VERSION ""

NS_ :

BS_:

BU_: ETH

BO_ 1445 DIR_alertLog: 8 Vector__XXX
 SG_ DIR_alertID M : 0|8@1+ (1,0) [0|0] "" Vector__XXX
 SG_ DIR_alertState : 15|1@1+ (1,0) [0|0] "" Vector__XXX
 SG_ DIR_a001_thermalWarning_H m1 : 16|1@1+ (1,0) [0|0] "" Vector__XXX
 SG_ DIR_a002_thermalWarning_H m2 : 16|1@1+ (1,0) [0|0] "" Vector__XXX
 SG_ DIR_a003_thermalWarning_H m3 : 16|1@1+ (1,0) [0|0] "" Vector__XXX
 SG_ DIR_a007_phaseAcurrent m7 : 16|8@1+ (8,0) [0|0] "" Vector__XXX
 SG_ DIR_a010_sccReset m10 : 16|1@1+ (1,0) [0|0] "" Vector__XXX
 SG_ DIR_a011_reason m11 : 16|3@1+ (1,0) [0|0] "" Vector__XXX
 SG_ DIR_a013_address m13 : 16|32@1+ (1,0) [0|0] "" Vector__XXX
 SG_ DIR_a014_motorSpeed m14 : 16|14@1- (2,0) [0|0] "" Vector__XXX
 SG_ DIR_a015_hwLatchTestFailed m15 : 16|1@1+ (1,0) [0|0] "" Vector__XXX
 SG_ DIR_a016_newSafeState m16 : 16|2@1+ (1,0) [0|0] "" Vector__XXX
 SG_ DIR_a024_vBat m24 : 16|8@1+ (2,0) [0|0] "" Vector__XXX
 SG_ DIR_a025_Ia m25 : 16|16@1- (0.1,0) [0|0] "" Vector__XXX
 SG_ DIR_a026_Ib m26 : 16|16@1- (0.1,0) [0|0] "" Vector__XXX
 SG_ DIR_a027_Ic m27 : 16|16@1- (0.1,0) [0|0] "" Vector__XXX
 SG_ DIR_a028_phaseAirms m28 : 16|16@1+ (1,0) [0|0] "" Vector__XXX
 SG_ DIR_a029_phaseBirms m29 : 16|16@1+ (1,0) [0|0] "" Vector__XXX
 SG_ DIR_a030_phaseCirms m30 : 16|16@1+ (1,0) [0|0] "" Vector__XXX
 SG_ DIR_a031_phaseAoffset m31 : 16|15@1- (0.002,0) [0|0] "" Vector__XXX
 SG_ DIR_a032_phaseBoffset m32 : 16|15@1- (0.002,0) [0|0] "" Vector__XXX
 SG_ DIR_a033_phaseAcurrent m33 : 16|16@1- (1,0) [0|0] "" Vector__XXX
 SG_ DIR_a034_phaseBcurrent m34 : 16|16@1- (1,0) [0|0] "" Vector__XXX
 SG_ DIR_a035_phaseAerror m35 : 16|1@1+ (1,0) [0|0] "" Vector__XXX
 SG_ DIR_a036_busVoltage m36 : 16|16@1+ (0.1,0) [0|0] "" Vector__XXX
 SG_ DIR_a037_busVoltage m37 : 16|16@1+ (0.1,0) [0|0] "" Vector__XXX
 SG_ DIR_a038_vBMS m38 : 16|13@1+ (0.2,0) [0|0] "" Vector__XXX
 SG_ DIR_a040_torque m40 : 16|1@1+ (1,0) [0|0] "" Vector__XXX
 SG_ DIR_a041_uartRxDataAvailable m41 : 16|1@1+ (1,0) [0|0] "" Vector__XXX
 SG_ DIR_a042_inletTemp m42 : 16|10@1+ (0.25,-60) [0|0] "" Vector__XXX
 SG_ DIR_a043_outletTemp m43 : 16|16@1- (0.1,0) [0|0] "" Vector__XXX
 SG_ DIR_a044_outletTemp m44 : 16|16@1- (0.1,0) [0|0] "" Vector__XXX
 SG_ DIR_a045_inletTemp m45 : 16|10@1+ (0.25,-60) [0|0] "" Vector__XXX
 SG_ DIR_a046_statorTemp1 m46 : 16|16@1- (0.1,0) [0|0] "" Vector__XXX
 SG_ DIR_a047_statorTemp1 m47 : 16|16@1- (0.1,0) [0|0] "" Vector__XXX
 SG_ DIR_a048_statorTemp2 m48 : 16|16@1- (0.1,0) [0|0] "" Vector__XXX
 SG_ DIR_a049_statorTemp1 m49 : 16|8@1- (1,80) [0|0] "" Vector__XXX
 SG_ DIR_a050_statorTemp1 m50 : 16|16@1- (0.1,0) [0|0] "" Vector__XXX
 SG_ DIR_a052_torque m52 : 16|1@1+ (1,0) [0|0] "" Vector__XXX
 SG_ DIR_a054_outletTemp m54 : 16|16@1- (0.1,0) [0|0] "" Vector__XXX
 SG_ DIR_a055_parameterDI m55 : 16|13@1- (0.25,0) [0|0] "" Vector__XXX
 SG_ DIR_a056_pcbTemp m56 : 16|16@1- (0.1,0) [0|0] "" Vector__XXX
 SG_ DIR_a057_pcbTemp m57 : 16|16@1- (0.1,0) [0|0] "" Vector__XXX
 SG_ DIR_a058_pcbTemp m58 : 16|10@1+ (0.25,-60) [0|0] "" Vector__XXX
 SG_ DIR_a059_heatsinkTemp m59 : 16|16@1- (0.1,0) [0|0] "" Vector__XXX
 SG_ DIR_a060_heatsinkTemp m60 : 16|16@1- (0.1,0) [0|0] "" Vector__XXX
 SG_ DIR_a061_sensor m61 : 16|2@1+ (1,0) [0|0] "" Vector__XXX
 SG_ DIR_a062_limpReason m62 : 16|6@1+ (1,0) [0|0] "" Vector__XXX
 SG_ DIR_a064_interventionType m64 : 16|4@1+ (1,0) [0|0] "" Vector__XXX
 SG_ DIR_a065_canID m65 : 16|16@1+ (1,0) [0|0] "" Vector__XXX
 SG_ DIR_a066_badValue1 m66 : 16|16@1+ (1,0) [0|0] "" Vector__XXX
 SG_ DIR_a067_canID m67 : 16|16@1+ (1,0) [0|0] "" Vector__XXX
 SG_ DIR_a069_motorSpeed m69 : 16|16@1- (1,0) [0|0] "" Vector__XXX
 SG_ DIR_a070_serviceDataId m70 : 16|16@1+ (1,0) [0|0] "" Vector__XXX
 SG_ DIR_a071_busVslopeLimit m71 : 16|16@1+ (0.1,0) [0|0] "" Vector__XXX
 SG_ DIR_a072_reason m72 : 16|2@1+ (1,0) [0|0] "" Vector__XXX
 SG_ DIR_a073_motorSpeedrpm m73 : 16|16@1- (1,0) [0|0] "" Vector__XXX
 SG_ DIR_a074_brazeFailCount m74 : 16|8@1+ (1,0) [0|0] "" Vector__XXX
 SG_ DIR_a075_motorSpeed m75 : 16|16@1+ (1,0) [0|0] "" Vector__XXX
 SG_ DIR_a076_lvSupplyV m76 : 16|16@1+ (0.001,0) [0|0] "" Vector__XXX
 SG_ DIR_a077_lvSupplyV m77 : 16|16@1+ (0.001,0) [0|0] "" Vector__XXX
 SG_ DIR_a078_adcRefChan m78 : 16|4@1+ (1,0) [0|0] "" Vector__XXX
 SG_ DIR_a079_adcRefChan m79 : 16|4@1+ (1,0) [0|0] "" Vector__XXX
 SG_ DIR_a084_lowDataValue m84 : 16|32@1+ (1,0) [0|0] "" Vector__XXX
 SG_ DIR_a087_gtwCarConfig m87 : 16|1@1+ (1,0) [0|0] "" Vector__XXX
 SG_ DIR_a088_uiChassisControl m88 : 16|1@1+ (1,0) [0|0] "" Vector__XXX
 SG_ DIR_a090_reason m90 : 16|1@1+ (1,0) [0|0] "" Vector__XXX
 SG_ DIR_a091_ESP_brakeTorque m91 : 16|1@1+ (1,0) [0|0] "" Vector__XXX
 SG_ DIR_a092_bmsStatus m92 : 16|1@1+ (1,0) [0|0] "" Vector__XXX
 SG_ DIR_a093_mailboxID m93 : 16|16@1+ (1,0) [0|0] "" Vector__XXX
 SG_ DIR_a094_canID m94 : 16|12@1+ (1,0) [0|0] "" Vector__XXX
 SG_ DIR_a095_mailboxID m95 : 16|16@1+ (1,0) [0|0] "" Vector__XXX
 SG_ DIR_a096_const_fast m96 : 16|1@1+ (1,0) [0|0] "" Vector__XXX
 SG_ DIR_a097_errorType m97 : 16|3@1+ (1,0) [0|0] "" Vector__XXX
 SG_ DIR_a098_pwmCount m98 : 16|16@1+ (1,0) [0|0] "" Vector__XXX
 SG_ DIR_a099_watchdogReset m99 : 16|1@1+ (1,0) [0|0] "" Vector__XXX
 SG_ DIR_a101_highDataValue m101 : 16|32@1+ (1,0) [0|0] "" Vector__XXX
 SG_ DIR_a103_fluidTorDeltaT m103 : 16|8@1- (2.0078740157480315,68.26771653543307) [0|0] "" Vector__XXX
 SG_ DIR_a107_fpgaVersion m107 : 16|16@1+ (1,0) [0|0] "" Vector__XXX
 SG_ DIR_a108_fromState m108 : 16|8@1+ (1,0) [0|0] "" Vector__XXX
 SG_ DIR_a110_EPBL_status m110 : 16|1@1+ (1,0) [0|0] "" Vector__XXX
 SG_ DIR_a111_phAcalib m111 : 16|16@1+ (1,0) [0|0] "" Vector__XXX
 SG_ DIR_a112_pwmSwitching m112 : 16|1@1+ (1,0) [0|0] "" Vector__XXX
 SG_ DIR_a113_heatsink1Temp m113 : 16|16@1- (0.1,0) [0|0] "" Vector__XXX
 SG_ DIR_a117_torque m117 : 16|1@1+ (1,0) [0|0] "" Vector__XXX
 SG_ DIR_a119_hvpFaults m119 : 16|1@1+ (1,0) [0|0] "" Vector__XXX
 SG_ DIR_a120_dcLinkInfo m120 : 16|1@1+ (1,0) [0|0] "" Vector__XXX
 SG_ DIR_a121_badRegReason m121 : 16|3@1+ (1,0) [0|0] "" Vector__XXX
 SG_ DIR_a122_taskID m122 : 16|5@1+ (1,0) [0|0] "" Vector__XXX
 SG_ DIR_a123_lossReason m123 : 16|3@1+ (1,0) [0|0] "" Vector__XXX
 SG_ DIR_a126_limpReason m126 : 16|6@1+ (1,0) [0|0] "" Vector__XXX
 SG_ DIR_a127_gpoReason m127 : 16|4@1+ (1,0) [0|0] "" Vector__XXX
 SG_ DIR_a128_expectedFPGAversion m128 : 16|16@1+ (1,0) [0|0] "" Vector__XXX
 SG_ DIR_a133_capacitorTemp m133 : 16|16@1- (0.1,0) [0|0] "" Vector__XXX
 SG_ DIR_a134_wheelSpeedDiffFrL m134 : 16|12@1- (0.0625,0) [0|0] "" Vector__XXX
 SG_ DIR_a136_spiError_BL m136 : 16|1@1+ (1,0) [0|0] "" Vector__XXX
 SG_ DIR_a142_lashAngle m142 : 16|10@1+ (0.06,0) [0|0] "" Vector__XXX
 SG_ DIR_a144_autopilot m144 : 16|1@1+ (1,0) [0|0] "" Vector__XXX
 SG_ DIR_a147_overtorque1UsedCount m147 : 16|8@1+ (1,0) [0|0] "" Vector__XXX
 SG_ DIR_a148_initialHeatsinkT m148 : 16|6@1+ (3,-40) [0|0] "" Vector__XXX
 SG_ DIR_a149_flow m149 : 16|8@1+ (0.1,0) [0|0] "" Vector__XXX
 SG_ DIR_a150_vBatRawMinusFiltered m150 : 16|10@1- (1,0) [0|0] "" Vector__XXX
 SG_ DIR_a151_torqueMotor m151 : 16|16@1- (0.25,0) [0|0] "" Vector__XXX
 SG_ DIR_a152_errorType m152 : 16|3@1+ (1,0) [0|0] "" Vector__XXX
 SG_ DIR_a153_oilFlow m153 : 16|8@1+ (0.1,0) [0|0] "" Vector__XXX
 SG_ DIR_a154_motorRPM m154 : 16|16@1- (1,0) [0|0] "" Vector__XXX
 SG_ DIR_a155_sensors m155 : 16|1@1+ (1,0) [0|0] "" Vector__XXX
 SG_ DIR_a156_initialSafeState m156 : 16|2@1+ (1,0) [0|0] "" Vector__XXX
 SG_ DIR_a157_RCM_inertial1 m157 : 16|1@1+ (1,0) [0|0] "" Vector__XXX
 SG_ DIR_a158_IBST_party1 m158 : 16|1@1+ (1,0) [0|0] "" Vector__XXX
 SG_ DIR_a160_vBatRawMinusFiltered m160 : 16|10@1- (1,0) [0|0] "" Vector__XXX
 SG_ DIR_a161_EPAS3P_sysStatus m161 : 16|1@1+ (1,0) [0|0] "" Vector__XXX
 SG_ DIR_a162_normalFetBurnIn m162 : 16|8@1+ (2,0) [0|0] "" Vector__XXX
 SG_ DIR_a172_statorTemp1 m172 : 16|16@1- (0.1,0) [0|0] "" Vector__XXX
 SG_ DIR_a173_phaseADetected m173 : 16|1@1+ (1,0) [0|0] "" Vector__XXX
 SG_ DIR_a177_storedValue m177 : 16|16@1+ (0.0001,0) [0|0] "" Vector__XXX
 SG_ DIR_a202_reason m202 : 16|4@1+ (1,0) [0|0] "" Vector__XXX
 SG_ DIR_a225_hs1Implausible m225 : 16|1@1+ (1,0) [0|0] "" Vector__XXX
 SG_ DIR_a229_vBMS m229 : 16|13@1+ (0.2,0) [0|0] "" Vector__XXX
 SG_ DIR_a233_missedMsgCount m233 : 16|16@1+ (1,0) [0|0] "" Vector__XXX
 SG_ DIR_a234_PCS_dcdcStatus m234 : 16|1@1+ (1,0) [0|0] "" Vector__XXX
 SG_ DIR_a236_states m236 : 16|1@1+ (1,0) [0|0] "" Vector__XXX
 SG_ DIR_a240_shortedSwitches m240 : 16|6@1+ (1,0) [0|0] "" Vector__XXX
 SG_ DIR_a241_statorEndWindingTemp m241 : 16|8@1- (1,88) [0|0] "" Vector__XXX
 SG_ DIR_a242_RotorOffset m242 : 16|1@1+ (1,0) [0|0] "" Vector__XXX
 SG_ DIR_a243_logId m243 : 16|4@1+ (1,0) [0|0] "" Vector__XXX
 SG_ DIR_a244_desatHighSide m244 : 16|1@1+ (1,0) [0|0] "" Vector__XXX
 SG_ DIR_a245_singleSwitchShort m245 : 16|1@1+ (1,0) [0|0] "" Vector__XXX
 SG_ DIR_a246_atSpeedDIResetCount m246 : 16|4@1+ (1,-1) [0|0] "" Vector__XXX
 SG_ DIR_a247_rotorOffsetEst m247 : 16|10@1- (0.05,0) [0|0] "" Vector__XXX
 SG_ DIR_a249_statorResistanceEst m249 : 16|11@1+ (5e-05,0) [0|0] "" Vector__XXX
 SG_ DIR_a250_voltage m250 : 16|12@1+ (0.01,0) [0|0] "" Vector__XXX
 SG_ DIR_a251_oilFlow m251 : 16|8@1+ (0.1,0) [0|0] "" Vector__XXX
 SG_ DIR_a253_voltage m253 : 16|14@1+ (0.002,0) [0|0] "" Vector__XXX
 SG_ DIR_a254_voltage m254 : 16|14@1+ (0.005,0) [0|0] "" Vector__XXX
 SG_ DIR_a001_thermalShutdown_H m1 : 17|1@1+ (1,0) [0|0] "" Vector__XXX
 SG_ DIR_a002_thermalShutdown_H m2 : 17|1@1+ (1,0) [0|0] "" Vector__XXX
 SG_ DIR_a003_thermalShutdown_H m3 : 17|1@1+ (1,0) [0|0] "" Vector__XXX
 SG_ DIR_a010_hibernate m10 : 17|1@1+ (1,0) [0|0] "" Vector__XXX
 SG_ DIR_a015_hwOpenCircuitTestFailed m15 : 17|1@1+ (1,0) [0|0] "" Vector__XXX
 SG_ DIR_a035_phaseBerror m35 : 17|1@1+ (1,0) [0|0] "" Vector__XXX
 SG_ DIR_a040_capability m40 : 17|1@1+ (1,0) [0|0] "" Vector__XXX
 SG_ DIR_a041_SDC_status_MIA m41 : 17|1@1+ (1,0) [0|0] "" Vector__XXX
 SG_ DIR_a052_capability m52 : 17|1@1+ (1,0) [0|0] "" Vector__XXX
 SG_ DIR_a087_gtwTime m87 : 17|1@1+ (1,0) [0|0] "" Vector__XXX
 SG_ DIR_a088_uiCruiseControl m88 : 17|1@1+ (1,0) [0|0] "" Vector__XXX
 SG_ DIR_a091_ESP_wheelSpeeds m91 : 17|1@1+ (1,0) [0|0] "" Vector__XXX
 SG_ DIR_a092_bmsDriveLimits m92 : 17|1@1+ (1,0) [0|0] "" Vector__XXX
 SG_ DIR_a096_text_fast m96 : 17|1@1+ (1,0) [0|0] "" Vector__XXX
 SG_ DIR_a099_thread1Hz m99 : 17|1@1+ (1,0) [0|0] "" Vector__XXX
 SG_ DIR_a110_EPBR_status m110 : 17|1@1+ (1,0) [0|0] "" Vector__XXX
 SG_ DIR_a112_gdicResetLine m112 : 17|1@1+ (1,0) [0|0] "" Vector__XXX
 SG_ DIR_a117_slaveCommand m117 : 17|1@1+ (1,0) [0|0] "" Vector__XXX
 SG_ DIR_a136_crcError_BL m136 : 17|1@1+ (1,0) [0|0] "" Vector__XXX
 SG_ DIR_a144_chassisType m144 : 17|1@1+ (1,0) [0|0] "" Vector__XXX
 SG_ DIR_a155_coolant m155 : 17|1@1+ (1,0) [0|0] "" Vector__XXX
 SG_ DIR_a157_RCM_inertial2 m157 : 17|1@1+ (1,0) [0|0] "" Vector__XXX
 SG_ DIR_a158_BUS1_IBST_status m158 : 17|1@1+ (1,0) [0|0] "" Vector__XXX
 SG_ DIR_a161_EPAS3P_angleCalib m161 : 17|1@1+ (1,0) [0|0] "" Vector__XXX
 SG_ DIR_a173_phaseBDetected m173 : 17|1@1+ (1,0) [0|0] "" Vector__XXX
 SG_ DIR_a225_hs2Implausible m225 : 17|1@1+ (1,0) [0|0] "" Vector__XXX
 SG_ DIR_a242_RotorFlux m242 : 17|1@1+ (1,0) [0|0] "" Vector__XXX
 SG_ DIR_a244_desatLowSide m244 : 17|1@1+ (1,0) [0|0] "" Vector__XXX
 SG_ DIR_a245_busShort m245 : 17|1@1+ (1,0) [0|0] "" Vector__XXX
 SG_ DIR_a001_undervoltVL_H m1 : 18|1@1+ (1,0) [0|0] "" Vector__XXX
 SG_ DIR_a002_undervoltVL_H m2 : 18|1@1+ (1,0) [0|0] "" Vector__XXX
 SG_ DIR_a003_undervoltVL_H m3 : 18|1@1+ (1,0) [0|0] "" Vector__XXX
 SG_ DIR_a010_hwBist m10 : 18|1@1+ (1,0) [0|0] "" Vector__XXX
 SG_ DIR_a015_hwIrTestFailed m15 : 18|1@1+ (1,0) [0|0] "" Vector__XXX
 SG_ DIR_a016_oldSafeState m16 : 18|2@1+ (1,0) [0|0] "" Vector__XXX
 SG_ DIR_a035_phaseCerror m35 : 18|1@1+ (1,0) [0|0] "" Vector__XXX
 SG_ DIR_a040_power m40 : 18|1@1+ (1,0) [0|0] "" Vector__XXX
 SG_ DIR_a041_diUartRxVersion m41 : 18|4@1+ (1,0) [0|0] "" Vector__XXX
 SG_ DIR_a052_power m52 : 18|1@1+ (1,0) [0|0] "" Vector__XXX
 SG_ DIR_a061_reason m61 : 18|1@1+ (1,0) [0|0] "" Vector__XXX
 SG_ DIR_a087_gtwUpdateStatus m87 : 18|1@1+ (1,0) [0|0] "" Vector__XXX
 SG_ DIR_a088_uiDriverAssistMapData m88 : 18|1@1+ (1,0) [0|0] "" Vector__XXX
 SG_ DIR_a090_state m90 : 18|1@1+ (1,0) [0|0] "" Vector__XXX
 SG_ DIR_a091_ESP_wheelRotation m91 : 18|1@1+ (1,0) [0|0] "" Vector__XXX
 SG_ DIR_a092_bmsHvBusStatus m92 : 18|1@1+ (1,0) [0|0] "" Vector__XXX
 SG_ DIR_a096_text_flash m96 : 18|1@1+ (1,0) [0|0] "" Vector__XXX
 SG_ DIR_a099_thread10Hz m99 : 18|1@1+ (1,0) [0|0] "" Vector__XXX
 SG_ DIR_a110_EPBL_autonomyHealth m110 : 18|1@1+ (1,0) [0|0] "" Vector__XXX
 SG_ DIR_a112_allOffSafeState m112 : 18|1@1+ (1,0) [0|0] "" Vector__XXX
 SG_ DIR_a117_power m117 : 18|1@1+ (1,0) [0|0] "" Vector__XXX
 SG_ DIR_a136_busyError_BL m136 : 18|1@1+ (1,0) [0|0] "" Vector__XXX
 SG_ DIR_a144_drivetrainType m144 : 18|1@1+ (1,0) [0|0] "" Vector__XXX
 SG_ DIR_a155_LVPowerState m155 : 18|1@1+ (1,0) [0|0] "" Vector__XXX
 SG_ DIR_a156_observation m156 : 18|4@1+ (1,0) [0|0] "" Vector__XXX
 SG_ DIR_a158_BUS2_IBST_status m158 : 18|1@1+ (1,0) [0|0] "" Vector__XXX
 SG_ DIR_a173_phaseCDetected m173 : 18|1@1+ (1,0) [0|0] "" Vector__XXX
 SG_ DIR_a225_fluidImplausible m225 : 18|1@1+ (1,0) [0|0] "" Vector__XXX
 SG_ DIR_a242_ResolverError m242 : 18|1@1+ (1,0) [0|0] "" Vector__XXX
 SG_ DIR_a244_singleSwitchShort m244 : 18|1@1+ (1,0) [0|0] "" Vector__XXX
 SG_ DIR_a245_unsuccessfulSafeState m245 : 18|1@1+ (1,0) [0|0] "" Vector__XXX
 SG_ DIR_a001_undervoltVH_H m1 : 19|1@1+ (1,0) [0|0] "" Vector__XXX
 SG_ DIR_a002_undervoltVH_H m2 : 19|1@1+ (1,0) [0|0] "" Vector__XXX
 SG_ DIR_a003_undervoltVH_H m3 : 19|1@1+ (1,0) [0|0] "" Vector__XXX
 SG_ DIR_a010_nmiWatchdog m10 : 19|1@1+ (1,0) [0|0] "" Vector__XXX
 SG_ DIR_a011_phaseAHigh m11 : 19|1@1+ (1,0) [0|0] "" Vector__XXX
 SG_ DIR_a015_swHighsideTestFailed m15 : 19|1@1+ (1,0) [0|0] "" Vector__XXX
 SG_ DIR_a035_standbyCurrent m35 : 19|1@1+ (1,0) [0|0] "" Vector__XXX
 SG_ DIR_a040_status m40 : 19|1@1+ (1,0) [0|0] "" Vector__XXX
 SG_ DIR_a052_status m52 : 19|1@1+ (1,0) [0|0] "" Vector__XXX
 SG_ DIR_a087_gearControl m87 : 19|1@1+ (1,0) [0|0] "" Vector__XXX
 SG_ DIR_a088_uiPowertrainControl m88 : 19|1@1+ (1,0) [0|0] "" Vector__XXX
 SG_ DIR_a090_locState m90 : 19|1@1+ (1,0) [0|0] "" Vector__XXX
 SG_ DIR_a091_ESP_motorLimits m91 : 19|1@1+ (1,0) [0|0] "" Vector__XXX
 SG_ DIR_a092_bmsPowerAvailable m92 : 19|1@1+ (1,0) [0|0] "" Vector__XXX
 SG_ DIR_a096_mem_data m96 : 19|1@1+ (1,0) [0|0] "" Vector__XXX
 SG_ DIR_a099_thread100Hz m99 : 19|1@1+ (1,0) [0|0] "" Vector__XXX
 SG_ DIR_a110_EPBR_autonomyHealth m110 : 19|1@1+ (1,0) [0|0] "" Vector__XXX
 SG_ DIR_a112_ls3psSafeState m112 : 19|1@1+ (1,0) [0|0] "" Vector__XXX
 SG_ DIR_a117_slaveCommand2 m117 : 19|1@1+ (1,0) [0|0] "" Vector__XXX
 SG_ DIR_a121_torqueDelta m121 : 19|13@1- (0.25,0) [0|0] "" Vector__XXX
 SG_ DIR_a123_busVoltage m123 : 19|6@1+ (4,250) [0|0] "" Vector__XXX
 SG_ DIR_a136_spiError_BH m136 : 19|1@1+ (1,0) [0|0] "" Vector__XXX
 SG_ DIR_a144_packEnergy m144 : 19|1@1+ (1,0) [0|0] "" Vector__XXX
 SG_ DIR_a155_vehicleStatus m155 : 19|1@1+ (1,0) [0|0] "" Vector__XXX
 SG_ DIR_a173_phaseAPeriodViolation1 m173 : 19|1@1+ (1,0) [0|0] "" Vector__XXX
 SG_ DIR_a225_hsDeltaImplausible m225 : 19|1@1+ (1,0) [0|0] "" Vector__XXX
 SG_ DIR_a244_flybackFault m244 : 19|1@1+ (1,0) [0|0] "" Vector__XXX
 SG_ DIR_a245_lowSpeedShort m245 : 19|1@1+ (1,0) [0|0] "" Vector__XXX
 SG_ DIR_a001_sense_H m1 : 20|1@1+ (1,0) [0|0] "" Vector__XXX
 SG_ DIR_a002_sense_H m2 : 20|1@1+ (1,0) [0|0] "" Vector__XXX
 SG_ DIR_a003_sense_H m3 : 20|1@1+ (1,0) [0|0] "" Vector__XXX
 SG_ DIR_a010_watchdog m10 : 20|1@1+ (1,0) [0|0] "" Vector__XXX
 SG_ DIR_a011_phaseALow m11 : 20|1@1+ (1,0) [0|0] "" Vector__XXX
 SG_ DIR_a015_swLowsideTestFailed m15 : 20|1@1+ (1,0) [0|0] "" Vector__XXX
 SG_ DIR_a016_gateDriveFaultLine m16 : 20|1@1+ (1,0) [0|0] "" Vector__XXX
 SG_ DIR_a035_unbalancedCurrent m35 : 20|1@1+ (1,0) [0|0] "" Vector__XXX
 SG_ DIR_a040_capability2 m40 : 20|1@1+ (1,0) [0|0] "" Vector__XXX
 SG_ DIR_a052_capability2 m52 : 20|1@1+ (1,0) [0|0] "" Vector__XXX
 SG_ DIR_a064_torqueCmdState m64 : 20|4@1+ (1,0) [0|0] "" Vector__XXX
 SG_ DIR_a087_carState m87 : 20|1@1+ (1,0) [0|0] "" Vector__XXX
 SG_ DIR_a088_uiVehicleModes m88 : 20|1@1+ (1,0) [0|0] "" Vector__XXX
 SG_ DIR_a090_state2 m90 : 20|1@1+ (1,0) [0|0] "" Vector__XXX
 SG_ DIR_a091_ESP_offsets m91 : 20|1@1+ (1,0) [0|0] "" Vector__XXX
 SG_ DIR_a092_bmsBmbMinMax m92 : 20|1@1+ (1,0) [0|0] "" Vector__XXX
 SG_ DIR_a096_mem_regs m96 : 20|1@1+ (1,0) [0|0] "" Vector__XXX
 SG_ DIR_a099_thread1kHz m99 : 20|1@1+ (1,0) [0|0] "" Vector__XXX
 SG_ DIR_a112_hs3psSafeState m112 : 20|1@1+ (1,0) [0|0] "" Vector__XXX
 SG_ DIR_a117_speed m117 : 20|1@1+ (1,0) [0|0] "" Vector__XXX
 SG_ DIR_a136_crcError_BH m136 : 20|1@1+ (1,0) [0|0] "" Vector__XXX
 SG_ DIR_a144_packPerformanceDeviation m144 : 20|1@1+ (1,0) [0|0] "" Vector__XXX
 SG_ DIR_a155_status m155 : 20|1@1+ (1,0) [0|0] "" Vector__XXX
 SG_ DIR_a173_phaseAPeriodViolation2 m173 : 20|1@1+ (1,0) [0|0] "" Vector__XXX
 SG_ DIR_a202_movement m202 : 20|9@1+ (0.005,0) [0|0] "" Vector__XXX
 SG_ DIR_a244_postShortTestFailed m244 : 20|1@1+ (1,0) [0|0] "" Vector__XXX
 SG_ DIR_a245_doubleSwitchShort m245 : 20|1@1+ (1,0) [0|0] "" Vector__XXX
 SG_ DIR_a246_didPMCauseASC m246 : 20|1@1+ (1,0) [0|0] "" Vector__XXX
 SG_ DIR_a001_desat_H m1 : 21|1@1+ (1,0) [0|0] "" Vector__XXX
 SG_ DIR_a002_desat_H m2 : 21|1@1+ (1,0) [0|0] "" Vector__XXX
 SG_ DIR_a003_desat_H m3 : 21|1@1+ (1,0) [0|0] "" Vector__XXX
 SG_ DIR_a010_clockFailNmi m10 : 21|1@1+ (1,0) [0|0] "" Vector__XXX
 SG_ DIR_a011_phaseBHigh m11 : 21|1@1+ (1,0) [0|0] "" Vector__XXX
 SG_ DIR_a015_armedFailed m15 : 21|1@1+ (1,0) [0|0] "" Vector__XXX
 SG_ DIR_a016_ascMonitor m16 : 21|1@1+ (1,0) [0|0] "" Vector__XXX
 SG_ DIR_a035_wontMoveCurrent m35 : 21|1@1+ (1,0) [0|0] "" Vector__XXX
 SG_ DIR_a040_hvStatus m40 : 21|1@1+ (1,0) [0|0] "" Vector__XXX
 SG_ DIR_a052_hvStatus m52 : 21|1@1+ (1,0) [0|0] "" Vector__XXX
 SG_ DIR_a088_uiTrackModeSettings m88 : 21|1@1+ (1,0) [0|0] "" Vector__XXX
 SG_ DIR_a090_state4 m90 : 21|1@1+ (1,0) [0|0] "" Vector__XXX
 SG_ DIR_a091_ESP_status m91 : 21|1@1+ (1,0) [0|0] "" Vector__XXX
 SG_ DIR_a092_bmsSocStatus m92 : 21|1@1+ (1,0) [0|0] "" Vector__XXX
 SG_ DIR_a096_boot_flash m96 : 21|1@1+ (1,0) [0|0] "" Vector__XXX
 SG_ DIR_a112_modulationIndex m112 : 21|11@1+ (0.00048828125,0) [0|0] "" Vector__XXX
 SG_ DIR_a117_chassisControl m117 : 21|1@1+ (1,0) [0|0] "" Vector__XXX
 SG_ DIR_a136_busyError_BH m136 : 21|1@1+ (1,0) [0|0] "" Vector__XXX
 SG_ DIR_a144_performancePackage m144 : 21|1@1+ (1,0) [0|0] "" Vector__XXX
 SG_ DIR_a155_leftDoorStatus m155 : 21|1@1+ (1,0) [0|0] "" Vector__XXX
 SG_ DIR_a173_phaseBPeriodViolation1 m173 : 21|1@1+ (1,0) [0|0] "" Vector__XXX
 SG_ DIR_a244_udsSelfTest m244 : 21|1@1+ (1,0) [0|0] "" Vector__XXX
 SG_ DIR_a245_gateDriveSupplyFault m245 : 21|1@1+ (1,0) [0|0] "" Vector__XXX
 SG_ DIR_a246_currentSensorRational m246 : 21|1@1+ (1,0) [0|0] "" Vector__XXX
 SG_ DIR_a001_overvoltVL_H m1 : 22|1@1+ (1,0) [0|0] "" Vector__XXX
 SG_ DIR_a002_overvoltVL_H m2 : 22|1@1+ (1,0) [0|0] "" Vector__XXX
 SG_ DIR_a003_overvoltVL_H m3 : 22|1@1+ (1,0) [0|0] "" Vector__XXX
 SG_ DIR_a010_ramUncErrorNmi m10 : 22|1@1+ (1,0) [0|0] "" Vector__XXX
 SG_ DIR_a011_phaseBLow m11 : 22|1@1+ (1,0) [0|0] "" Vector__XXX
 SG_ DIR_a015_lightSenseIrrational m15 : 22|1@1+ (1,0) [0|0] "" Vector__XXX
 SG_ DIR_a016_uncontrolledRegenZone m16 : 22|1@1+ (1,0) [0|0] "" Vector__XXX
 SG_ DIR_a035_reportingPhase m35 : 22|2@1+ (1,0) [0|0] "" Vector__XXX
 SG_ DIR_a040_temperature m40 : 22|1@1+ (1,0) [0|0] "" Vector__XXX
 SG_ DIR_a052_temperature m52 : 22|1@1+ (1,0) [0|0] "" Vector__XXX
 SG_ DIR_a088_mcuDriverLimits m88 : 22|1@1+ (1,0) [0|0] "" Vector__XXX
 SG_ DIR_a091_ESP_party3 m91 : 22|1@1+ (1,0) [0|0] "" Vector__XXX
 SG_ DIR_a092_bmsThermalStatus m92 : 22|1@1+ (1,0) [0|0] "" Vector__XXX
 SG_ DIR_a117_systemStatus m117 : 22|1@1+ (1,0) [0|0] "" Vector__XXX
 SG_ DIR_a136_spiError_CL m136 : 22|1@1+ (1,0) [0|0] "" Vector__XXX
 SG_ DIR_a144_vdcType m144 : 22|1@1+ (1,0) [0|0] "" Vector__XXX
 SG_ DIR_a148_initialJunctionT m148 : 22|6@1+ (3,-40) [0|0] "" Vector__XXX
 SG_ DIR_a155_rightDoorStatus m155 : 22|1@1+ (1,0) [0|0] "" Vector__XXX
 SG_ DIR_a156_phaseAPolarity m156 : 22|2@1+ (1,0) [0|0] "" Vector__XXX
 SG_ DIR_a173_phaseBPeriodViolation2 m173 : 22|1@1+ (1,0) [0|0] "" Vector__XXX
 SG_ DIR_a240_primaryPattern m240 : 22|6@1+ (1,0) [0|0] "" Vector__XXX
 SG_ DIR_a245_unexpectedCurrent m245 : 22|1@1+ (1,0) [0|0] "" Vector__XXX
 SG_ DIR_a246_observerDetectedLS3PS m246 : 22|1@1+ (1,0) [0|0] "" Vector__XXX
 SG_ DIR_a001_overvoltVH_H m1 : 23|1@1+ (1,0) [0|0] "" Vector__XXX
 SG_ DIR_a002_overvoltVH_H m2 : 23|1@1+ (1,0) [0|0] "" Vector__XXX
 SG_ DIR_a003_overvoltVH_H m3 : 23|1@1+ (1,0) [0|0] "" Vector__XXX
 SG_ DIR_a010_flashUncErrorNmi m10 : 23|1@1+ (1,0) [0|0] "" Vector__XXX
 SG_ DIR_a011_phaseCHigh m11 : 23|1@1+ (1,0) [0|0] "" Vector__XXX
 SG_ DIR_a016_pedalMonitorPreWatchdog m16 : 23|1@1+ (1,0) [0|0] "" Vector__XXX
 SG_ DIR_a088_vehicleControl2 m88 : 23|1@1+ (1,0) [0|0] "" Vector__XXX
 SG_ DIR_a091_ESP_redundantBrakingStatus m91 : 23|1@1+ (1,0) [0|0] "" Vector__XXX
 SG_ DIR_a092_bmsCtrStatus m92 : 23|1@1+ (1,0) [0|0] "" Vector__XXX
 SG_ DIR_a117_temperature m117 : 23|1@1+ (1,0) [0|0] "" Vector__XXX
 SG_ DIR_a136_crcError_CL m136 : 23|1@1+ (1,0) [0|0] "" Vector__XXX
 SG_ DIR_a144_brakeHWType m144 : 23|1@1+ (1,0) [0|0] "" Vector__XXX
 SG_ DIR_a155_vcleftSwitchStatus m155 : 23|1@1+ (1,0) [0|0] "" Vector__XXX
 SG_ DIR_a173_phaseCPeriodViolation1 m173 : 23|1@1+ (1,0) [0|0] "" Vector__XXX
 SG_ DIR_a246_hvIsGood m246 : 23|1@1+ (1,0) [0|0] "" Vector__XXX
 SG_ DIR_a001_undervoltVCC_H m1 : 24|1@1+ (1,0) [0|0] "" Vector__XXX
 SG_ DIR_a002_undervoltVCC_H m2 : 24|1@1+ (1,0) [0|0] "" Vector__XXX
 SG_ DIR_a003_undervoltVCC_H m3 : 24|1@1+ (1,0) [0|0] "" Vector__XXX
 SG_ DIR_a007_phaseBcurrent m7 : 24|8@1+ (8,0) [0|0] "" Vector__XXX
 SG_ DIR_a010_cpu1signMismatchNmi m10 : 24|1@1+ (1,0) [0|0] "" Vector__XXX
 SG_ DIR_a011_phaseCLow m11 : 24|1@1+ (1,0) [0|0] "" Vector__XXX
 SG_ DIR_a015_lightSenseV m15 : 24|6@1+ (0.1,0) [0|0] "" Vector__XXX
 SG_ DIR_a016_motorRPM m16 : 24|16@1- (1,0) [0|0] "" Vector__XXX
 SG_ DIR_a024_failReason m24 : 24|3@1+ (1,0) [0|0] "" Vector__XXX
 SG_ DIR_a035_noDriveCurrent m35 : 24|1@1+ (1,0) [0|0] "" Vector__XXX
 SG_ DIR_a041_sdcUartRxVersion m41 : 24|4@1+ (1,0) [0|0] "" Vector__XXX
 SG_ DIR_a049_statorTemp2 m49 : 24|8@1- (1,80) [0|0] "" Vector__XXX
 SG_ DIR_a061_phTemp m61 : 24|16@1- (0.1,0) [0|0] "" Vector__XXX
 SG_ DIR_a074_speed1Type m74 : 24|2@1+ (1,0) [0|0] "" Vector__XXX
 SG_ DIR_a078_adcRefLowAvg m78 : 24|16@1+ (1,0) [0|0] "" Vector__XXX
 SG_ DIR_a079_adcRefHighAvg m79 : 24|16@1+ (1,0) [0|0] "" Vector__XXX
 SG_ DIR_a088_semiControls m88 : 24|1@1+ (1,0) [0|0] "" Vector__XXX
 SG_ DIR_a092_bmsVoltageRegGain m92 : 24|1@1+ (1,0) [0|0] "" Vector__XXX
 SG_ DIR_a096_word1 m96 : 24|16@1+ (1,0) [0|0] "" Vector__XXX
 SG_ DIR_a097_lineNumber m97 : 24|16@1+ (1,0) [0|0] "" Vector__XXX
 SG_ DIR_a099_cpuUsage1Hz m99 : 24|8@1+ (1,0) [0|0] "" Vector__XXX
 SG_ DIR_a103_noFlowDetected m103 : 24|1@1+ (1,0) [0|0] "" Vector__XXX
 SG_ DIR_a108_toState m108 : 24|8@1+ (1,0) [0|0] "" Vector__XXX
 SG_ DIR_a117_vehicle m117 : 24|1@1+ (1,0) [0|0] "" Vector__XXX
 SG_ DIR_a122_stackUsed m122 : 24|16@1+ (1,0) [0|0] "" Vector__XXX
 SG_ DIR_a127_temp m127 : 24|16@1- (0.1,0) [0|0] "" Vector__XXX
 SG_ DIR_a136_busyError_CL m136 : 24|1@1+ (1,0) [0|0] "" Vector__XXX
 SG_ DIR_a144_inverterHardware m144 : 24|1@1+ (1,0) [0|0] "" Vector__XXX
 SG_ DIR_a147_overtorque2UsedCount m147 : 24|10@1+ (1,0) [0|0] "" Vector__XXX
 SG_ DIR_a149_voltage m149 : 24|8@1+ (0.1,0) [0|0] "" Vector__XXX
 SG_ DIR_a152_frameId m152 : 24|8@1+ (1,0) [0|0] "" Vector__XXX
 SG_ DIR_a153_oilTemperature m153 : 24|8@1+ (1,-40) [0|0] "" Vector__XXX
 SG_ DIR_a155_restraintStatus m155 : 24|1@1+ (1,0) [0|0] "" Vector__XXX
 SG_ DIR_a156_phaseBPolarity m156 : 24|2@1+ (1,0) [0|0] "" Vector__XXX
 SG_ DIR_a162_additionalFetBurnIn m162 : 24|8@1+ (2,0) [0|0] "" Vector__XXX
 SG_ DIR_a173_phaseCPeriodViolation2 m173 : 24|1@1+ (1,0) [0|0] "" Vector__XXX
 SG_ DIR_a241_rotorMaxMagnetTemp m241 : 24|8@1- (1,88) [0|0] "" Vector__XXX
 SG_ DIR_a243_triggerEvent m243 : 24|6@1+ (1,0) [0|0] "" Vector__XXX
 SG_ DIR_a244_irSensorV m244 : 24|6@1+ (0.1,0) [0|0] "" Vector__XXX
 SG_ DIR_a246_lvIsGood m246 : 24|1@1+ (1,0) [0|0] "" Vector__XXX
 SG_ DIR_a251_oilTemperature m251 : 24|8@1+ (1,-40) [0|0] "" Vector__XXX
 SG_ DIR_a001_asynchStop_H m1 : 25|1@1+ (1,0) [0|0] "" Vector__XXX
 SG_ DIR_a002_asynchStop_H m2 : 25|1@1+ (1,0) [0|0] "" Vector__XXX
 SG_ DIR_a003_asynchStop_H m3 : 25|1@1+ (1,0) [0|0] "" Vector__XXX
 SG_ DIR_a010_cpu2signMismatchNmi m10 : 25|1@1+ (1,0) [0|0] "" Vector__XXX
 SG_ DIR_a011_regAddress m11 : 25|5@1+ (1,0) [0|0] "" Vector__XXX
 SG_ DIR_a035_phaseDifference m35 : 25|7@1+ (1,0) [0|0] "" Vector__XXX
 SG_ DIR_a088_uiDriveSystemsDebug m88 : 25|1@1+ (1,0) [0|0] "" Vector__XXX
 SG_ DIR_a092_bmsPackConfig m92 : 25|1@1+ (1,0) [0|0] "" Vector__XXX
 SG_ DIR_a103_lowFlowDetected m103 : 25|1@1+ (1,0) [0|0] "" Vector__XXX
 SG_ DIR_a123_badFlux m123 : 25|7@1+ (0.0015,0) [0|0] "" Vector__XXX
 SG_ DIR_a136_spiError_CH m136 : 25|1@1+ (1,0) [0|0] "" Vector__XXX
 SG_ DIR_a144_cabinPTCHeaterType m144 : 25|1@1+ (1,0) [0|0] "" Vector__XXX
 SG_ DIR_a155_systemStatus m155 : 25|1@1+ (1,0) [0|0] "" Vector__XXX
 SG_ DIR_a246_codeBranch m246 : 25|2@1+ (1,0) [0|0] "" Vector__XXX
 SG_ DIR_a001_remoteRegError_H m1 : 26|1@1+ (1,0) [0|0] "" Vector__XXX
 SG_ DIR_a002_remoteRegError_H m2 : 26|1@1+ (1,0) [0|0] "" Vector__XXX
 SG_ DIR_a003_remoteRegError_H m3 : 26|1@1+ (1,0) [0|0] "" Vector__XXX
 SG_ DIR_a010_pieVectErrorNmi m10 : 26|1@1+ (1,0) [0|0] "" Vector__XXX
 SG_ DIR_a042_outletTemp m42 : 26|10@1+ (0.25,-60) [0|0] "" Vector__XXX
 SG_ DIR_a045_outletTemp m45 : 26|10@1+ (0.25,-60) [0|0] "" Vector__XXX
 SG_ DIR_a058_outletTemp m58 : 26|10@1+ (0.25,-60) [0|0] "" Vector__XXX
 SG_ DIR_a074_speed2Type m74 : 26|2@1+ (1,0) [0|0] "" Vector__XXX
 SG_ DIR_a092_bmsSystemStatus m92 : 26|1@1+ (1,0) [0|0] "" Vector__XXX
 SG_ DIR_a103_fluidImplausible m103 : 26|1@1+ (1,0) [0|0] "" Vector__XXX
 SG_ DIR_a136_crcError_CH m136 : 26|1@1+ (1,0) [0|0] "" Vector__XXX
 SG_ DIR_a144_frunkLatchType m144 : 26|1@1+ (1,0) [0|0] "" Vector__XXX
 SG_ DIR_a156_phaseCPolarity m156 : 26|2@1+ (1,0) [0|0] "" Vector__XXX
 SG_ DIR_a001_undervoltVDD_H m1 : 27|1@1+ (1,0) [0|0] "" Vector__XXX
 SG_ DIR_a002_undervoltVDD_H m2 : 27|1@1+ (1,0) [0|0] "" Vector__XXX
 SG_ DIR_a003_undervoltVDD_H m3 : 27|1@1+ (1,0) [0|0] "" Vector__XXX
 SG_ DIR_a010_sysDbgNmi m10 : 27|1@1+ (1,0) [0|0] "" Vector__XXX
 SG_ DIR_a024_state m24 : 27|4@1+ (1,0) [0|0] "" Vector__XXX
 SG_ DIR_a103_inverterTemp m103 : 27|8@1- (2.0078740157480315,68.26771653543307) [0|0] "" Vector__XXX
 SG_ DIR_a136_busyError_CH m136 : 27|1@1+ (1,0) [0|0] "" Vector__XXX
 SG_ DIR_a144_platformMaxBusVoltage m144 : 27|1@1+ (1,0) [0|0] "" Vector__XXX
 SG_ DIR_a155_liftgateStatus m155 : 27|1@1+ (1,0) [0|0] "" Vector__XXX
 SG_ DIR_a001_overvoltVDD_H m1 : 28|1@1+ (1,0) [0|0] "" Vector__XXX
 SG_ DIR_a002_overvoltVDD_H m2 : 28|1@1+ (1,0) [0|0] "" Vector__XXX
 SG_ DIR_a003_overvoltVDD_H m3 : 28|1@1+ (1,0) [0|0] "" Vector__XXX
 SG_ DIR_a010_rlNmi m10 : 28|1@1+ (1,0) [0|0] "" Vector__XXX
 SG_ DIR_a094_errorType m94 : 28|3@1+ (1,0) [0|0] "" Vector__XXX
 SG_ DIR_a134_wheelSpeedDiffFrR m134 : 28|12@1- (0.0625,0) [0|0] "" Vector__XXX
 SG_ DIR_a136_spiError_AL m136 : 28|1@1+ (1,0) [0|0] "" Vector__XXX
 SG_ DIR_a144_oilPump1HwType m144 : 28|1@1+ (1,0) [0|0] "" Vector__XXX
 SG_ DIR_a148_timeBelow50degC m148 : 28|9@1+ (30,0) [0|0] "" Vector__XXX
 SG_ DIR_a156_powerPolarity m156 : 28|2@1+ (1,0) [0|0] "" Vector__XXX
 SG_ DIR_a240_secondaryPattern m240 : 28|6@1+ (1,0) [0|0] "" Vector__XXX
 SG_ DIR_a250_reason m250 : 28|2@1+ (1,0) [0|0] "" Vector__XXX
 SG_ DIR_a001_localRegError_H m1 : 29|1@1+ (1,0) [0|0] "" Vector__XXX
 SG_ DIR_a002_localRegError_H m2 : 29|1@1+ (1,0) [0|0] "" Vector__XXX
 SG_ DIR_a003_localRegError_H m3 : 29|1@1+ (1,0) [0|0] "" Vector__XXX
 SG_ DIR_a010_ovfNmi m10 : 29|1@1+ (1,0) [0|0] "" Vector__XXX
 SG_ DIR_a136_crcError_AL m136 : 29|1@1+ (1,0) [0|0] "" Vector__XXX
 SG_ DIR_a144_oilPump2HwType m144 : 29|1@1+ (1,0) [0|0] "" Vector__XXX
 SG_ DIR_a229_reason m229 : 29|1@1+ (1,0) [0|0] "" Vector__XXX
 SG_ DIR_a001_spiError_H m1 : 30|1@1+ (1,0) [0|0] "" Vector__XXX
 SG_ DIR_a002_spiError_H m2 : 30|1@1+ (1,0) [0|0] "" Vector__XXX
 SG_ DIR_a003_spiError_H m3 : 30|1@1+ (1,0) [0|0] "" Vector__XXX
 SG_ DIR_a014_adState m14 : 30|2@1+ (1,0) [0|0] "" Vector__XXX
 SG_ DIR_a015_pyroSenseIrrational m15 : 30|1@1+ (1,0) [0|0] "" Vector__XXX
 SG_ DIR_a117_odometerStatus m117 : 30|1@1+ (1,0) [0|0] "" Vector__XXX
 SG_ DIR_a136_busyError_AL m136 : 30|1@1+ (1,0) [0|0] "" Vector__XXX
 SG_ DIR_a144_heatsinkType m144 : 30|1@1+ (1,0) [0|0] "" Vector__XXX
 SG_ DIR_a156_highCurrentMagnitude m156 : 30|1@1+ (1,0) [0|0] "" Vector__XXX
 SG_ DIR_a244_gateDriveICUndervoltage m244 : 30|1@1+ (1,0) [0|0] "" Vector__XXX
 SG_ DIR_a253_reason m253 : 30|2@1+ (1,0) [0|0] "" Vector__XXX
 SG_ DIR_a254_vBat m254 : 30|10@1+ (2,0) [0|0] "" Vector__XXX
 SG_ DIR_a001_deadtimeError_H m1 : 31|1@1+ (1,0) [0|0] "" Vector__XXX
 SG_ DIR_a002_deadtimeError_H m2 : 31|1@1+ (1,0) [0|0] "" Vector__XXX
 SG_ DIR_a003_deadtimeError_H m3 : 31|1@1+ (1,0) [0|0] "" Vector__XXX
 SG_ DIR_a024_Ia m24 : 31|7@1- (22.5,0) [0|0] "" Vector__XXX
 SG_ DIR_a136_spiError_AH m136 : 31|1@1+ (1,0) [0|0] "" Vector__XXX
 SG_ DIR_a144_softPerformanceLimit m144 : 31|1@1+ (1,0) [0|0] "" Vector__XXX
 SG_ DIR_a156_highMotorSpeed m156 : 31|1@1+ (1,0) [0|0] "" Vector__XXX
 SG_ DIR_a244_plausibleSingleSwitchShortOnly m244 : 31|1@1+ (1,0) [0|0] "" Vector__XXX
 SG_ DIR_a001_thermalWarning_L m1 : 32|1@1+ (1,0) [0|0] "" Vector__XXX
 SG_ DIR_a002_thermalWarning_L m2 : 32|1@1+ (1,0) [0|0] "" Vector__XXX
 SG_ DIR_a003_thermalWarning_L m3 : 32|1@1+ (1,0) [0|0] "" Vector__XXX
 SG_ DIR_a007_offsetError m7 : 32|14@1- (0.00038349519697141,0) [0|0] "" Vector__XXX
 SG_ DIR_a010_wdtFlags m10 : 32|16@1+ (1,0) [0|0] "" Vector__XXX
 SG_ DIR_a011_badGateDriveIC m11 : 32|3@1+ (1,0) [0|0] "" Vector__XXX
 SG_ DIR_a014_torqueCommandFwd m14 : 32|10@1- (2,0) [0|0] "" Vector__XXX
 SG_ DIR_a015_pyroSenseV m15 : 32|6@1+ (0.1,0) [0|0] "" Vector__XXX
 SG_ DIR_a025_torqueMotor m25 : 32|13@1- (0.25,0) [0|0] "" Vector__XXX
 SG_ DIR_a026_torqueMotor m26 : 32|13@1- (0.25,0) [0|0] "" Vector__XXX
 SG_ DIR_a027_torqueMotor m27 : 32|13@1- (0.25,0) [0|0] "" Vector__XXX
 SG_ DIR_a028_iArmsTorque m28 : 32|16@1+ (0.25,0) [0|0] "" Vector__XXX
 SG_ DIR_a029_iBrmsTorque m29 : 32|16@1+ (0.25,0) [0|0] "" Vector__XXX
 SG_ DIR_a030_iCrmsTorque m30 : 32|16@1+ (0.25,0) [0|0] "" Vector__XXX
 SG_ DIR_a033_deltaIa m33 : 32|16@1- (1,0) [0|0] "" Vector__XXX
 SG_ DIR_a034_deltaIb m34 : 32|16@1- (1,0) [0|0] "" Vector__XXX
 SG_ DIR_a035_phaseCurrent m35 : 32|16@1+ (1,0) [0|0] "" Vector__XXX
 SG_ DIR_a036_busHighLimit m36 : 32|16@1+ (0.1,0) [0|0] "" Vector__XXX
 SG_ DIR_a037_busLowLimit m37 : 32|16@1+ (0.1,0) [0|0] "" Vector__XXX
 SG_ DIR_a038_vBat m38 : 32|13@1+ (0.2,0) [0|0] "" Vector__XXX
 SG_ DIR_a046_statorTemp2 m46 : 32|16@1- (0.1,0) [0|0] "" Vector__XXX
 SG_ DIR_a047_statorTslope1 m47 : 32|16@1- (0.1,0) [0|0] "" Vector__XXX
 SG_ DIR_a048_statorTslope2 m48 : 32|16@1- (0.1,0) [0|0] "" Vector__XXX
 SG_ DIR_a049_motorRPM m49 : 32|16@1+ (1,0) [0|0] "" Vector__XXX
 SG_ DIR_a050_statorTemp2 m50 : 32|16@1- (0.1,0) [0|0] "" Vector__XXX
 SG_ DIR_a054_heatsinkTemp m54 : 32|16@1- (0.1,0) [0|0] "" Vector__XXX
 SG_ DIR_a055_parameterPM m55 : 32|13@1- (0.25,0) [0|0] "" Vector__XXX
 SG_ DIR_a065_errorType m65 : 32|1@1+ (1,0) [0|0] "" Vector__XXX
 SG_ DIR_a066_badValue2 m66 : 32|16@1+ (1,0) [0|0] "" Vector__XXX
 SG_ DIR_a067_mailboxID m67 : 32|16@1+ (1,0) [0|0] "" Vector__XXX
 SG_ DIR_a069_rotorCoolingPower m69 : 32|8@1+ (20,0) [0|0] "" Vector__XXX
 SG_ DIR_a071_busVslope m71 : 32|16@1+ (0.1,0) [0|0] "" Vector__XXX
 SG_ DIR_a074_motorSpeed1 m74 : 32|16@1- (1,0) [0|0] "" Vector__XXX
 SG_ DIR_a075_absSpeed m75 : 32|16@1+ (1,0) [0|0] "" Vector__XXX
 SG_ DIR_a093_canID m93 : 32|16@1+ (1,0) [0|0] "" Vector__XXX
 SG_ DIR_a094_badValue1 m94 : 32|16@1+ (1,0) [0|0] "" Vector__XXX
 SG_ DIR_a095_canID m95 : 32|16@1+ (1,0) [0|0] "" Vector__XXX
 SG_ DIR_a098_fluxState m98 : 32|4@1+ (1,0) [0|0] "" Vector__XXX
 SG_ DIR_a099_cpuUsage10Hz m99 : 32|8@1+ (1,0) [0|0] "" Vector__XXX
 SG_ DIR_a107_fpgaBootVersion m107 : 32|16@1+ (1,0) [0|0] "" Vector__XXX
 SG_ DIR_a108_blockingAlert m108 : 32|8@1+ (1,0) [0|0] "" Vector__XXX
 SG_ DIR_a111_phBcalib m111 : 32|16@1+ (1,0) [0|0] "" Vector__XXX
 SG_ DIR_a113_heatsink2Temp m113 : 32|16@1- (0.1,0) [0|0] "" Vector__XXX
 SG_ DIR_a121_badCurrent m121 : 32|16@1- (0.1,0) [0|0] "" Vector__XXX
 SG_ DIR_a123_lossRequest m123 : 32|7@1+ (0.1,0) [0|0] "" Vector__XXX
 SG_ DIR_a128_reportedFPGAversion m128 : 32|16@1+ (1,0) [0|0] "" Vector__XXX
 SG_ DIR_a133_badValue1 m133 : 32|16@1- (0.1,0) [0|0] "" Vector__XXX
 SG_ DIR_a136_crcError_AH m136 : 32|1@1+ (1,0) [0|0] "" Vector__XXX
 SG_ DIR_a142_lashCheckCount m142 : 32|15@1+ (1,0) [0|0] "" Vector__XXX
 SG_ DIR_a144_brakeActuationType m144 : 32|1@1+ (1,0) [0|0] "" Vector__XXX
 SG_ DIR_a149_temperature m149 : 32|8@1+ (1,-40) [0|0] "" Vector__XXX
 SG_ DIR_a150_vBatFilteredRate m150 : 32|8@1- (100,0) [0|0] "" Vector__XXX
 SG_ DIR_a151_torqueDriver m151 : 32|16@1- (0.25,0) [0|0] "" Vector__XXX
 SG_ DIR_a152_badValue m152 : 32|8@1+ (1,0) [0|0] "" Vector__XXX
 SG_ DIR_a153_phaseCurrent m153 : 32|8@1+ (0.1,0) [0|0] "" Vector__XXX
 SG_ DIR_a154_phaseError m154 : 32|8@1- (0.004,0) [0|0] "" Vector__XXX
 SG_ DIR_a156_ucrPlausible m156 : 32|1@1+ (1,0) [0|0] "" Vector__XXX
 SG_ DIR_a160_vBatFilteredRate m160 : 32|8@1- (100,0) [0|0] "" Vector__XXX
 SG_ DIR_a162_initialVehicleOdometer m162 : 32|10@1+ (400,0) [0|0] "" Vector__XXX
 SG_ DIR_a172_statorTemp2 m172 : 32|16@1- (0.1,0) [0|0] "" Vector__XXX
 SG_ DIR_a177_correctedValue m177 : 32|16@1+ (0.0001,0) [0|0] "" Vector__XXX
 SG_ DIR_a202_sysStateExitCondition m202 : 32|5@1+ (1,0) [0|0] "" Vector__XXX
 SG_ DIR_a233_serviceModeActive m233 : 32|1@1+ (1,0) [0|0] "" Vector__XXX
 SG_ DIR_a244_delay m244 : 32|16@1+ (1,0) [0|0] "" Vector__XXX
 SG_ DIR_a246_motorRPM m246 : 32|8@1- (150,0) [0|0] "" Vector__XXX
 SG_ DIR_a247_motorRPM m247 : 32|16@1- (1,0) [0|0] "" Vector__XXX
 SG_ DIR_a249_statorTempFromResist m249 : 32|8@1+ (1,-40) [0|0] "" Vector__XXX
 SG_ DIR_a251_dcVoltage m251 : 32|8@1+ (0.3,0) [0|0] "" Vector__XXX
 SG_ DIR_a001_thermalShutdown_L m1 : 33|1@1+ (1,0) [0|0] "" Vector__XXX
 SG_ DIR_a002_thermalShutdown_L m2 : 33|1@1+ (1,0) [0|0] "" Vector__XXX
 SG_ DIR_a003_thermalShutdown_L m3 : 33|1@1+ (1,0) [0|0] "" Vector__XXX
 SG_ DIR_a136_busyError_AH m136 : 33|1@1+ (1,0) [0|0] "" Vector__XXX
 SG_ DIR_a144_dasHw m144 : 33|1@1+ (1,0) [0|0] "" Vector__XXX
 SG_ DIR_a156_result m156 : 33|2@1+ (1,0) [0|0] "" Vector__XXX
 SG_ DIR_a001_undervoltVL_L m1 : 34|1@1+ (1,0) [0|0] "" Vector__XXX
 SG_ DIR_a002_undervoltVL_L m2 : 34|1@1+ (1,0) [0|0] "" Vector__XXX
 SG_ DIR_a003_undervoltVL_L m3 : 34|1@1+ (1,0) [0|0] "" Vector__XXX
 SG_ DIR_a144_powerLiftgateType m144 : 34|1@1+ (1,0) [0|0] "" Vector__XXX
 SG_ DIR_a147_accumulatedWear m147 : 34|10@1+ (0.005,0) [0|0] "" Vector__XXX
 SG_ DIR_a240_fuseA_I2t m240 : 34|6@1+ (8,0) [0|0] "" Vector__XXX
 SG_ DIR_a001_undervoltVH_L m1 : 35|1@1+ (1,0) [0|0] "" Vector__XXX
 SG_ DIR_a002_undervoltVH_L m2 : 35|1@1+ (1,0) [0|0] "" Vector__XXX
 SG_ DIR_a003_undervoltVH_L m3 : 35|1@1+ (1,0) [0|0] "" Vector__XXX
 SG_ DIR_a103_rmsCurrent m103 : 35|10@1- (12.819960861056751,0) [0|0] "" Vector__XXX
 SG_ DIR_a144_chassisSubType m144 : 35|1@1+ (1,0) [0|0] "" Vector__XXX
 SG_ DIR_a156_safeStateRecommend m156 : 35|2@1+ (1,0) [0|0] "" Vector__XXX
 SG_ DIR_a001_sense_L m1 : 36|1@1+ (1,0) [0|0] "" Vector__XXX
 SG_ DIR_a002_sense_L m2 : 36|1@1+ (1,0) [0|0] "" Vector__XXX
 SG_ DIR_a003_sense_L m3 : 36|1@1+ (1,0) [0|0] "" Vector__XXX
 SG_ DIR_a042_heatsinkTemp m42 : 36|10@1+ (0.25,-60) [0|0] "" Vector__XXX
 SG_ DIR_a045_heatsinkTemp m45 : 36|10@1+ (0.25,-60) [0|0] "" Vector__XXX
 SG_ DIR_a058_heatsinkTemp m58 : 36|10@1+ (0.25,-60) [0|0] "" Vector__XXX
 SG_ DIR_a144_autonomyFeatureType m144 : 36|1@1+ (1,0) [0|0] "" Vector__XXX
 SG_ DIR_a001_desat_L m1 : 37|1@1+ (1,0) [0|0] "" Vector__XXX
 SG_ DIR_a002_desat_L m2 : 37|1@1+ (1,0) [0|0] "" Vector__XXX
 SG_ DIR_a003_desat_L m3 : 37|1@1+ (1,0) [0|0] "" Vector__XXX
 SG_ DIR_a148_timeFrom50to90degC m148 : 37|9@1+ (30,0) [0|0] "" Vector__XXX
 SG_ DIR_a156_alertQueueOverrun m156 : 37|1@1+ (1,0) [0|0] "" Vector__XXX
 SG_ DIR_a001_overvoltVL_L m1 : 38|1@1+ (1,0) [0|0] "" Vector__XXX
 SG_ DIR_a002_overvoltVL_L m2 : 38|1@1+ (1,0) [0|0] "" Vector__XXX
 SG_ DIR_a003_overvoltVL_L m3 : 38|1@1+ (1,0) [0|0] "" Vector__XXX
 SG_ DIR_a024_Ib m24 : 38|7@1- (22.5,0) [0|0] "" Vector__XXX
 SG_ DIR_a156_motorRPM m156 : 38|16@1- (1,0) [0|0] "" Vector__XXX
 SG_ DIR_a001_overvoltVH_L m1 : 39|1@1+ (1,0) [0|0] "" Vector__XXX
 SG_ DIR_a002_overvoltVH_L m2 : 39|1@1+ (1,0) [0|0] "" Vector__XXX
 SG_ DIR_a003_overvoltVH_L m3 : 39|1@1+ (1,0) [0|0] "" Vector__XXX
 SG_ DIR_a123_badCurrent m123 : 39|9@1- (10,0) [0|0] "" Vector__XXX
 SG_ DIR_a001_undervoltVCC_L m1 : 40|1@1+ (1,0) [0|0] "" Vector__XXX
 SG_ DIR_a002_undervoltVCC_L m2 : 40|1@1+ (1,0) [0|0] "" Vector__XXX
 SG_ DIR_a003_undervoltVCC_L m3 : 40|1@1+ (1,0) [0|0] "" Vector__XXX
 SG_ DIR_a011_badDataRead m11 : 40|8@1+ (1,0) [0|0] "" Vector__XXX
 SG_ DIR_a015_pyroSenseVN m15 : 40|6@1+ (0.1,0) [0|0] "" Vector__XXX
 SG_ DIR_a016_torqueMotor m16 : 40|16@1- (1,0) [0|0] "" Vector__XXX
 SG_ DIR_a061_otherTemp m61 : 40|16@1- (0.1,0) [0|0] "" Vector__XXX
 SG_ DIR_a065_mailboxID m65 : 40|16@1+ (1,0) [0|0] "" Vector__XXX
 SG_ DIR_a069_rotorMagnetTemp m69 : 40|10@1+ (0.25,-60) [0|0] "" Vector__XXX
 SG_ DIR_a096_word2 m96 : 40|16@1+ (1,0) [0|0] "" Vector__XXX
 SG_ DIR_a097_argument m97 : 40|16@1+ (1,0) [0|0] "" Vector__XXX
 SG_ DIR_a099_cpuUsage100Hz m99 : 40|8@1+ (1,0) [0|0] "" Vector__XXX
 SG_ DIR_a122_stackSize m122 : 40|16@1+ (1,0) [0|0] "" Vector__XXX
 SG_ DIR_a134_wheelSpeedDiffReL m134 : 40|12@1- (0.0625,0) [0|0] "" Vector__XXX
 SG_ DIR_a149_state m149 : 40|3@1+ (1,0) [0|0] "" Vector__XXX
 SG_ DIR_a150_elapsedMs m150 : 40|8@1+ (1,0) [0|0] "" Vector__XXX
 SG_ DIR_a152_expectedValue m152 : 40|8@1+ (1,0) [0|0] "" Vector__XXX
 SG_ DIR_a153_dcVoltage m153 : 40|8@1+ (0.3,0) [0|0] "" Vector__XXX
 SG_ DIR_a154_commonGain m154 : 40|8@1+ (0.02,0) [0|0] "" Vector__XXX
 SG_ DIR_a160_elapsedMs m160 : 40|8@1+ (1,0) [0|0] "" Vector__XXX
 SG_ DIR_a240_fuseB_I2t m240 : 40|6@1+ (8,0) [0|0] "" Vector__XXX
 SG_ DIR_a246_eepromOffsetIa m246 : 40|6@1- (0.763,0) [0|0] "" Vector__XXX
 SG_ DIR_a249_statorT m249 : 40|8@1+ (1,-40) [0|0] "" Vector__XXX
 SG_ DIR_a251_dcCurrent m251 : 40|8@1+ (0.1,0) [0|0] "" Vector__XXX
 SG_ DIR_a254_reason m254 : 40|2@1+ (1,0) [0|0] "" Vector__XXX
 SG_ DIR_a001_asynchStop_L m1 : 41|1@1+ (1,0) [0|0] "" Vector__XXX
 SG_ DIR_a002_asynchStop_L m2 : 41|1@1+ (1,0) [0|0] "" Vector__XXX
 SG_ DIR_a003_asynchStop_L m3 : 41|1@1+ (1,0) [0|0] "" Vector__XXX
 SG_ DIR_a001_remoteRegError_L m1 : 42|1@1+ (1,0) [0|0] "" Vector__XXX
 SG_ DIR_a002_remoteRegError_L m2 : 42|1@1+ (1,0) [0|0] "" Vector__XXX
 SG_ DIR_a003_remoteRegError_L m3 : 42|1@1+ (1,0) [0|0] "" Vector__XXX
 SG_ DIR_a014_brakeMasterCylPress m14 : 42|10@1+ (0.25,-42.5) [0|0] "" Vector__XXX
 SG_ DIR_a162_currentOdometer m162 : 42|10@1+ (500,0) [0|0] "" Vector__XXX
 SG_ DIR_a001_undervoltVDD_L m1 : 43|1@1+ (1,0) [0|0] "" Vector__XXX
 SG_ DIR_a002_undervoltVDD_L m2 : 43|1@1+ (1,0) [0|0] "" Vector__XXX
 SG_ DIR_a003_undervoltVDD_L m3 : 43|1@1+ (1,0) [0|0] "" Vector__XXX
 SG_ DIR_a149_fluidTempSNA m149 : 43|1@1+ (1,0) [0|0] "" Vector__XXX
 SG_ DIR_a001_overvoltVDD_L m1 : 44|1@1+ (1,0) [0|0] "" Vector__XXX
 SG_ DIR_a002_overvoltVDD_L m2 : 44|1@1+ (1,0) [0|0] "" Vector__XXX
 SG_ DIR_a003_overvoltVDD_L m3 : 44|1@1+ (1,0) [0|0] "" Vector__XXX
 SG_ DIR_a147_wearIsValid m147 : 44|1@1+ (1,0) [0|0] "" Vector__XXX
 SG_ DIR_a149_insufficientFlow m149 : 44|1@1+ (1,0) [0|0] "" Vector__XXX
 SG_ DIR_a001_localRegError_L m1 : 45|1@1+ (1,0) [0|0] "" Vector__XXX
 SG_ DIR_a002_localRegError_L m2 : 45|1@1+ (1,0) [0|0] "" Vector__XXX
 SG_ DIR_a003_localRegError_L m3 : 45|1@1+ (1,0) [0|0] "" Vector__XXX
 SG_ DIR_a024_maxCurrMagSqrd m24 : 45|12@1+ (500,0) [0|0] "" Vector__XXX
 SG_ DIR_a055_torqueType m55 : 45|2@1+ (1,0) [0|0] "" Vector__XXX
 SG_ DIR_a103_ambientTemp m103 : 45|7@1- (1.5873015873015872,11.11111111111111) [0|0] "" Vector__XXX
 SG_ DIR_a149_motorOpenPhase m149 : 45|1@1+ (1,0) [0|0] "" Vector__XXX
 SG_ DIR_a001_spiError_L m1 : 46|1@1+ (1,0) [0|0] "" Vector__XXX
 SG_ DIR_a002_spiError_L m2 : 46|1@1+ (1,0) [0|0] "" Vector__XXX
 SG_ DIR_a003_spiError_L m3 : 46|1@1+ (1,0) [0|0] "" Vector__XXX
 SG_ DIR_a007_idFdbStdDeviation m7 : 46|8@1+ (4,0) [0|0] "" Vector__XXX
 SG_ DIR_a148_timeFrom90to104degC m148 : 46|9@1+ (30,0) [0|0] "" Vector__XXX
 SG_ DIR_a149_motorShorted m149 : 46|1@1+ (1,0) [0|0] "" Vector__XXX
 SG_ DIR_a240_primaryTimeout m240 : 46|1@1+ (1,0) [0|0] "" Vector__XXX
 SG_ DIR_a001_deadtimeError_L m1 : 47|1@1+ (1,0) [0|0] "" Vector__XXX
 SG_ DIR_a002_deadtimeError_L m2 : 47|1@1+ (1,0) [0|0] "" Vector__XXX
 SG_ DIR_a003_deadtimeError_L m3 : 47|1@1+ (1,0) [0|0] "" Vector__XXX
 SG_ DIR_a149_motorFlowSNA m149 : 47|1@1+ (1,0) [0|0] "" Vector__XXX
 SG_ DIR_a240_secondaryTimeout m240 : 47|1@1+ (1,0) [0|0] "" Vector__XXX
 SG_ DIR_a001_gateDriveErrCounter m1 : 48|4@1+ (1,0) [0|0] "" Vector__XXX
 SG_ DIR_a002_gateDriveErrCounter m2 : 48|4@1+ (1,0) [0|0] "" Vector__XXX
 SG_ DIR_a003_gateDriveErrCounter m3 : 48|4@1+ (1,0) [0|0] "" Vector__XXX
 SG_ DIR_a011_badDataExpected m11 : 48|8@1+ (1,0) [0|0] "" Vector__XXX
 SG_ DIR_a013_errorType m13 : 48|4@1+ (1,0) [0|0] "" Vector__XXX
 SG_ DIR_a015_pyroSenseVDiff m15 : 48|6@1+ (0.1,0) [0|0] "" Vector__XXX
 SG_ DIR_a025_motorSpeed m25 : 48|16@1- (1,0) [0|0] "" Vector__XXX
 SG_ DIR_a026_motorSpeed m26 : 48|16@1- (1,0) [0|0] "" Vector__XXX
 SG_ DIR_a027_motorSpeed m27 : 48|16@1- (1,0) [0|0] "" Vector__XXX
 SG_ DIR_a028_iArmsSpeed m28 : 48|16@1+ (1,0) [0|0] "" Vector__XXX
 SG_ DIR_a029_iBrmsSpeed m29 : 48|16@1+ (1,0) [0|0] "" Vector__XXX
 SG_ DIR_a030_iCrmsSpeed m30 : 48|16@1+ (1,0) [0|0] "" Vector__XXX
 SG_ DIR_a033_vRefIa m33 : 48|16@1- (0.001,0) [0|0] "" Vector__XXX
 SG_ DIR_a034_vRefIb m34 : 48|16@1- (0.001,0) [0|0] "" Vector__XXX
 SG_ DIR_a035_frequency m35 : 48|10@1+ (1,0) [0|0] "" Vector__XXX
 SG_ DIR_a038_iBat m38 : 48|13@1+ (0.5,0) [0|0] "" Vector__XXX
 SG_ DIR_a042_inletTempSlope m42 : 48|8@1- (0.5,0) [0|0] "" Vector__XXX
 SG_ DIR_a045_outletTempSlope m45 : 48|8@1- (0.5,0) [0|0] "" Vector__XXX
 SG_ DIR_a049_motorCurrent m49 : 48|11@1+ (1,0) [0|0] "" Vector__XXX
 SG_ DIR_a055_motorRPM m55 : 48|16@1- (1,0) [0|0] "" Vector__XXX
 SG_ DIR_a058_pcbTempSlope m58 : 48|8@1- (0.5,0) [0|0] "" Vector__XXX
 SG_ DIR_a066_canID m66 : 48|12@1+ (1,0) [0|0] "" Vector__XXX
 SG_ DIR_a074_motorSpeed2 m74 : 48|16@1- (1,0) [0|0] "" Vector__XXX
 SG_ DIR_a084_eccCheckFail m84 : 48|1@1+ (1,0) [0|0] "" Vector__XXX
 SG_ DIR_a093_errorType m93 : 48|1@1+ (1,0) [0|0] "" Vector__XXX
 SG_ DIR_a094_badValue2 m94 : 48|16@1+ (1,0) [0|0] "" Vector__XXX
 SG_ DIR_a099_cpuUsage1kHz m99 : 48|8@1+ (1,0) [0|0] "" Vector__XXX
 SG_ DIR_a107_fpgaMasterActive m107 : 48|1@1+ (1,0) [0|0] "" Vector__XXX
 SG_ DIR_a113_heatsink3Temp m113 : 48|16@1- (0.1,0) [0|0] "" Vector__XXX
 SG_ DIR_a121_badFlux m121 : 48|16@1+ (0.0001,0) [0|0] "" Vector__XXX
 SG_ DIR_a123_motorRPM m123 : 48|8@1- (150,0) [0|0] "" Vector__XXX
 SG_ DIR_a133_badValue2 m133 : 48|16@1- (0.1,0) [0|0] "" Vector__XXX
 SG_ DIR_a149_responseError m149 : 48|1@1+ (1,0) [0|0] "" Vector__XXX
 SG_ DIR_a150_energy m150 : 48|16@1+ (1,0) [0|0] "" Vector__XXX
 SG_ DIR_a153_lowPressPlausibility m153 : 48|5@1+ (3.3,0) [0|0] "" Vector__XXX
 SG_ DIR_a154_noCalibration m154 : 48|1@1+ (1,0) [0|0] "" Vector__XXX
 SG_ DIR_a160_energy m160 : 48|16@1+ (1,0) [0|0] "" Vector__XXX
 SG_ DIR_a240_primNoCurrentA m240 : 48|1@1+ (1,0) [0|0] "" Vector__XXX
 SG_ DIR_a246_eepromOffsetIb m246 : 48|6@1- (0.763,0) [0|0] "" Vector__XXX
 SG_ DIR_a247_torqueMotor m247 : 48|16@1- (1,0) [0|0] "" Vector__XXX
 SG_ DIR_a249_motorCurrent m249 : 48|11@1+ (1,0) [0|0] "" Vector__XXX
 SG_ DIR_a251_phaseCurrent m251 : 48|8@1+ (0.1,0) [0|0] "" Vector__XXX
 SG_ DIR_a084_preAddressTestFail m84 : 49|1@1+ (1,0) [0|0] "" Vector__XXX
 SG_ DIR_a107_fpgaFaultActive m107 : 49|1@1+ (1,0) [0|0] "" Vector__XXX
 SG_ DIR_a149_pcbaID m149 : 49|1@1+ (1,0) [0|0] "" Vector__XXX
 SG_ DIR_a154_noPhaseLock m154 : 49|1@1+ (1,0) [0|0] "" Vector__XXX
 SG_ DIR_a240_primNoCurrentB m240 : 49|1@1+ (1,0) [0|0] "" Vector__XXX
 SG_ DIR_a069_fittedTorqueLimit m69 : 50|13@1- (0.25,0) [0|0] "" Vector__XXX
 SG_ DIR_a084_postAddressTestFail m84 : 50|1@1+ (1,0) [0|0] "" Vector__XXX
 SG_ DIR_a107_fpgaWarningActive m107 : 50|1@1+ (1,0) [0|0] "" Vector__XXX
 SG_ DIR_a154_noCarrier m154 : 50|1@1+ (1,0) [0|0] "" Vector__XXX
 SG_ DIR_a240_secNoCurrentA m240 : 50|1@1+ (1,0) [0|0] "" Vector__XXX
 SG_ DIR_a084_flashEccTestFail m84 : 51|1@1+ (1,0) [0|0] "" Vector__XXX
 SG_ DIR_a154_notReady m154 : 51|1@1+ (1,0) [0|0] "" Vector__XXX
 SG_ DIR_a240_secNoCurrentB m240 : 51|1@1+ (1,0) [0|0] "" Vector__XXX
 SG_ DIR_a001_remoteCommError_H m1 : 52|1@1+ (1,0) [0|0] "" Vector__XXX
 SG_ DIR_a002_remoteCommError_H m2 : 52|1@1+ (1,0) [0|0] "" Vector__XXX
 SG_ DIR_a003_remoteCommError_H m3 : 52|1@1+ (1,0) [0|0] "" Vector__XXX
 SG_ DIR_a014_rmsTorqueError m14 : 52|10@1+ (1,0) [0|0] "" Vector__XXX
 SG_ DIR_a103_sensorTempEst m103 : 52|8@1- (1.2598425196850394,40.31496062992126) [0|0] "" Vector__XXX
 SG_ DIR_a134_wheelSpeedDiffReR m134 : 52|12@1- (0.0625,0) [0|0] "" Vector__XXX
 SG_ DIR_a154_errorTableInvalid m154 : 52|1@1+ (1,0) [0|0] "" Vector__XXX
 SG_ DIR_a240_primaryDutyCycle m240 : 52|5@1+ (1,0) [0|0] "" Vector__XXX
 SG_ DIR_a001_localCommError_H m1 : 53|1@1+ (1,0) [0|0] "" Vector__XXX
 SG_ DIR_a002_localCommError_H m2 : 53|1@1+ (1,0) [0|0] "" Vector__XXX
 SG_ DIR_a003_localCommError_H m3 : 53|1@1+ (1,0) [0|0] "" Vector__XXX
 SG_ DIR_a153_state m153 : 53|3@1+ (1,0) [0|0] "" Vector__XXX
 SG_ DIR_a154_carrierOffset m154 : 53|1@1+ (1,0) [0|0] "" Vector__XXX
 SG_ DIR_a001_remoteReset_H m1 : 54|1@1+ (1,0) [0|0] "" Vector__XXX
 SG_ DIR_a002_remoteReset_H m2 : 54|1@1+ (1,0) [0|0] "" Vector__XXX
 SG_ DIR_a003_remoteReset_H m3 : 54|1@1+ (1,0) [0|0] "" Vector__XXX
 SG_ DIR_a007_iqFdbStdDeviation m7 : 54|8@1+ (4,0) [0|0] "" Vector__XXX
 SG_ DIR_a154_trackerIrrational m154 : 54|1@1+ (1,0) [0|0] "" Vector__XXX
 SG_ DIR_a156_phaseAPolarityAlternate m156 : 54|2@1+ (1,0) [0|0] "" Vector__XXX
 SG_ DIR_a001_localReset_H m1 : 55|1@1+ (1,0) [0|0] "" Vector__XXX
 SG_ DIR_a002_localReset_H m2 : 55|1@1+ (1,0) [0|0] "" Vector__XXX
 SG_ DIR_a003_localReset_H m3 : 55|1@1+ (1,0) [0|0] "" Vector__XXX
 SG_ DIR_a148_timeAbove104degC m148 : 55|9@1+ (5,0) [0|0] "" Vector__XXX
 SG_ DIR_a154_claMIA m154 : 55|1@1+ (1,0) [0|0] "" Vector__XXX
 SG_ DIR_a001_remoteCommError_L m1 : 56|1@1+ (1,0) [0|0] "" Vector__XXX
 SG_ DIR_a002_remoteCommError_L m2 : 56|1@1+ (1,0) [0|0] "" Vector__XXX
 SG_ DIR_a003_remoteCommError_L m3 : 56|1@1+ (1,0) [0|0] "" Vector__XXX
 SG_ DIR_a011_codeBranch m11 : 56|4@1+ (1,0) [0|0] "" Vector__XXX
 SG_ DIR_a015_pyroSenseVAvg m15 : 56|6@1+ (0.1,0) [0|0] "" Vector__XXX
 SG_ DIR_a016_safetyICfaultLine m16 : 56|1@1+ (1,0) [0|0] "" Vector__XXX
 SG_ DIR_a099_cpuUsage10ms m99 : 56|8@1+ (1,0) [0|0] "" Vector__XXX
 SG_ DIR_a123_varianceD m123 : 56|4@1+ (20,0) [0|0] "" Vector__XXX
 SG_ DIR_a153_oilPumpAlert m153 : 56|5@1+ (1,0) [0|0] "" Vector__XXX
 SG_ DIR_a156_phaseBPolarityAlternate m156 : 56|2@1+ (1,0) [0|0] "" Vector__XXX
 SG_ DIR_a251_leadAngle m251 : 56|4@1+ (1.875,0) [0|0] "" Vector__XXX
 SG_ DIR_a001_localCommError_L m1 : 57|1@1+ (1,0) [0|0] "" Vector__XXX
 SG_ DIR_a002_localCommError_L m2 : 57|1@1+ (1,0) [0|0] "" Vector__XXX
 SG_ DIR_a003_localCommError_L m3 : 57|1@1+ (1,0) [0|0] "" Vector__XXX
 SG_ DIR_a016_triggerEvent m16 : 57|5@1+ (1,0) [0|0] "" Vector__XXX
 SG_ DIR_a024_rotorAngle m24 : 57|7@1- (3,0) [0|0] "" Vector__XXX
 SG_ DIR_a240_secondaryDutyCycle m240 : 57|5@1+ (1,0) [0|0] "" Vector__XXX
 SG_ DIR_a001_remoteReset_L m1 : 58|1@1+ (1,0) [0|0] "" Vector__XXX
 SG_ DIR_a002_remoteReset_L m2 : 58|1@1+ (1,0) [0|0] "" Vector__XXX
 SG_ DIR_a003_remoteReset_L m3 : 58|1@1+ (1,0) [0|0] "" Vector__XXX
 SG_ DIR_a156_phaseCPolarityAlternate m156 : 58|2@1+ (1,0) [0|0] "" Vector__XXX
 SG_ DIR_a001_localReset_L m1 : 59|1@1+ (1,0) [0|0] "" Vector__XXX
 SG_ DIR_a002_localReset_L m2 : 59|1@1+ (1,0) [0|0] "" Vector__XXX
 SG_ DIR_a003_localReset_L m3 : 59|1@1+ (1,0) [0|0] "" Vector__XXX
 SG_ DIR_a001_faultLine1Gpio_H m1 : 60|1@1+ (1,0) [0|0] "" Vector__XXX
 SG_ DIR_a002_faultLine1Gpio_H m2 : 60|1@1+ (1,0) [0|0] "" Vector__XXX
 SG_ DIR_a003_faultLine1Gpio_H m3 : 60|1@1+ (1,0) [0|0] "" Vector__XXX
 SG_ DIR_a066_errorType m66 : 60|3@1+ (1,0) [0|0] "" Vector__XXX
 SG_ DIR_a123_varianceQ m123 : 60|4@1+ (20,0) [0|0] "" Vector__XXX
 SG_ DIR_a156_powerPolarityAlternate m156 : 60|2@1+ (1,0) [0|0] "" Vector__XXX
 SG_ DIR_a251_reason m251 : 60|3@1+ (1,0) [0|0] "" Vector__XXX
 SG_ DIR_a001_faultLine1Gpio_L m1 : 61|1@1+ (1,0) [0|0] "" Vector__XXX
 SG_ DIR_a002_faultLine1Gpio_L m2 : 61|1@1+ (1,0) [0|0] "" Vector__XXX
 SG_ DIR_a003_faultLine1Gpio_L m3 : 61|1@1+ (1,0) [0|0] "" Vector__XXX
 SG_ DIR_a038_reason m38 : 61|2@1+ (1,0) [0|0] "" Vector__XXX
 SG_ DIR_a153_reason m153 : 61|3@1+ (1,0) [0|0] "" Vector__XXX
 SG_ DIR_a007_motorShift m7 : 62|1@1+ (1,0) [0|0] "" Vector__XXX
 SG_ DIR_a014_tcEnabled m14 : 62|1@1+ (1,0) [0|0] "" Vector__XXX
 SG_ DIR_a015_selfTestAborted m15 : 62|1@1+ (1,0) [0|0] "" Vector__XXX
 SG_ DIR_a156_incrementedGateDriveErrorCounter m156 : 62|1@1+ (1,0) [0|0] "" Vector__XXX
 SG_ DIR_a240_confNoCurrentDetected m240 : 62|1@1+ (1,0) [0|0] "" Vector__XXX
 SG_ DIR_a007_motorShort m7 : 63|1@1+ (1,0) [0|0] "" Vector__XXX
 SG_ DIR_a014_fbDeratedForRmsError m14 : 63|1@1+ (1,0) [0|0] "" Vector__XXX
 SG_ DIR_a240_secondaryStrategy3ps m240 : 63|1@1+ (1,0) [0|0] "" Vector__XXX

BO_ 1446 PMR_alertLog: 8 Vector__XXX
 SG_ PMR_alertID M : 0|7@1+ (1,0) [0|0] "" Vector__XXX
 SG_ PMR_alertState : 15|1@1+ (1,0) [0|0] "" Vector__XXX
 SG_ PMR_a000_alertDataW0 m0 : 16|16@1+ (1,0) [0|0] "" Vector__XXX
 SG_ PMR_a001_w0 m1 : 16|16@1+ (1,0) [0|0] "" Vector__XXX
 SG_ PMR_a002_torqueAverage m2 : 16|1@1+ (1,0) [0|0] "" Vector__XXX
 SG_ PMR_a003_reverseGear m3 : 16|1@1+ (1,0) [0|0] "" Vector__XXX
 SG_ PMR_a004_torqueAverage m4 : 16|1@1+ (1,0) [0|0] "" Vector__XXX
 SG_ PMR_a005_torqueReason m5 : 16|2@1+ (1,0) [0|0] "" Vector__XXX
 SG_ PMR_a008_memoryErrorTypeBits m8 : 16|16@1+ (1,0) [0|0] "" Vector__XXX
 SG_ PMR_a010_messageId m10 : 16|16@1+ (1,0) [0|0] "" Vector__XXX
 SG_ PMR_a011_Ia m11 : 16|9@1- (12.0192,0) [0|0] "" Vector__XXX
 SG_ PMR_a012_canID m12 : 16|12@1+ (1,0) [0|0] "" Vector__XXX
 SG_ PMR_a013_mailboxID m13 : 16|16@1+ (1,0) [0|0] "" Vector__XXX
 SG_ PMR_a017_EPBL_status m17 : 16|1@1+ (1,0) [0|0] "" Vector__XXX
 SG_ PMR_a018_w0 m18 : 16|16@1+ (1,0) [0|0] "" Vector__XXX
 SG_ PMR_a019_statorTemp1 m19 : 16|16@1- (0.1,0) [0|0] "" Vector__XXX
 SG_ PMR_a025_sccReset m25 : 16|1@1+ (1,0) [0|0] "" Vector__XXX
 SG_ PMR_a026_reason m26 : 16|1@1+ (1,0) [0|0] "" Vector__XXX
 SG_ PMR_a027_w0 m27 : 16|16@1+ (1,0) [0|0] "" Vector__XXX
 SG_ PMR_a028_torqueCommanded m28 : 16|13@1- (2,0) [0|0] "" Vector__XXX
 SG_ PMR_a031_taskID m31 : 16|4@1+ (1,0) [0|0] "" Vector__XXX
 SG_ PMR_a032_w0 m32 : 16|16@1+ (1,0) [0|0] "" Vector__XXX
 SG_ PMR_a033_state m33 : 16|4@1+ (1,0) [0|0] "" Vector__XXX
 SG_ PMR_a034_parameterDI m34 : 16|13@1- (0.25,0) [0|0] "" Vector__XXX
 SG_ PMR_a035_serviceDataId m35 : 16|16@1+ (1,0) [0|0] "" Vector__XXX
 SG_ PMR_a036_timeSinceTxHWI m36 : 16|6@1+ (64,0) [0|0] "" Vector__XXX
 SG_ PMR_a037_hvpFaults m37 : 16|1@1+ (1,0) [0|0] "" Vector__XXX
 SG_ PMR_a039_DIS_status m39 : 16|1@1+ (1,0) [0|0] "" Vector__XXX
 SG_ PMR_a040_PM_state m40 : 16|1@1+ (1,0) [0|0] "" Vector__XXX
 SG_ PMR_a042_GTW_carConfig m42 : 16|1@1+ (1,0) [0|0] "" Vector__XXX
 SG_ PMR_a053_LVPowerState m53 : 16|1@1+ (1,0) [0|0] "" Vector__XXX
 SG_ PMR_a054_uiPowertrainControl m54 : 16|1@1+ (1,0) [0|0] "" Vector__XXX
 SG_ PMR_a055_motorRPM m55 : 16|16@1- (1,0) [0|0] "" Vector__XXX
 SG_ PMR_a056_mailboxID m56 : 16|16@1+ (1,0) [0|0] "" Vector__XXX
 SG_ PMR_a057_canID m57 : 16|12@1+ (1,0) [0|0] "" Vector__XXX
 SG_ PMR_a061_diIpcVersion m61 : 16|8@1+ (1,0) [0|0] "" Vector__XXX
 SG_ PMR_a062_address m62 : 16|32@1+ (1,0) [0|0] "" Vector__XXX
 SG_ PMR_a064_interventionType m64 : 16|4@1+ (1,0) [0|0] "" Vector__XXX
 SG_ PMR_a092_pllClockSource m92 : 16|2@1+ (1,0) [0|0] "" Vector__XXX
 SG_ PMR_a094_cfgErrFlag m94 : 16|1@1+ (1,0) [0|0] "" Vector__XXX
 SG_ PMR_a095_wwdErrIntFlag m95 : 16|1@1+ (1,0) [0|0] "" Vector__XXX
 SG_ PMR_a096_wwdNumKicks m96 : 16|6@1+ (1,0) [0|0] "" Vector__XXX
 SG_ PMR_a002_torqueWindow m2 : 17|1@1+ (1,0) [0|0] "" Vector__XXX
 SG_ PMR_a004_torqueWindow m4 : 17|1@1+ (1,0) [0|0] "" Vector__XXX
 SG_ PMR_a017_EPBR_status m17 : 17|1@1+ (1,0) [0|0] "" Vector__XXX
 SG_ PMR_a025_hibernate m25 : 17|1@1+ (1,0) [0|0] "" Vector__XXX
 SG_ PMR_a026_isrCount20kHz m26 : 17|5@1+ (1,0) [0|0] "" Vector__XXX
 SG_ PMR_a039_DIS_torque m39 : 17|1@1+ (1,0) [0|0] "" Vector__XXX
 SG_ PMR_a042_GTW_time m42 : 17|1@1+ (1,0) [0|0] "" Vector__XXX
 SG_ PMR_a053_coolant m53 : 17|1@1+ (1,0) [0|0] "" Vector__XXX
 SG_ PMR_a054_uiChassisControl m54 : 17|1@1+ (1,0) [0|0] "" Vector__XXX
 SG_ PMR_a094_trFailFlag m94 : 17|1@1+ (1,0) [0|0] "" Vector__XXX
 SG_ PMR_a095_fwdErrIntFlag m95 : 17|1@1+ (1,0) [0|0] "" Vector__XXX
 SG_ PMR_a002_torqueMeasured m2 : 18|13@1- (2,0) [0|0] "" Vector__XXX
 SG_ PMR_a004_torqueMeasured m4 : 18|13@1- (2,0) [0|0] "" Vector__XXX
 SG_ PMR_a005_torqueMeasured m5 : 18|13@1- (2,0) [0|0] "" Vector__XXX
 SG_ PMR_a017_EPBL_autonomyHealth m17 : 18|1@1+ (1,0) [0|0] "" Vector__XXX
 SG_ PMR_a025_hwBist m25 : 18|1@1+ (1,0) [0|0] "" Vector__XXX
 SG_ PMR_a042_GTW_drivetrainType m42 : 18|2@1+ (1,0) [0|0] "" Vector__XXX
 SG_ PMR_a053_vcleftSwitchStatus m53 : 18|1@1+ (1,0) [0|0] "" Vector__XXX
 SG_ PMR_a054_uiCruiseControl m54 : 18|1@1+ (1,0) [0|0] "" Vector__XXX
 SG_ PMR_a094_noOpFlag m94 : 18|1@1+ (1,0) [0|0] "" Vector__XXX
 SG_ PMR_a095_errMissStsFlag m95 : 18|1@1+ (1,0) [0|0] "" Vector__XXX
 SG_ PMR_a017_EPBR_autonomyHealth m17 : 19|1@1+ (1,0) [0|0] "" Vector__XXX
 SG_ PMR_a025_nmiWatchdog m25 : 19|1@1+ (1,0) [0|0] "" Vector__XXX
 SG_ PMR_a053_restraintStatus m53 : 19|1@1+ (1,0) [0|0] "" Vector__XXX
 SG_ PMR_a054_uiTrackModeSettings m54 : 19|1@1+ (1,0) [0|0] "" Vector__XXX
 SG_ PMR_a094_parityErr m94 : 19|1@1+ (1,0) [0|0] "" Vector__XXX
 SG_ PMR_a095_preRegulatorOT m95 : 19|1@1+ (1,0) [0|0] "" Vector__XXX
 SG_ PMR_a025_watchdog m25 : 20|1@1+ (1,0) [0|0] "" Vector__XXX
 SG_ PMR_a031_stackUsed m31 : 20|14@1+ (1,0) [0|0] "" Vector__XXX
 SG_ PMR_a033_failReason m33 : 20|3@1+ (1,0) [0|0] "" Vector__XXX
 SG_ PMR_a042_expectedPerformanceCfg m42 : 20|2@1+ (1,0) [0|0] "" Vector__XXX
 SG_ PMR_a053_sensors m53 : 20|1@1+ (1,0) [0|0] "" Vector__XXX
 SG_ PMR_a054_uiTPMSRCPSetting m54 : 20|1@1+ (1,0) [0|0] "" Vector__XXX
 SG_ PMR_a064_torqueCmdState m64 : 20|4@1+ (1,0) [0|0] "" Vector__XXX
 SG_ PMR_a094_lengthErr m94 : 20|1@1+ (1,0) [0|0] "" Vector__XXX
 SG_ PMR_a095_ucLdoOT m95 : 20|1@1+ (1,0) [0|0] "" Vector__XXX
 SG_ PMR_a025_clockFailNmi m25 : 21|1@1+ (1,0) [0|0] "" Vector__XXX
 SG_ PMR_a094_addrErr m94 : 21|1@1+ (1,0) [0|0] "" Vector__XXX
 SG_ PMR_a095_monitoringOT m95 : 21|1@1+ (1,0) [0|0] "" Vector__XXX
 SG_ PMR_a025_ramUncErrorNmi m25 : 22|1@1+ (1,0) [0|0] "" Vector__XXX
 SG_ PMR_a026_isrCount1kHz m26 : 22|4@1+ (1,0) [0|0] "" Vector__XXX
 SG_ PMR_a036_timeSinceRxHWI m36 : 22|6@1+ (64,0) [0|0] "" Vector__XXX
 SG_ PMR_a042_gearControl m42 : 22|1@1+ (1,0) [0|0] "" Vector__XXX
 SG_ PMR_a094_durationErr m94 : 22|1@1+ (1,0) [0|0] "" Vector__XXX
 SG_ PMR_a095_preRegulatorVoltShort m95 : 22|1@1+ (1,0) [0|0] "" Vector__XXX
 SG_ PMR_a025_flashUncErrorNmi m25 : 23|1@1+ (1,0) [0|0] "" Vector__XXX
 SG_ PMR_a094_lockUnlockErr m94 : 23|1@1+ (1,0) [0|0] "" Vector__XXX
 SG_ PMR_a095_ucLdoShort m95 : 23|1@1+ (1,0) [0|0] "" Vector__XXX
 SG_ PMR_a003_pedalPos m3 : 24|8@1+ (0.4,0) [0|0] "" Vector__XXX
 SG_ PMR_a025_cpu1signMismatchNmi m25 : 24|1@1+ (1,0) [0|0] "" Vector__XXX
 SG_ PMR_a033_DSADC_Ia m33 : 24|16@1- (0.0939,0) [0|0] "" Vector__XXX
 SG_ PMR_a039_messageId m39 : 24|16@1+ (1,0) [0|0] "" Vector__XXX
 SG_ PMR_a040_messageId m40 : 24|16@1+ (1,0) [0|0] "" Vector__XXX
 SG_ PMR_a061_pmIpcVersion m61 : 24|8@1+ (1,0) [0|0] "" Vector__XXX
 SG_ PMR_a064_shortDetectedByDI m64 : 24|1@1+ (1,0) [0|0] "" Vector__XXX
 SG_ PMR_a094_preRegulatorOTWrn m94 : 24|1@1+ (1,0) [0|0] "" Vector__XXX
 SG_ PMR_a095_standbyLdoShort m95 : 24|1@1+ (1,0) [0|0] "" Vector__XXX
 SG_ PMR_a096_wwdErrCounterMax m96 : 24|6@1+ (1,0) [0|0] "" Vector__XXX
 SG_ PMR_a011_IaDelta m11 : 25|8@1- (24.0384,0) [0|0] "" Vector__XXX
 SG_ PMR_a025_cpu2signMismatchNmi m25 : 25|1@1+ (1,0) [0|0] "" Vector__XXX
 SG_ PMR_a064_UI_stoppingMode m64 : 25|2@1+ (1,0) [0|0] "" Vector__XXX
 SG_ PMR_a094_ucLdoOTWrn m94 : 25|1@1+ (1,0) [0|0] "" Vector__XXX
 SG_ PMR_a095_coreVoltShort m95 : 25|1@1+ (1,0) [0|0] "" Vector__XXX
 SG_ PMR_a025_pieVectErrorNmi m25 : 26|1@1+ (1,0) [0|0] "" Vector__XXX
 SG_ PMR_a026_switchingActive m26 : 26|1@1+ (1,0) [0|0] "" Vector__XXX
 SG_ PMR_a094_standbyLdoOverLoad m94 : 26|1@1+ (1,0) [0|0] "" Vector__XXX
 SG_ PMR_a095_preRegulatorOV m95 : 26|1@1+ (1,0) [0|0] "" Vector__XXX
 SG_ PMR_a025_sysDbgNmi m25 : 27|1@1+ (1,0) [0|0] "" Vector__XXX
 SG_ PMR_a026_systemStackOvf m26 : 27|1@1+ (1,0) [0|0] "" Vector__XXX
 SG_ PMR_a064_diCrsState m64 : 27|3@1+ (1,0) [0|0] "" Vector__XXX
 SG_ PMR_a094_commLdoOTWrn m94 : 27|1@1+ (1,0) [0|0] "" Vector__XXX
 SG_ PMR_a095_ucLdoOV m95 : 27|1@1+ (1,0) [0|0] "" Vector__XXX
 SG_ PMR_a012_errorType m12 : 28|3@1+ (1,0) [0|0] "" Vector__XXX
 SG_ PMR_a025_rlNmi m25 : 28|1@1+ (1,0) [0|0] "" Vector__XXX
 SG_ PMR_a026_controlStackOvf m26 : 28|1@1+ (1,0) [0|0] "" Vector__XXX
 SG_ PMR_a036_timeSince100HzTxSWI m36 : 28|6@1+ (0.32,0) [0|0] "" Vector__XXX
 SG_ PMR_a057_errorType m57 : 28|3@1+ (1,0) [0|0] "" Vector__XXX
 SG_ PMR_a094_refVoltOverLoad m94 : 28|1@1+ (1,0) [0|0] "" Vector__XXX
 SG_ PMR_a095_standbyLdoOV m95 : 28|1@1+ (1,0) [0|0] "" Vector__XXX
 SG_ PMR_a025_ovfNmi m25 : 29|1@1+ (1,0) [0|0] "" Vector__XXX
 SG_ PMR_a026_idleStackOvf m26 : 29|1@1+ (1,0) [0|0] "" Vector__XXX
 SG_ PMR_a094_commLdoShort m94 : 29|1@1+ (1,0) [0|0] "" Vector__XXX
 SG_ PMR_a095_coreOV m95 : 29|1@1+ (1,0) [0|0] "" Vector__XXX
 SG_ PMR_a025_possibleSafetyICReset m25 : 30|1@1+ (1,0) [0|0] "" Vector__XXX
 SG_ PMR_a026_eepStackOvf m26 : 30|1@1+ (1,0) [0|0] "" Vector__XXX
 SG_ PMR_a094_voltRefShort m94 : 30|1@1+ (1,0) [0|0] "" Vector__XXX
 SG_ PMR_a095_voltRefOV m95 : 30|1@1+ (1,0) [0|0] "" Vector__XXX
 SG_ PMR_a026_immStackOvf m26 : 31|1@1+ (1,0) [0|0] "" Vector__XXX
 SG_ PMR_a094_tracker1Short m94 : 31|1@1+ (1,0) [0|0] "" Vector__XXX
 SG_ PMR_a095_ucLdoUV m95 : 31|1@1+ (1,0) [0|0] "" Vector__XXX
 SG_ PMR_a000_alertDataW1 m0 : 32|16@1+ (1,0) [0|0] "" Vector__XXX
 SG_ PMR_a001_w1 m1 : 32|16@1+ (1,0) [0|0] "" Vector__XXX
 SG_ PMR_a002_torqueAccelAverage m2 : 32|13@1- (2,0) [0|0] "" Vector__XXX
 SG_ PMR_a003_zeroPointPedal m3 : 32|8@1+ (0.4,0) [0|0] "" Vector__XXX
 SG_ PMR_a004_torqueDecelAverage m4 : 32|13@1- (2,0) [0|0] "" Vector__XXX
 SG_ PMR_a005_iDQmagnitude m5 : 32|16@1- (0.0939,0) [0|0] "" Vector__XXX
 SG_ PMR_a008_crc_lsw m8 : 32|16@1+ (1,0) [0|0] "" Vector__XXX
 SG_ PMR_a010_DI_status m10 : 32|1@1+ (1,0) [0|0] "" Vector__XXX
 SG_ PMR_a012_badValue1 m12 : 32|16@1+ (1,0) [0|0] "" Vector__XXX
 SG_ PMR_a013_canID m13 : 32|16@1+ (1,0) [0|0] "" Vector__XXX
 SG_ PMR_a018_w1 m18 : 32|16@1+ (1,0) [0|0] "" Vector__XXX
 SG_ PMR_a019_statorTslope1 m19 : 32|16@1- (0.1,0) [0|0] "" Vector__XXX
 SG_ PMR_a026_xdcErrorIdMSW m26 : 32|10@1+ (1,0) [0|0] "" Vector__XXX
 SG_ PMR_a027_w1 m27 : 32|16@1+ (1,0) [0|0] "" Vector__XXX
 SG_ PMR_a028_torqueCommandFwd m28 : 32|13@1- (2,0) [0|0] "" Vector__XXX
 SG_ PMR_a032_w1 m32 : 32|16@1+ (1,0) [0|0] "" Vector__XXX
 SG_ PMR_a034_parameterPM m34 : 32|13@1- (0.25,0) [0|0] "" Vector__XXX
 SG_ PMR_a055_phaseAngle m55 : 32|8@1+ (0.00308,0) [0|0] "" Vector__XXX
 SG_ PMR_a056_canID m56 : 32|16@1+ (1,0) [0|0] "" Vector__XXX
 SG_ PMR_a057_badValue1 m57 : 32|16@1+ (1,0) [0|0] "" Vector__XXX
 SG_ PMR_a064_pmCrsState m64 : 32|3@1+ (1,0) [0|0] "" Vector__XXX
 SG_ PMR_a094_tracker2Short m94 : 32|1@1+ (1,0) [0|0] "" Vector__XXX
 SG_ PMR_a095_standbyLdoUV m95 : 32|1@1+ (1,0) [0|0] "" Vector__XXX
 SG_ PMR_a096_fwdNumKicks m96 : 32|6@1+ (1,0) [0|0] "" Vector__XXX
 SG_ PMR_a010_DI_torque m10 : 33|1@1+ (1,0) [0|0] "" Vector__XXX
 SG_ PMR_a011_Ib m11 : 33|9@1- (12.0192,0) [0|0] "" Vector__XXX
 SG_ PMR_a094_commLdoOV m94 : 33|1@1+ (1,0) [0|0] "" Vector__XXX
 SG_ PMR_a095_coreUV m95 : 33|1@1+ (1,0) [0|0] "" Vector__XXX
 SG_ PMR_a010_DI_slaveCommand m10 : 34|1@1+ (1,0) [0|0] "" Vector__XXX
 SG_ PMR_a031_stackUsedPrev m31 : 34|14@1+ (1,0) [0|0] "" Vector__XXX
 SG_ PMR_a036_timeSince1kHzCLK m36 : 34|6@1+ (32,0) [0|0] "" Vector__XXX
 SG_ PMR_a094_tracker1OV m94 : 34|1@1+ (1,0) [0|0] "" Vector__XXX
 SG_ PMR_a095_supplyVoltOV m95 : 34|1@1+ (1,0) [0|0] "" Vector__XXX
 SG_ PMR_a010_DI_locStatus m10 : 35|1@1+ (1,0) [0|0] "" Vector__XXX
 SG_ PMR_a094_tracker2OV m94 : 35|1@1+ (1,0) [0|0] "" Vector__XXX
 SG_ PMR_a095_bandgapComparatorUV m95 : 35|1@1+ (1,0) [0|0] "" Vector__XXX
 SG_ PMR_a010_DI_speed m10 : 36|1@1+ (1,0) [0|0] "" Vector__XXX
 SG_ PMR_a094_commLdoOT m94 : 36|1@1+ (1,0) [0|0] "" Vector__XXX
 SG_ PMR_a095_bandgapComparatorOV m95 : 36|1@1+ (1,0) [0|0] "" Vector__XXX
 SG_ PMR_a010_DI_systemStatus m10 : 37|1@1+ (1,0) [0|0] "" Vector__XXX
 SG_ PMR_a094_preRegulatorUV m94 : 37|1@1+ (1,0) [0|0] "" Vector__XXX
 SG_ PMR_a095_biasCurrentTooLow m95 : 37|1@1+ (1,0) [0|0] "" Vector__XXX
 SG_ PMR_a010_DI_chassisControl m10 : 38|1@1+ (1,0) [0|0] "" Vector__XXX
 SG_ PMR_a094_commLdoUV m94 : 38|1@1+ (1,0) [0|0] "" Vector__XXX
 SG_ PMR_a095_biasCurrentTooHigh m95 : 38|1@1+ (1,0) [0|0] "" Vector__XXX
 SG_ PMR_a010_DI_chassisControl2 m10 : 39|1@1+ (1,0) [0|0] "" Vector__XXX
 SG_ PMR_a094_voltRefUV m94 : 39|1@1+ (1,0) [0|0] "" Vector__XXX
 SG_ PMR_a010_vdcLeft m10 : 40|1@1+ (1,0) [0|0] "" Vector__XXX
 SG_ PMR_a033_DSADC_Ib m33 : 40|16@1- (0.0939,0) [0|0] "" Vector__XXX
 SG_ PMR_a036_timeSince1kHzSWI m36 : 40|6@1+ (32,0) [0|0] "" Vector__XXX
 SG_ PMR_a040_PM_locState m40 : 40|1@1+ (1,0) [0|0] "" Vector__XXX
 SG_ PMR_a055_commonGain m55 : 40|8@1+ (0.02,0) [0|0] "" Vector__XXX
 SG_ PMR_a094_tracker1UV m94 : 40|1@1+ (1,0) [0|0] "" Vector__XXX
 SG_ PMR_a095_safetyICstate m95 : 40|3@1+ (1,0) [0|0] "" Vector__XXX
 SG_ PMR_a096_fwdErrCounterMax m96 : 40|6@1+ (1,0) [0|0] "" Vector__XXX
 SG_ PMR_a010_vdcRight m10 : 41|1@1+ (1,0) [0|0] "" Vector__XXX
 SG_ PMR_a094_tracker2UV m94 : 41|1@1+ (1,0) [0|0] "" Vector__XXX
 SG_ PMR_a010_DI_vehicleEstimates m10 : 42|1@1+ (1,0) [0|0] "" Vector__XXX
 SG_ PMR_a011_IbDelta m11 : 42|8@1- (24.0384,0) [0|0] "" Vector__XXX
 SG_ PMR_a026_xdcErrorArg1 m26 : 42|22@1- (1,0) [0|0] "" Vector__XXX
 SG_ PMR_a094_spiOverrun m94 : 42|1@1+ (1,0) [0|0] "" Vector__XXX
 SG_ PMR_a010_DI_brakeCommand m10 : 43|1@1+ (1,0) [0|0] "" Vector__XXX
 SG_ PMR_a094_spiParityErr m94 : 43|1@1+ (1,0) [0|0] "" Vector__XXX
 SG_ PMR_a095_motorRPM m95 : 43|12@1- (10,0) [0|0] "" Vector__XXX
 SG_ PMR_a010_DI_autonomyHealth m10 : 44|1@1+ (1,0) [0|0] "" Vector__XXX
 SG_ PMR_a094_wwdErrCounter m94 : 44|4@1+ (1,0) [0|0] "" Vector__XXX
 SG_ PMR_a034_torqueType m34 : 45|2@1+ (1,0) [0|0] "" Vector__XXX
 SG_ PMR_a036_timeSinceIdle m36 : 46|6@1+ (0.16,0) [0|0] "" Vector__XXX
 SG_ PMR_a096_armingConditionsMet m96 : 46|1@1+ (1,0) [0|0] "" Vector__XXX
 SG_ PMR_a000_alertDataW2 m0 : 48|16@1+ (1,0) [0|0] "" Vector__XXX
 SG_ PMR_a001_w2 m1 : 48|16@1+ (1,0) [0|0] "" Vector__XXX
 SG_ PMR_a002_torqueAccelWindow m2 : 48|13@1- (2,0) [0|0] "" Vector__XXX
 SG_ PMR_a004_torqueDecelWindow m4 : 48|13@1- (2,0) [0|0] "" Vector__XXX
 SG_ PMR_a008_crc_msw m8 : 48|16@1+ (1,0) [0|0] "" Vector__XXX
 SG_ PMR_a012_badValue2 m12 : 48|16@1+ (1,0) [0|0] "" Vector__XXX
 SG_ PMR_a013_errorType m13 : 48|3@1+ (1,0) [0|0] "" Vector__XXX
 SG_ PMR_a018_w2 m18 : 48|16@1+ (1,0) [0|0] "" Vector__XXX
 SG_ PMR_a027_w2 m27 : 48|16@1+ (1,0) [0|0] "" Vector__XXX
 SG_ PMR_a028_pedalPos m28 : 48|8@1+ (0.4,0) [0|0] "" Vector__XXX
 SG_ PMR_a031_stackSize m31 : 48|14@1+ (1,0) [0|0] "" Vector__XXX
 SG_ PMR_a032_w2 m32 : 48|16@1+ (1,0) [0|0] "" Vector__XXX
 SG_ PMR_a034_motorRPM m34 : 48|16@1- (1,0) [0|0] "" Vector__XXX
 SG_ PMR_a055_notReady m55 : 48|1@1+ (1,0) [0|0] "" Vector__XXX
 SG_ PMR_a056_errorType m56 : 48|3@1+ (1,0) [0|0] "" Vector__XXX
 SG_ PMR_a057_badValue2 m57 : 48|16@1+ (1,0) [0|0] "" Vector__XXX
 SG_ PMR_a062_errorType m62 : 48|4@1+ (1,0) [0|0] "" Vector__XXX
 SG_ PMR_a094_fwdErrCounter m94 : 48|4@1+ (1,0) [0|0] "" Vector__XXX
 SG_ PMR_a096_safetyICstate m96 : 48|3@1+ (1,0) [0|0] "" Vector__XXX
 SG_ PMR_a055_noCarrier m55 : 49|1@1+ (1,0) [0|0] "" Vector__XXX
 SG_ PMR_a011_currentVref m11 : 50|8@1+ (0.04,0) [0|0] "" Vector__XXX
 SG_ PMR_a055_phaseOutOfSpec m55 : 50|1@1+ (1,0) [0|0] "" Vector__XXX
 SG_ PMR_a055_diElecAngleMismatch m55 : 51|1@1+ (1,0) [0|0] "" Vector__XXX
 SG_ PMR_a036_ovfStackId m36 : 52|4@1+ (1,0) [0|0] "" Vector__XXX
 SG_ PMR_a055_diSpeedMismatch m55 : 52|1@1+ (1,0) [0|0] "" Vector__XXX
 SG_ PMR_a094_safetyICstate m94 : 52|3@1+ (1,0) [0|0] "" Vector__XXX
 SG_ PMR_a055_claMIA m55 : 53|1@1+ (1,0) [0|0] "" Vector__XXX
 SG_ PMR_a055_diMIA m55 : 54|1@1+ (1,0) [0|0] "" Vector__XXX
 SG_ PMR_a055_diElecAngleMismatchWarn m55 : 55|1@1+ (1,0) [0|0] "" Vector__XXX
 SG_ PMR_a036_inTxISR m36 : 56|1@1+ (1,0) [0|0] "" Vector__XXX
 SG_ PMR_a095_wwdErrCounter m95 : 56|4@1+ (1,0) [0|0] "" Vector__XXX
 SG_ PMR_a036_inTxHWI m36 : 57|1@1+ (1,0) [0|0] "" Vector__XXX
 SG_ PMR_a011_badPhaseAsample m11 : 58|1@1+ (1,0) [0|0] "" Vector__XXX
 SG_ PMR_a036_inRxHWI m36 : 58|1@1+ (1,0) [0|0] "" Vector__XXX
 SG_ PMR_a011_badPhaseBsample m11 : 59|1@1+ (1,0) [0|0] "" Vector__XXX
 SG_ PMR_a036_in1kHzSWI m36 : 59|1@1+ (1,0) [0|0] "" Vector__XXX
 SG_ PMR_a011_sampleFreeze m11 : 60|1@1+ (1,0) [0|0] "" Vector__XXX
 SG_ PMR_a036_in1kHzCLK m36 : 60|1@1+ (1,0) [0|0] "" Vector__XXX
 SG_ PMR_a095_fwdErrCounter m95 : 60|4@1+ (1,0) [0|0] "" Vector__XXX
 SG_ PMR_a011_rateOfChangeIrrational m11 : 61|1@1+ (1,0) [0|0] "" Vector__XXX
 SG_ PMR_a036_in100HzCLK m36 : 61|1@1+ (1,0) [0|0] "" Vector__XXX
 SG_ PMR_a011_currentReadingIrrational m11 : 62|1@1+ (1,0) [0|0] "" Vector__XXX
 SG_ PMR_a036_in10HzCLK m36 : 62|1@1+ (1,0) [0|0] "" Vector__XXX
 SG_ PMR_a011_vrefIrrational m11 : 63|1@1+ (1,0) [0|0] "" Vector__XXX
 SG_ PMR_a036_in1HzCLK m36 : 63|1@1+ (1,0) [0|0] "" Vector__XXX

BO_ 1448 EPBR_alertLog: 8 Vector__XXX
 SG_ EPBR_alertID M : 0|9@1+ (1,0) [0|0] "" Vector__XXX
 SG_ EPBR_alertState : 15|1@1+ (1,0) [0|0] "" Vector__XXX
 SG_ EPBR_a000_alertDataW0 m0 : 16|16@1+ (1,0) [0|0] "" Vector__XXX
 SG_ EPBR_a001_InternalWatchdog m1 : 16|1@1+ (1,0) [0|0] "" Vector__XXX
 SG_ EPBR_a002_CPUUndervoltage m2 : 16|1@1+ (1,0) [0|0] "" Vector__XXX
 SG_ EPBR_a003_AssertID m3 : 16|16@1+ (1,0) [0|0] "" Vector__XXX
 SG_ EPBR_a005_busID0 m5 : 16|4@1+ (1,0) [0|0] "" Vector__XXX
 SG_ EPBR_a006_busID m6 : 16|4@1+ (1,0) [0|0] "" Vector__XXX
 SG_ EPBR_a012_ClockError m12 : 16|1@1+ (1,0) [0|0] "" Vector__XXX
 SG_ EPBR_a013_LogQueueFull m13 : 16|1@1+ (1,0) [0|0] "" Vector__XXX
 SG_ EPBR_a015_NVMMMemOverflow m15 : 16|1@1+ (1,0) [0|0] "" Vector__XXX
 SG_ EPBR_a016_NVMMRecordID m16 : 16|16@1+ (1,0) [0|0] "" Vector__XXX
 SG_ EPBR_a021_Task1msLate m21 : 16|1@1+ (1,0) [0|0] "" Vector__XXX
 SG_ EPBR_a022_TaskInitErrorCount m22 : 16|8@1+ (1,0) [0|0] "" Vector__XXX
 SG_ EPBR_a030_logId m30 : 16|4@1+ (1,0) [0|0] "" Vector__XXX
 SG_ EPBR_a031_uds_bytes_0 m31 : 16|8@1+ (1,0) [0|0] "" Vector__XXX
 SG_ EPBR_a041_CPULoadTotal m41 : 16|8@1+ (1,0) [0|0] "" Vector__XXX
 SG_ EPBR_a042_Usage1msTask m42 : 16|8@1+ (1,0) [0|0] "" Vector__XXX
 SG_ EPBR_a043_CallTrace0 m43 : 16|24@1+ (1,0) [0|0] "" Vector__XXX
 SG_ EPBR_a044_CallTrace0 m44 : 16|24@1+ (1,0) [0|0] "" Vector__XXX
 SG_ EPBR_a045_CallTrace0 m45 : 16|24@1+ (1,0) [0|0] "" Vector__XXX
 SG_ EPBR_a046_CallTrace0 m46 : 16|24@1+ (1,0) [0|0] "" Vector__XXX
 SG_ EPBR_a057_VEH_cpControl m57 : 16|1@1+ (1,0) [0|0] "" Vector__XXX
 SG_ EPBR_a058_voltageDrop m58 : 16|12@1+ (0.005443676098,0) [0|0] "" Vector__XXX
 SG_ EPBR_a059_voltageDrop m59 : 16|12@1+ (0.005443676098,0) [0|0] "" Vector__XXX
 SG_ EPBR_a060_lockoutDisabled m60 : 16|1@1+ (1,0) [0|0] "" Vector__XXX
 SG_ EPBR_a063_switchChannel m63 : 16|8@1+ (1,0) [0|0] "" Vector__XXX
 SG_ EPBR_a064_busBitField m64 : 16|8@1+ (1,0) [0|0] "" Vector__XXX
 SG_ EPBR_a081_VEH_defogInfoMessage m81 : 16|1@1+ (1,0) [0|0] "" Vector__XXX
 SG_ EPBR_a082_RIPC_epbPrivateState m82 : 16|1@1+ (1,0) [0|0] "" Vector__XXX
 SG_ EPBR_a083_LIPC_epbPrivateState m83 : 16|1@1+ (1,0) [0|0] "" Vector__XXX
 SG_ EPBR_a084_CH_StatusC m84 : 16|1@1+ (1,0) [0|0] "" Vector__XXX
 SG_ EPBR_a085_PARTY_buttonStatus m85 : 16|1@1+ (1,0) [0|0] "" Vector__XXX
 SG_ EPBR_a086_VEH_LVBMS_statusHigh m86 : 16|1@1+ (1,0) [0|0] "" Vector__XXX
 SG_ EPBR_a087_VEH_temperature m87 : 16|1@1+ (1,0) [0|0] "" Vector__XXX
 SG_ EPBR_a088_VEH_temperature m88 : 16|1@1+ (1,0) [0|0] "" Vector__XXX
 SG_ EPBR_a089_PARTY_party1 m89 : 16|1@1+ (1,0) [0|0] "" Vector__XXX
 SG_ EPBR_a090_VEH_chNm m90 : 16|1@1+ (1,0) [0|0] "" Vector__XXX
 SG_ EPBR_a091_VEH_faultsAndExtras m91 : 16|1@1+ (1,0) [0|0] "" Vector__XXX
 SG_ EPBR_a092_VEH_restraintStatus m92 : 16|1@1+ (1,0) [0|0] "" Vector__XXX
 SG_ EPBR_a093_VEH_restraintStatus m93 : 16|1@1+ (1,0) [0|0] "" Vector__XXX
 SG_ EPBR_a094_VEH_sysStatus m94 : 16|1@1+ (1,0) [0|0] "" Vector__XXX
 SG_ EPBR_a095_PT_ptNm m95 : 16|1@1+ (1,0) [0|0] "" Vector__XXX
 SG_ EPBR_a096_VEH_status m96 : 16|1@1+ (1,0) [0|0] "" Vector__XXX
 SG_ EPBR_a097_VEH_HVStatus m97 : 16|1@1+ (1,0) [0|0] "" Vector__XXX
 SG_ EPBR_a098_CH_torque m98 : 16|1@1+ (1,0) [0|0] "" Vector__XXX
 SG_ EPBR_a099_VEH_oocStatus m99 : 16|1@1+ (1,0) [0|0] "" Vector__XXX
 SG_ EPBR_a100_VEH m100 : 16|1@1+ (1,0) [0|0] "" Vector__XXX
 SG_ EPBR_a101_VEH_state m101 : 16|1@1+ (1,0) [0|0] "" Vector__XXX
 SG_ EPBR_a102_VEH_faultsAndExtras m102 : 16|1@1+ (1,0) [0|0] "" Vector__XXX
 SG_ EPBR_a103_VEH_hvsNm m103 : 16|1@1+ (1,0) [0|0] "" Vector__XXX
 SG_ EPBR_a104_PARTY_redundantBrakingControl m104 : 16|1@1+ (1,0) [0|0] "" Vector__XXX
 SG_ EPBR_a105_VEH_states m105 : 16|1@1+ (1,0) [0|0] "" Vector__XXX
 SG_ EPBR_a106_VEH_dcdcStatus m106 : 16|1@1+ (1,0) [0|0] "" Vector__XXX
 SG_ EPBR_a107_VEH_hvsNm m107 : 16|1@1+ (1,0) [0|0] "" Vector__XXX
 SG_ EPBR_a108_VEH_hvStatus m108 : 16|1@1+ (1,0) [0|0] "" Vector__XXX
 SG_ EPBR_a109_PARTY_status m109 : 16|1@1+ (1,0) [0|0] "" Vector__XXX
 SG_ EPBR_a110_VEH_powerRequests m110 : 16|1@1+ (1,0) [0|0] "" Vector__XXX
 SG_ EPBR_a111_VEH_internalStatus m111 : 16|1@1+ (1,0) [0|0] "" Vector__XXX
 SG_ EPBR_a112_VEH_internalStatus m112 : 16|1@1+ (1,0) [0|0] "" Vector__XXX
 SG_ EPBR_a113_VEH_ethNm m113 : 16|1@1+ (1,0) [0|0] "" Vector__XXX
 SG_ EPBR_a114_PARTY_status m114 : 16|1@1+ (1,0) [0|0] "" Vector__XXX
 SG_ EPBR_a115_VEH_vehNm m115 : 16|1@1+ (1,0) [0|0] "" Vector__XXX
 SG_ EPBR_a116_LIPC_doorStatus m116 : 16|1@1+ (1,0) [0|0] "" Vector__XXX
 SG_ EPBR_a117_LIPC_doorStatus m117 : 16|1@1+ (1,0) [0|0] "" Vector__XXX
 SG_ EPBR_a118_VEH_vehNm m118 : 16|1@1+ (1,0) [0|0] "" Vector__XXX
 SG_ EPBR_a119_VEH_steerAngle m119 : 16|1@1+ (1,0) [0|0] "" Vector__XXX
 SG_ EPBR_a120_PARTY_chassisCntl m120 : 16|1@1+ (1,0) [0|0] "" Vector__XXX
 SG_ EPBR_a121_caliperState m121 : 16|4@1+ (1,0) [0|0] "" Vector__XXX
 SG_ EPBR_a122_filteredCurrentCal m122 : 16|12@1+ (0.01,0) [0|0] "" Vector__XXX
 SG_ EPBR_a123_filteredCurrentCal m123 : 16|12@1+ (0.01,0) [0|0] "" Vector__XXX
 SG_ EPBR_a124_calOutOfBoundsData m124 : 16|1@1+ (1,0) [0|0] "" Vector__XXX
 SG_ EPBR_a125_pvFilt m125 : 16|12@1+ (0.005443676098,0) [0|0] "" Vector__XXX
 SG_ EPBR_a126_pvFilt m126 : 16|12@1+ (0.005443676098,0) [0|0] "" Vector__XXX
 SG_ EPBR_a127_pvFilt m127 : 16|12@1+ (0.005443676098,0) [0|0] "" Vector__XXX
 SG_ EPBR_a128_pvFilt m128 : 16|12@1+ (0.005443676098,0) [0|0] "" Vector__XXX
 SG_ EPBR_a129_VEH_occupancy m129 : 16|1@1+ (1,0) [0|0] "" Vector__XXX
 SG_ EPBR_a134_pvFilt m134 : 16|12@1+ (0.005443676098,0) [0|0] "" Vector__XXX
 SG_ EPBR_a135_pvFilt m135 : 16|12@1+ (0.005443676098,0) [0|0] "" Vector__XXX
 SG_ EPBR_a136_pvFilt m136 : 16|12@1+ (0.005443676098,0) [0|0] "" Vector__XXX
 SG_ EPBR_a137_pvFilt m137 : 16|12@1+ (0.005443676098,0) [0|0] "" Vector__XXX
 SG_ EPBR_a138_localState m138 : 16|3@1+ (1,0) [0|0] "" Vector__XXX
 SG_ EPBR_a139_localState m139 : 16|3@1+ (1,0) [0|0] "" Vector__XXX
 SG_ EPBR_a140_stateTime m140 : 16|32@1+ (1,0) [0|0] "" Vector__XXX
 SG_ EPBR_a141_fromState m141 : 16|5@1+ (1,0) [0|0] "" Vector__XXX
 SG_ EPBR_a170_pvFilt m170 : 16|12@1+ (0.005443676098,0) [0|0] "" Vector__XXX
 SG_ EPBR_a171_pvFilt m171 : 16|12@1+ (0.005443676098,0) [0|0] "" Vector__XXX
 SG_ EPBR_a173_esmState m173 : 16|5@1+ (1,0) [0|0] "" Vector__XXX
 SG_ EPBR_a174_esmState m174 : 16|5@1+ (1,0) [0|0] "" Vector__XXX
 SG_ EPBR_a175_esmState m175 : 16|5@1+ (1,0) [0|0] "" Vector__XXX
 SG_ EPBR_a176_esmState m176 : 16|5@1+ (1,0) [0|0] "" Vector__XXX
 SG_ EPBR_a177_esmState m177 : 16|5@1+ (1,0) [0|0] "" Vector__XXX
 SG_ EPBR_a178_localCaliperState m178 : 16|3@1+ (1,0) [0|0] "" Vector__XXX
 SG_ EPBR_a179_esmState m179 : 16|5@1+ (1,0) [0|0] "" Vector__XXX
 SG_ EPBR_a180_esmOpTrigger m180 : 16|6@1+ (1,0) [0|0] "" Vector__XXX
 SG_ EPBR_a181_grade m181 : 16|7@1- (1,0) [0|0] "" Vector__XXX
 SG_ EPBR_a182_epbSystemStatus m182 : 16|4@1+ (1,0) [0|0] "" Vector__XXX
 SG_ EPBR_a183_isRetransmit m183 : 16|1@1+ (1,0) [0|0] "" Vector__XXX
 SG_ EPBR_a184_esmOpTrigger m184 : 16|6@1+ (1,0) [0|0] "" Vector__XXX
 SG_ EPBR_a185_summonFaultReason m185 : 16|5@1+ (1,0) [0|0] "" Vector__XXX
 SG_ EPBR_a186_esmOpTrigger m186 : 16|6@1+ (1,0) [0|0] "" Vector__XXX
 SG_ EPBR_a187_esmOpTrigger m187 : 16|6@1+ (1,0) [0|0] "" Vector__XXX
 SG_ EPBR_a188_esmOpTrigger m188 : 16|6@1+ (1,0) [0|0] "" Vector__XXX
 SG_ EPBR_a189_esmOpTrigger m189 : 16|6@1+ (1,0) [0|0] "" Vector__XXX
 SG_ EPBR_a190_esmState m190 : 16|5@1+ (1,0) [0|0] "" Vector__XXX
 SG_ EPBR_a191_esmState m191 : 16|5@1+ (1,0) [0|0] "" Vector__XXX
 SG_ EPBR_a198_voltageAvgDelta m198 : 16|9@1+ (0.043549408784,0) [0|0] "" Vector__XXX
 SG_ EPBR_a202_localEpbConfig m202 : 16|4@1+ (1,0) [0|0] "" Vector__XXX
 SG_ EPBR_a203_gtwConfig m203 : 16|4@1+ (1,0) [0|0] "" Vector__XXX
 SG_ EPBR_a210_driverLeftForScore m210 : 16|1@1+ (1,0) [0|0] "" Vector__XXX
 SG_ EPBR_a216_noData m216 : 16|1@1+ (1,0) [0|0] "" Vector__XXX
 SG_ EPBR_a217_byte4 m217 : 16|8@1+ (1,0) [0|0] "" Vector__XXX
 SG_ EPBR_a225_esmOpTrigger m225 : 16|6@1+ (1,0) [0|0] "" Vector__XXX
 SG_ EPBR_a241_desiredState m241 : 16|1@1+ (1,0) [0|0] "" Vector__XXX
 SG_ EPBR_a242_hvcDesiredState m242 : 16|1@1+ (1,0) [0|0] "" Vector__XXX
 SG_ EPBR_a243_brakeMasterCylPress m243 : 16|1@1+ (1,0) [0|0] "" Vector__XXX
 SG_ EPBR_a244_permissiveMode m244 : 16|1@1+ (1,0) [0|0] "" Vector__XXX
 SG_ EPBR_a246_previousState m246 : 16|5@1+ (1,0) [0|0] "" Vector__XXX
 SG_ EPBR_a247_esmState m247 : 16|5@1+ (1,0) [0|0] "" Vector__XXX
 SG_ EPBR_a248_esmState m248 : 16|5@1+ (1,0) [0|0] "" Vector__XXX
 SG_ EPBR_a249_previousState m249 : 16|5@1+ (1,0) [0|0] "" Vector__XXX
 SG_ EPBR_a250_esmSpeedClass m250 : 16|3@1+ (1,0) [0|0] "" Vector__XXX
 SG_ EPBR_a251_currentVariance m251 : 16|12@1+ (0.01,0) [0|0] "" Vector__XXX
 SG_ EPBR_a253_esmState m253 : 16|5@1+ (1,0) [0|0] "" Vector__XXX
 SG_ EPBR_a256_esmState m256 : 16|5@1+ (1,0) [0|0] "" Vector__XXX
 SG_ EPBR_a262_inputVoltageTooLow m262 : 16|1@1+ (1,0) [0|0] "" Vector__XXX
 SG_ EPBR_a263_esmState m263 : 16|5@1+ (1,0) [0|0] "" Vector__XXX
 SG_ EPBR_a264_uiWinchModeRequestExit m264 : 16|1@1+ (1,0) [0|0] "" Vector__XXX
 SG_ EPBR_a272_expectedState m272 : 16|2@1+ (1,0) [0|0] "" Vector__XXX
 SG_ EPBR_a300_harnessId m300 : 16|8@1+ (1,0) [0|0] "" Vector__XXX
 SG_ EPBR_a301_setSpeed m301 : 16|16@1+ (0.05,0) [0|0] "" Vector__XXX
 SG_ EPBR_a302_pistonPosition m302 : 16|13@1- (9.768009768009769,0) [0|0] "" Vector__XXX
 SG_ EPBR_a303_currentVariance m303 : 16|12@1+ (0.01,0) [0|0] "" Vector__XXX
 SG_ EPBR_a350_ensPeriod m350 : 16|16@1+ (0.0001,0) [0|0] "" Vector__XXX
 SG_ EPBR_a352_pointsAboveThreshold m352 : 16|10@1+ (1,0) [0|0] "" Vector__XXX
 SG_ EPBR_a353_alertPath m353 : 16|2@1+ (1,0) [0|0] "" Vector__XXX
 SG_ EPBR_a355_brakeHwConfig m355 : 16|4@1+ (1,0) [0|0] "" Vector__XXX
 SG_ EPBR_a357_epbSystemStatus m357 : 16|4@1+ (1,0) [0|0] "" Vector__XXX
 SG_ EPBR_a358_epbSystemStatus m358 : 16|4@1+ (1,0) [0|0] "" Vector__XXX
 SG_ EPBR_a362_brakeMasterCylPress m362 : 16|12@1- (0.1,130) [0|0] "" Vector__XXX
 SG_ EPBR_a363_brakeMasterCylPress m363 : 16|12@1- (0.1,130) [0|0] "" Vector__XXX
 SG_ EPBR_a364_masterCylOffsetComp m364 : 16|12@1- (0.05,0) [0|0] "" Vector__XXX
 SG_ EPBR_a365_epbSystemStatus m365 : 16|4@1+ (1,0) [0|0] "" Vector__XXX
 SG_ EPBR_a366_epbSystemStatus m366 : 16|4@1+ (1,0) [0|0] "" Vector__XXX
 SG_ EPBR_a370_messageID m370 : 16|11@1+ (1,0) [0|0] "" Vector__XXX
 SG_ EPBR_a002_PowerOnReset m2 : 17|1@1+ (1,0) [0|0] "" Vector__XXX
 SG_ EPBR_a012_FlashError m12 : 17|1@1+ (1,0) [0|0] "" Vector__XXX
 SG_ EPBR_a013_ClearQueueFull m13 : 17|1@1+ (1,0) [0|0] "" Vector__XXX
 SG_ EPBR_a015_NVMMFilesystemError m15 : 17|1@1+ (1,0) [0|0] "" Vector__XXX
 SG_ EPBR_a021_Task1msStarved m21 : 17|1@1+ (1,0) [0|0] "" Vector__XXX
 SG_ EPBR_a060_resetUnlocked m60 : 17|1@1+ (1,0) [0|0] "" Vector__XXX
 SG_ EPBR_a082_RIPC_remoteHSD m82 : 17|1@1+ (1,0) [0|0] "" Vector__XXX
 SG_ EPBR_a083_LIPC_remoteHSD m83 : 17|1@1+ (1,0) [0|0] "" Vector__XXX
 SG_ EPBR_a086_VEH_LVBMS_statusLow m86 : 17|1@1+ (1,0) [0|0] "" Vector__XXX
 SG_ EPBR_a087_VEH_thermalControl m87 : 17|1@1+ (1,0) [0|0] "" Vector__XXX
 SG_ EPBR_a088_VEH_thermalControl m88 : 17|1@1+ (1,0) [0|0] "" Vector__XXX
 SG_ EPBR_a089_PARTY_status m89 : 17|1@1+ (1,0) [0|0] "" Vector__XXX
 SG_ EPBR_a090_VEH_state m90 : 17|1@1+ (1,0) [0|0] "" Vector__XXX
 SG_ EPBR_a091_VEH_info m91 : 17|1@1+ (1,0) [0|0] "" Vector__XXX
 SG_ EPBR_a092_VEH_switchStatus m92 : 17|1@1+ (1,0) [0|0] "" Vector__XXX
 SG_ EPBR_a093_VEH_switchStatus m93 : 17|1@1+ (1,0) [0|0] "" Vector__XXX
 SG_ EPBR_a094_PARTY_sysStatus m94 : 17|1@1+ (1,0) [0|0] "" Vector__XXX
 SG_ EPBR_a095_PT_status m95 : 17|1@1+ (1,0) [0|0] "" Vector__XXX
 SG_ EPBR_a096_CH_status m96 : 17|1@1+ (1,0) [0|0] "" Vector__XXX
 SG_ EPBR_a097_VEH_state m97 : 17|1@1+ (1,0) [0|0] "" Vector__XXX
 SG_ EPBR_a098_VEH_hvStatus m98 : 17|1@1+ (1,0) [0|0] "" Vector__XXX
 SG_ EPBR_a100_PARTY m100 : 17|1@1+ (1,0) [0|0] "" Vector__XXX
 SG_ EPBR_a101_PARTY_locState m101 : 17|1@1+ (1,0) [0|0] "" Vector__XXX
 SG_ EPBR_a102_VEH_feedbackStatus m102 : 17|1@1+ (1,0) [0|0] "" Vector__XXX
 SG_ EPBR_a103_VEH_vehNm m103 : 17|1@1+ (1,0) [0|0] "" Vector__XXX
 SG_ EPBR_a104_CH_redundantBrakingControl m104 : 17|1@1+ (1,0) [0|0] "" Vector__XXX
 SG_ EPBR_a105_VEH_chNm m105 : 17|1@1+ (1,0) [0|0] "" Vector__XXX
 SG_ EPBR_a106_VEH_thermalControl m106 : 17|1@1+ (1,0) [0|0] "" Vector__XXX
 SG_ EPBR_a107_VEH_vehNm m107 : 17|1@1+ (1,0) [0|0] "" Vector__XXX
 SG_ EPBR_a108_VEH_temperature m108 : 17|1@1+ (1,0) [0|0] "" Vector__XXX
 SG_ EPBR_a109_PARTY_inertial2 m109 : 17|1@1+ (1,0) [0|0] "" Vector__XXX
 SG_ EPBR_a110_VEH_carState m110 : 17|1@1+ (1,0) [0|0] "" Vector__XXX
 SG_ EPBR_a111_VEH_status m111 : 17|1@1+ (1,0) [0|0] "" Vector__XXX
 SG_ EPBR_a112_VEH_status m112 : 17|1@1+ (1,0) [0|0] "" Vector__XXX
 SG_ EPBR_a113_VEH_hvacRequest m113 : 17|1@1+ (1,0) [0|0] "" Vector__XXX
 SG_ EPBR_a114_PARTY_wheelSpeeds m114 : 17|1@1+ (1,0) [0|0] "" Vector__XXX
 SG_ EPBR_a115_VEH_authentication m115 : 17|1@1+ (1,0) [0|0] "" Vector__XXX
 SG_ EPBR_a116_RIPC_doorStatus m116 : 17|1@1+ (1,0) [0|0] "" Vector__XXX
 SG_ EPBR_a117_RIPC_doorStatus m117 : 17|1@1+ (1,0) [0|0] "" Vector__XXX
 SG_ EPBR_a118_VEH_lighting m118 : 17|1@1+ (1,0) [0|0] "" Vector__XXX
 SG_ EPBR_a119_VEH_leftStalk m119 : 17|1@1+ (1,0) [0|0] "" Vector__XXX
 SG_ EPBR_a120_VEH_systemStatus m120 : 17|1@1+ (1,0) [0|0] "" Vector__XXX
 SG_ EPBR_a183_localCdpState m183 : 17|2@1+ (1,0) [0|0] "" Vector__XXX
 SG_ EPBR_a210_driverLeftForAllSensors m210 : 17|1@1+ (1,0) [0|0] "" Vector__XXX
 SG_ EPBR_a216_spiFault m216 : 17|1@1+ (1,0) [0|0] "" Vector__XXX
 SG_ EPBR_a241_currentState m241 : 17|1@1+ (1,0) [0|0] "" Vector__XXX
 SG_ EPBR_a242_hvcCurrentState m242 : 17|1@1+ (1,0) [0|0] "" Vector__XXX
 SG_ EPBR_a243_brakeMasterCylPressQF m243 : 17|1@1+ (1,0) [0|0] "" Vector__XXX
 SG_ EPBR_a262_notStopped m262 : 17|1@1+ (1,0) [0|0] "" Vector__XXX
 SG_ EPBR_a264_uiGearStripParkPressed m264 : 17|1@1+ (1,0) [0|0] "" Vector__XXX
 SG_ EPBR_a012_SoftwareReset m12 : 18|1@1+ (1,0) [0|0] "" Vector__XXX
 SG_ EPBR_a015_NVMMRecordIDError m15 : 18|1@1+ (1,0) [0|0] "" Vector__XXX
 SG_ EPBR_a021_Task1msMissed m21 : 18|1@1+ (1,0) [0|0] "" Vector__XXX
 SG_ EPBR_a082_RIPC_railStatus m82 : 18|1@1+ (1,0) [0|0] "" Vector__XXX
 SG_ EPBR_a083_LIPC_railStatus m83 : 18|1@1+ (1,0) [0|0] "" Vector__XXX
 SG_ EPBR_a086_VEH_status m86 : 18|1@1+ (1,0) [0|0] "" Vector__XXX
 SG_ EPBR_a087_VEH_torque m87 : 18|1@1+ (1,0) [0|0] "" Vector__XXX
 SG_ EPBR_a088_VEH_torque m88 : 18|1@1+ (1,0) [0|0] "" Vector__XXX
 SG_ EPBR_a089_VEH_status m89 : 18|1@1+ (1,0) [0|0] "" Vector__XXX
 SG_ EPBR_a090_PARTY_eacMonitor m90 : 18|1@1+ (1,0) [0|0] "" Vector__XXX
 SG_ EPBR_a091_VEH_state m91 : 18|1@1+ (1,0) [0|0] "" Vector__XXX
 SG_ EPBR_a092_VEH_seatStatus2 m92 : 18|1@1+ (1,0) [0|0] "" Vector__XXX
 SG_ EPBR_a093_VEH_seatStatus2 m93 : 18|1@1+ (1,0) [0|0] "" Vector__XXX
 SG_ EPBR_a098_VEH_status m98 : 18|1@1+ (1,0) [0|0] "" Vector__XXX
 SG_ EPBR_a100_PT m100 : 18|1@1+ (1,0) [0|0] "" Vector__XXX
 SG_ EPBR_a101_LIPC_externalWatchdogHeartBeat m101 : 18|1@1+ (1,0) [0|0] "" Vector__XXX
 SG_ EPBR_a102_VEH_sensorStatus m102 : 18|1@1+ (1,0) [0|0] "" Vector__XXX
 SG_ EPBR_a103_VEH_status m103 : 18|1@1+ (1,0) [0|0] "" Vector__XXX
 SG_ EPBR_a104_LIPC_status m104 : 18|1@1+ (1,0) [0|0] "" Vector__XXX
 SG_ EPBR_a105_VEH_dampingStates m105 : 18|1@1+ (1,0) [0|0] "" Vector__XXX
 SG_ EPBR_a106_VEH_dcdcRailStatus m106 : 18|1@1+ (1,0) [0|0] "" Vector__XXX
 SG_ EPBR_a107_VEH_status m107 : 18|1@1+ (1,0) [0|0] "" Vector__XXX
 SG_ EPBR_a108_VEH_thermalControl m108 : 18|1@1+ (1,0) [0|0] "" Vector__XXX
 SG_ EPBR_a109_PARTY_nearDeploy m109 : 18|1@1+ (1,0) [0|0] "" Vector__XXX
 SG_ EPBR_a110_VEH_carConfig m110 : 18|1@1+ (1,0) [0|0] "" Vector__XXX
 SG_ EPBR_a111_VEH_vehNm m111 : 18|1@1+ (1,0) [0|0] "" Vector__XXX
 SG_ EPBR_a112_VEH_vehNm m112 : 18|1@1+ (1,0) [0|0] "" Vector__XXX
 SG_ EPBR_a113_VEH_chargeRequest m113 : 18|1@1+ (1,0) [0|0] "" Vector__XXX
 SG_ EPBR_a114_VEH_wheelSpeeds m114 : 18|1@1+ (1,0) [0|0] "" Vector__XXX
 SG_ EPBR_a115_VEH_BLEResetRequest m115 : 18|1@1+ (1,0) [0|0] "" Vector__XXX
 SG_ EPBR_a116_RIPC_epbManagement m116 : 18|1@1+ (1,0) [0|0] "" Vector__XXX
 SG_ EPBR_a117_BDY_epbmStatus m117 : 18|1@1+ (1,0) [0|0] "" Vector__XXX
 SG_ EPBR_a118_VEH_sensors m118 : 18|1@1+ (1,0) [0|0] "" Vector__XXX
 SG_ EPBR_a119_VEH_rightStalk m119 : 18|1@1+ (1,0) [0|0] "" Vector__XXX
 SG_ EPBR_a120_CH_chassisCntl m120 : 18|1@1+ (1,0) [0|0] "" Vector__XXX
 SG_ EPBR_a210_driverLeftForDoorOpen m210 : 18|1@1+ (1,0) [0|0] "" Vector__XXX
 SG_ EPBR_a216_CRC_error m216 : 18|1@1+ (1,0) [0|0] "" Vector__XXX
 SG_ EPBR_a241_diKeepAlive m241 : 18|1@1+ (1,0) [0|0] "" Vector__XXX
 SG_ EPBR_a242_contDesiredState m242 : 18|1@1+ (1,0) [0|0] "" Vector__XXX
 SG_ EPBR_a243_drivetrainType m243 : 18|1@1+ (1,0) [0|0] "" Vector__XXX
 SG_ EPBR_a262_notSecure m262 : 18|1@1+ (1,0) [0|0] "" Vector__XXX
 SG_ EPBR_a264_uiControlsParkingBrakeRequest m264 : 18|1@1+ (1,0) [0|0] "" Vector__XXX
 SG_ EPBR_a272_actualState m272 : 18|2@1+ (1,0) [0|0] "" Vector__XXX
 SG_ EPBR_a353_gtwMia m353 : 18|1@1+ (1,0) [0|0] "" Vector__XXX
 SG_ EPBR_a012_CheckstopReset m12 : 19|1@1+ (1,0) [0|0] "" Vector__XXX
 SG_ EPBR_a021_Task10msLate m21 : 19|1@1+ (1,0) [0|0] "" Vector__XXX
 SG_ EPBR_a082_RIPC_remoteMux m82 : 19|1@1+ (1,0) [0|0] "" Vector__XXX
 SG_ EPBR_a083_LIPC_HSDFaults m83 : 19|1@1+ (1,0) [0|0] "" Vector__XXX
 SG_ EPBR_a086_VEH_12VBatteryStatus m86 : 19|1@1+ (1,0) [0|0] "" Vector__XXX
 SG_ EPBR_a087_VEH_status m87 : 19|1@1+ (1,0) [0|0] "" Vector__XXX
 SG_ EPBR_a088_VEH_status m88 : 19|1@1+ (1,0) [0|0] "" Vector__XXX
 SG_ EPBR_a089_BDY_party1 m89 : 19|1@1+ (1,0) [0|0] "" Vector__XXX
 SG_ EPBR_a090_CH_eacMonitor m90 : 19|1@1+ (1,0) [0|0] "" Vector__XXX
 SG_ EPBR_a092_VEH_vehNm m92 : 19|1@1+ (1,0) [0|0] "" Vector__XXX
 SG_ EPBR_a093_VEH_vehNm m93 : 19|1@1+ (1,0) [0|0] "" Vector__XXX
 SG_ EPBR_a098_VEH_thermalControl m98 : 19|1@1+ (1,0) [0|0] "" Vector__XXX
 SG_ EPBR_a100_CH m100 : 19|1@1+ (1,0) [0|0] "" Vector__XXX
 SG_ EPBR_a101_VEH_locState m101 : 19|1@1+ (1,0) [0|0] "" Vector__XXX
 SG_ EPBR_a102_VEH_rods m102 : 19|1@1+ (1,0) [0|0] "" Vector__XXX
 SG_ EPBR_a103_PT_ptNm m103 : 19|1@1+ (1,0) [0|0] "" Vector__XXX
 SG_ EPBR_a104_VEH_chNm m104 : 19|1@1+ (1,0) [0|0] "" Vector__XXX
 SG_ EPBR_a106_CH_dcdcRailStatus m106 : 19|1@1+ (1,0) [0|0] "" Vector__XXX
 SG_ EPBR_a107_VEH_thermalStatus m107 : 19|1@1+ (1,0) [0|0] "" Vector__XXX
 SG_ EPBR_a108_VEH_torque m108 : 19|1@1+ (1,0) [0|0] "" Vector__XXX
 SG_ EPBR_a109_PARTY_collision m109 : 19|1@1+ (1,0) [0|0] "" Vector__XXX
 SG_ EPBR_a110_VEH_time m110 : 19|1@1+ (1,0) [0|0] "" Vector__XXX
 SG_ EPBR_a111_RIPC_LVPowerState m111 : 19|1@1+ (1,0) [0|0] "" Vector__XXX
 SG_ EPBR_a112_LIPC_LVPowerState m112 : 19|1@1+ (1,0) [0|0] "" Vector__XXX
 SG_ EPBR_a113_VEH_vehicleControl m113 : 19|1@1+ (1,0) [0|0] "" Vector__XXX
 SG_ EPBR_a114_CH_wheelSpeeds m114 : 19|1@1+ (1,0) [0|0] "" Vector__XXX
 SG_ EPBR_a115_VEH_requests m115 : 19|1@1+ (1,0) [0|0] "" Vector__XXX
 SG_ EPBR_a116_PARTY_epbmStatus m116 : 19|1@1+ (1,0) [0|0] "" Vector__XXX
 SG_ EPBR_a117_BDY_restraintStatus m117 : 19|1@1+ (1,0) [0|0] "" Vector__XXX
 SG_ EPBR_a118_VEH_status m118 : 19|1@1+ (1,0) [0|0] "" Vector__XXX
 SG_ EPBR_a119_PARTY_rightStalk m119 : 19|1@1+ (1,0) [0|0] "" Vector__XXX
 SG_ EPBR_a120_PARTY_systemStatus m120 : 19|1@1+ (1,0) [0|0] "" Vector__XXX
 SG_ EPBR_a138_monitorState m138 : 19|3@1+ (1,0) [0|0] "" Vector__XXX
 SG_ EPBR_a139_monitorState m139 : 19|3@1+ (1,0) [0|0] "" Vector__XXX
 SG_ EPBR_a178_monitorCaliperState m178 : 19|3@1+ (1,0) [0|0] "" Vector__XXX
 SG_ EPBR_a183_remoteCdpState m183 : 19|2@1+ (1,0) [0|0] "" Vector__XXX
 SG_ EPBR_a210_driverLeftForUnbuckled m210 : 19|1@1+ (1,0) [0|0] "" Vector__XXX
 SG_ EPBR_a216_monitor_MIA m216 : 19|1@1+ (1,0) [0|0] "" Vector__XXX
 SG_ EPBR_a241_epbSysStatus m241 : 19|4@1+ (1,0) [0|0] "" Vector__XXX
 SG_ EPBR_a242_contCurrentState m242 : 19|1@1+ (1,0) [0|0] "" Vector__XXX
 SG_ EPBR_a243_DIR1torqueActual m243 : 19|1@1+ (1,0) [0|0] "" Vector__XXX
 SG_ EPBR_a262_chargeCableDefinitelyAttached m262 : 19|1@1+ (1,0) [0|0] "" Vector__XXX
 SG_ EPBR_a264_stalkParkPressed m264 : 19|1@1+ (1,0) [0|0] "" Vector__XXX
 SG_ EPBR_a353_uiMia m353 : 19|1@1+ (1,0) [0|0] "" Vector__XXX
 SG_ EPBR_a005_faults0 m5 : 20|12@1+ (1,0) [0|0] "" Vector__XXX
 SG_ EPBR_a006_fault m6 : 20|4@1+ (1,0) [0|0] "" Vector__XXX
 SG_ EPBR_a012_DebugReset m12 : 20|1@1+ (1,0) [0|0] "" Vector__XXX
 SG_ EPBR_a021_Task10msStarved m21 : 20|1@1+ (1,0) [0|0] "" Vector__XXX
 SG_ EPBR_a086_VEH_LVPowerState m86 : 20|1@1+ (1,0) [0|0] "" Vector__XXX
 SG_ EPBR_a087_PARTY_torque m87 : 20|1@1+ (1,0) [0|0] "" Vector__XXX
 SG_ EPBR_a088_PARTY_torque m88 : 20|1@1+ (1,0) [0|0] "" Vector__XXX
 SG_ EPBR_a089_BDY_status m89 : 20|1@1+ (1,0) [0|0] "" Vector__XXX
 SG_ EPBR_a098_VEH_temperature m98 : 20|1@1+ (1,0) [0|0] "" Vector__XXX
 SG_ EPBR_a100_OBD m100 : 20|1@1+ (1,0) [0|0] "" Vector__XXX
 SG_ EPBR_a101_BDY_locState m101 : 20|1@1+ (1,0) [0|0] "" Vector__XXX
 SG_ EPBR_a103_PT_status m103 : 20|1@1+ (1,0) [0|0] "" Vector__XXX
 SG_ EPBR_a104_VEH_bodyControls m104 : 20|1@1+ (1,0) [0|0] "" Vector__XXX
 SG_ EPBR_a106_CH_alertMatrix m106 : 20|1@1+ (1,0) [0|0] "" Vector__XXX
 SG_ EPBR_a107_VEH_bmbMinMax m107 : 20|1@1+ (1,0) [0|0] "" Vector__XXX
 SG_ EPBR_a108_VEH_status m108 : 20|1@1+ (1,0) [0|0] "" Vector__XXX
 SG_ EPBR_a109_VEH_status m109 : 20|1@1+ (1,0) [0|0] "" Vector__XXX
 SG_ EPBR_a110_VEH_updateStatus m110 : 20|1@1+ (1,0) [0|0] "" Vector__XXX
 SG_ EPBR_a111_RIPC_epbPrivateState m111 : 20|1@1+ (1,0) [0|0] "" Vector__XXX
 SG_ EPBR_a112_LIPC_epbPrivateState m112 : 20|1@1+ (1,0) [0|0] "" Vector__XXX
 SG_ EPBR_a113_VEH_vehicleControl2 m113 : 20|1@1+ (1,0) [0|0] "" Vector__XXX
 SG_ EPBR_a114_PARTY_party3 m114 : 20|1@1+ (1,0) [0|0] "" Vector__XXX
 SG_ EPBR_a115_VEH_requests2 m115 : 20|1@1+ (1,0) [0|0] "" Vector__XXX
 SG_ EPBR_a116_VEH_vehNm m116 : 20|1@1+ (1,0) [0|0] "" Vector__XXX
 SG_ EPBR_a117_VEH_prndStatus m117 : 20|1@1+ (1,0) [0|0] "" Vector__XXX
 SG_ EPBR_a118_VEH_okToUseHighPwr m118 : 20|1@1+ (1,0) [0|0] "" Vector__XXX
 SG_ EPBR_a119_CH_steerAngle m119 : 20|1@1+ (1,0) [0|0] "" Vector__XXX
 SG_ EPBR_a120_PARTY_torque m120 : 20|1@1+ (1,0) [0|0] "" Vector__XXX
 SG_ EPBR_a202_remoteEpbConfig m202 : 20|4@1+ (1,0) [0|0] "" Vector__XXX
 SG_ EPBR_a203_epbConfig m203 : 20|4@1+ (1,0) [0|0] "" Vector__XXX
 SG_ EPBR_a210_driverLeftForInactivity m210 : 20|1@1+ (1,0) [0|0] "" Vector__XXX
 SG_ EPBR_a242_hvState m242 : 20|3@1+ (1,0) [0|0] "" Vector__XXX
 SG_ EPBR_a243_DIR2torqueActual m243 : 20|1@1+ (1,0) [0|0] "" Vector__XXX
 SG_ EPBR_a262_chargeCablePotentiallyAttached m262 : 20|1@1+ (1,0) [0|0] "" Vector__XXX
 SG_ EPBR_a264_backupPrndParkPressed m264 : 20|1@1+ (1,0) [0|0] "" Vector__XXX
 SG_ EPBR_a355_epbHwConfig m355 : 20|4@1+ (1,0) [0|0] "" Vector__XXX
 SG_ EPBR_a012_ExternalReset m12 : 21|1@1+ (1,0) [0|0] "" Vector__XXX
 SG_ EPBR_a021_Task10msMissed m21 : 21|1@1+ (1,0) [0|0] "" Vector__XXX
 SG_ EPBR_a086_VEH_lightStatus m86 : 21|1@1+ (1,0) [0|0] "" Vector__XXX
 SG_ EPBR_a087_PARTY_status m87 : 21|1@1+ (1,0) [0|0] "" Vector__XXX
 SG_ EPBR_a088_PARTY_status m88 : 21|1@1+ (1,0) [0|0] "" Vector__XXX
 SG_ EPBR_a089_CH_status m89 : 21|1@1+ (1,0) [0|0] "" Vector__XXX
 SG_ EPBR_a098_VEH_torque m98 : 21|1@1+ (1,0) [0|0] "" Vector__XXX
 SG_ EPBR_a103_VEH_evseStatus m103 : 21|1@1+ (1,0) [0|0] "" Vector__XXX
 SG_ EPBR_a104_VEH_bodyControls3 m104 : 21|1@1+ (1,0) [0|0] "" Vector__XXX
 SG_ EPBR_a107_VEH_powerAvailable m107 : 21|1@1+ (1,0) [0|0] "" Vector__XXX
 SG_ EPBR_a108_PARTY_torque m108 : 21|1@1+ (1,0) [0|0] "" Vector__XXX
 SG_ EPBR_a109_VEH_imuOffsets m109 : 21|1@1+ (1,0) [0|0] "" Vector__XXX
 SG_ EPBR_a110_VEH_vehNm m110 : 21|1@1+ (1,0) [0|0] "" Vector__XXX
 SG_ EPBR_a111_RIPC_railStatus m111 : 21|1@1+ (1,0) [0|0] "" Vector__XXX
 SG_ EPBR_a112_LIPC_railStatus m112 : 21|1@1+ (1,0) [0|0] "" Vector__XXX
 SG_ EPBR_a113_VEH_peripheralPowerRequests m113 : 21|1@1+ (1,0) [0|0] "" Vector__XXX
 SG_ EPBR_a114_VEH_party3 m114 : 21|1@1+ (1,0) [0|0] "" Vector__XXX
 SG_ EPBR_a115_REM_authentication m115 : 21|1@1+ (1,0) [0|0] "" Vector__XXX
 SG_ EPBR_a116_VEH_hvacRequest m116 : 21|1@1+ (1,0) [0|0] "" Vector__XXX
 SG_ EPBR_a117_PARTY_epbmStatus m117 : 21|1@1+ (1,0) [0|0] "" Vector__XXX
 SG_ EPBR_a118_VEH_LVPowerState m118 : 21|1@1+ (1,0) [0|0] "" Vector__XXX
 SG_ EPBR_a119_PARTY_steerAngle m119 : 21|1@1+ (1,0) [0|0] "" Vector__XXX
 SG_ EPBR_a120_VEH_torque m120 : 21|1@1+ (1,0) [0|0] "" Vector__XXX
 SG_ EPBR_a183_espCdpStatus m183 : 21|2@1+ (1,0) [0|0] "" Vector__XXX
 SG_ EPBR_a210_driverIsLeavingSpeedClass m210 : 21|3@1+ (1,0) [0|0] "" Vector__XXX
 SG_ EPBR_a243_DIFtorqueActual m243 : 21|1@1+ (1,0) [0|0] "" Vector__XXX
 SG_ EPBR_a262_userConfirmedChargeCableNotAttached m262 : 21|1@1+ (1,0) [0|0] "" Vector__XXX
 SG_ EPBR_a264_inputVoltageTooLow m264 : 21|1@1+ (1,0) [0|0] "" Vector__XXX
 SG_ EPBR_a021_Task100msLate m21 : 22|1@1+ (1,0) [0|0] "" Vector__XXX
 SG_ EPBR_a086_VEH_systemStatus m86 : 22|1@1+ (1,0) [0|0] "" Vector__XXX
 SG_ EPBR_a087_PARTY_temperature m87 : 22|1@1+ (1,0) [0|0] "" Vector__XXX
 SG_ EPBR_a088_PARTY_temperature m88 : 22|1@1+ (1,0) [0|0] "" Vector__XXX
 SG_ EPBR_a089_CH_party1 m89 : 22|1@1+ (1,0) [0|0] "" Vector__XXX
 SG_ EPBR_a098_PARTY_status m98 : 22|1@1+ (1,0) [0|0] "" Vector__XXX
 SG_ EPBR_a104_BDY_bodyControls3 m104 : 22|1@1+ (1,0) [0|0] "" Vector__XXX
 SG_ EPBR_a107_PT_ptNm m107 : 22|1@1+ (1,0) [0|0] "" Vector__XXX
 SG_ EPBR_a108_PARTY_status m108 : 22|1@1+ (1,0) [0|0] "" Vector__XXX
 SG_ EPBR_a109_PARTY_inertial1 m109 : 22|1@1+ (1,0) [0|0] "" Vector__XXX
 SG_ EPBR_a110_VEH_mismatchFault m110 : 22|1@1+ (1,0) [0|0] "" Vector__XXX
 SG_ EPBR_a111_RIPC_remoteADC m111 : 22|1@1+ (1,0) [0|0] "" Vector__XXX
 SG_ EPBR_a112_LIPC_remoteADC m112 : 22|1@1+ (1,0) [0|0] "" Vector__XXX
 SG_ EPBR_a113_VEH_corianderVehicleControl m113 : 22|1@1+ (1,0) [0|0] "" Vector__XXX
 SG_ EPBR_a114_VEH_status m114 : 22|1@1+ (1,0) [0|0] "" Vector__XXX
 SG_ EPBR_a115_UI_corianderVehicleControl m115 : 22|1@1+ (1,0) [0|0] "" Vector__XXX
 SG_ EPBR_a116_VEH_hvacStatus m116 : 22|1@1+ (1,0) [0|0] "" Vector__XXX
 SG_ EPBR_a117_VEH_vehNm m117 : 22|1@1+ (1,0) [0|0] "" Vector__XXX
 SG_ EPBR_a118_VEH_coolant m118 : 22|1@1+ (1,0) [0|0] "" Vector__XXX
 SG_ EPBR_a120_PARTY_locStatus m120 : 22|1@1+ (1,0) [0|0] "" Vector__XXX
 SG_ EPBR_a243_vehicleSpeed m243 : 22|1@1+ (1,0) [0|0] "" Vector__XXX
 SG_ EPBR_a262_brakeNotConfirmedPressed m262 : 22|1@1+ (1,0) [0|0] "" Vector__XXX
 SG_ EPBR_a264_chargeCablePotentiallyAttached m264 : 22|1@1+ (1,0) [0|0] "" Vector__XXX
 SG_ EPBR_a021_Task100msStarved m21 : 23|1@1+ (1,0) [0|0] "" Vector__XXX
 SG_ EPBR_a086_VEH_thermalStatus m86 : 23|1@1+ (1,0) [0|0] "" Vector__XXX
 SG_ EPBR_a087_PARTY_thermalControl m87 : 23|1@1+ (1,0) [0|0] "" Vector__XXX
 SG_ EPBR_a088_PARTY_thermalControl m88 : 23|1@1+ (1,0) [0|0] "" Vector__XXX
 SG_ EPBR_a089_CH_party3 m89 : 23|1@1+ (1,0) [0|0] "" Vector__XXX
 SG_ EPBR_a098_PARTY_temperature m98 : 23|1@1+ (1,0) [0|0] "" Vector__XXX
 SG_ EPBR_a104_VEH_thermalStatus m104 : 23|1@1+ (1,0) [0|0] "" Vector__XXX
 SG_ EPBR_a107_PT_status m107 : 23|1@1+ (1,0) [0|0] "" Vector__XXX
 SG_ EPBR_a108_PARTY_temperature m108 : 23|1@1+ (1,0) [0|0] "" Vector__XXX
 SG_ EPBR_a109_BDY_imuOffsets m109 : 23|1@1+ (1,0) [0|0] "" Vector__XXX
 SG_ EPBR_a110_VEH_vin m110 : 23|1@1+ (1,0) [0|0] "" Vector__XXX
 SG_ EPBR_a111_RIPC_switchStatus m111 : 23|1@1+ (1,0) [0|0] "" Vector__XXX
 SG_ EPBR_a112_LIPC_switchStatus m112 : 23|1@1+ (1,0) [0|0] "" Vector__XXX
 SG_ EPBR_a113_VEH_solarData m113 : 23|1@1+ (1,0) [0|0] "" Vector__XXX
 SG_ EPBR_a114_PARTY_wheelRotation m114 : 23|1@1+ (1,0) [0|0] "" Vector__XXX
 SG_ EPBR_a115_CH_TPMSDisplay m115 : 23|1@1+ (1,0) [0|0] "" Vector__XXX
 SG_ EPBR_a116_VEH_LVPowerState m116 : 23|1@1+ (1,0) [0|0] "" Vector__XXX
 SG_ EPBR_a117_VEH_hvacBlowerFdb m117 : 23|1@1+ (1,0) [0|0] "" Vector__XXX
 SG_ EPBR_a118_VEH_vehicleStatus m118 : 23|1@1+ (1,0) [0|0] "" Vector__XXX
 SG_ EPBR_a120_PARTY_speed m120 : 23|1@1+ (1,0) [0|0] "" Vector__XXX
 SG_ EPBR_a181_vcTrailerDetected m181 : 23|1@1+ (1,0) [0|0] "" Vector__XXX
 SG_ EPBR_a243_tempAmbient m243 : 23|1@1+ (1,0) [0|0] "" Vector__XXX
 SG_ EPBR_a262_vcfrontMIA m262 : 23|1@1+ (1,0) [0|0] "" Vector__XXX
 SG_ EPBR_a264_userConfirmedChargeCableNotAttached m264 : 23|1@1+ (1,0) [0|0] "" Vector__XXX
 SG_ EPBR_a006_mailboxID m6 : 24|8@1+ (1,0) [0|0] "" Vector__XXX
 SG_ EPBR_a021_Task100msMissed m21 : 24|1@1+ (1,0) [0|0] "" Vector__XXX
 SG_ EPBR_a022_TaskInitError0 m22 : 24|8@1+ (1,0) [0|0] "" Vector__XXX
 SG_ EPBR_a031_uds_bytes_1 m31 : 24|8@1+ (1,0) [0|0] "" Vector__XXX
 SG_ EPBR_a041_CPULoad1msTask m41 : 24|8@1+ (1,0) [0|0] "" Vector__XXX
 SG_ EPBR_a042_Usage10msTask m42 : 24|8@1+ (1,0) [0|0] "" Vector__XXX
 SG_ EPBR_a063_switchType m63 : 24|8@1+ (1,0) [0|0] "" Vector__XXX
 SG_ EPBR_a086_VEH_vehNm m86 : 24|1@1+ (1,0) [0|0] "" Vector__XXX
 SG_ EPBR_a087_VEH_motorStatus m87 : 24|1@1+ (1,0) [0|0] "" Vector__XXX
 SG_ EPBR_a088_VEH_motorStatus m88 : 24|1@1+ (1,0) [0|0] "" Vector__XXX
 SG_ EPBR_a089_VEH_party1 m89 : 24|1@1+ (1,0) [0|0] "" Vector__XXX
 SG_ EPBR_a098_PARTY_thermalControl m98 : 24|1@1+ (1,0) [0|0] "" Vector__XXX
 SG_ EPBR_a104_CH_control m104 : 24|1@1+ (1,0) [0|0] "" Vector__XXX
 SG_ EPBR_a107_PT_thermalStatus m107 : 24|1@1+ (1,0) [0|0] "" Vector__XXX
 SG_ EPBR_a108_PARTY_thermalControl m108 : 24|1@1+ (1,0) [0|0] "" Vector__XXX
 SG_ EPBR_a109_BDY_inertial1 m109 : 24|1@1+ (1,0) [0|0] "" Vector__XXX
 SG_ EPBR_a110_VEH_bmpDebug m110 : 24|1@1+ (1,0) [0|0] "" Vector__XXX
 SG_ EPBR_a111_VEH_LVPowerState m111 : 24|1@1+ (1,0) [0|0] "" Vector__XXX
 SG_ EPBR_a112_VEH_LVPowerState m112 : 24|1@1+ (1,0) [0|0] "" Vector__XXX
 SG_ EPBR_a113_VEH_ventCntlReq m113 : 24|1@1+ (1,0) [0|0] "" Vector__XXX
 SG_ EPBR_a114_CH_wheelRotation m114 : 24|1@1+ (1,0) [0|0] "" Vector__XXX
 SG_ EPBR_a116_VEH_lightStatus m116 : 24|1@1+ (1,0) [0|0] "" Vector__XXX
 SG_ EPBR_a117_VEH_LVPowerState m117 : 24|1@1+ (1,0) [0|0] "" Vector__XXX
 SG_ EPBR_a118_VEH_12VBatteryStatus m118 : 24|1@1+ (1,0) [0|0] "" Vector__XXX
 SG_ EPBR_a120_VEH_speed m120 : 24|1@1+ (1,0) [0|0] "" Vector__XXX
 SG_ EPBR_a141_toState m141 : 24|5@1+ (1,0) [0|0] "" Vector__XXX
 SG_ EPBR_a173_esmStateRequest m173 : 24|5@1+ (1,0) [0|0] "" Vector__XXX
 SG_ EPBR_a174_esmStateRequest m174 : 24|5@1+ (1,0) [0|0] "" Vector__XXX
 SG_ EPBR_a175_esmStateRequest m175 : 24|5@1+ (1,0) [0|0] "" Vector__XXX
 SG_ EPBR_a176_esmStateRequest m176 : 24|5@1+ (1,0) [0|0] "" Vector__XXX
 SG_ EPBR_a177_esmStateRequest m177 : 24|5@1+ (1,0) [0|0] "" Vector__XXX
 SG_ EPBR_a179_esmStateRequest m179 : 24|5@1+ (1,0) [0|0] "" Vector__XXX
 SG_ EPBR_a180_previousState m180 : 24|5@1+ (1,0) [0|0] "" Vector__XXX
 SG_ EPBR_a181_uiTrailerDetected m181 : 24|1@1+ (1,0) [0|0] "" Vector__XXX
 SG_ EPBR_a182_grade m182 : 24|7@1- (1,0) [0|0] "" Vector__XXX
 SG_ EPBR_a183_esmState m183 : 24|5@1+ (1,0) [0|0] "" Vector__XXX
 SG_ EPBR_a184_previousState m184 : 24|5@1+ (1,0) [0|0] "" Vector__XXX
 SG_ EPBR_a186_previousState m186 : 24|5@1+ (1,0) [0|0] "" Vector__XXX
 SG_ EPBR_a187_previousState m187 : 24|5@1+ (1,0) [0|0] "" Vector__XXX
 SG_ EPBR_a188_previousState m188 : 24|5@1+ (1,0) [0|0] "" Vector__XXX
 SG_ EPBR_a189_previousState m189 : 24|5@1+ (1,0) [0|0] "" Vector__XXX
 SG_ EPBR_a190_esmStateRequest m190 : 24|5@1+ (1,0) [0|0] "" Vector__XXX
 SG_ EPBR_a191_esmStateRequest m191 : 24|5@1+ (1,0) [0|0] "" Vector__XXX
 SG_ EPBR_a210_localDriverIsLeaving m210 : 24|1@1+ (1,0) [0|0] "" Vector__XXX
 SG_ EPBR_a216_byte0 m216 : 24|8@1+ (1,0) [0|0] "" Vector__XXX
 SG_ EPBR_a217_byte5 m217 : 24|8@1+ (1,0) [0|0] "" Vector__XXX
 SG_ EPBR_a225_previousState m225 : 24|5@1+ (1,0) [0|0] "" Vector__XXX
 SG_ EPBR_a241_vehiclePowerState m241 : 24|2@1+ (1,0) [0|0] "" Vector__XXX
 SG_ EPBR_a242_vehiclePowerState m242 : 24|2@1+ (1,0) [0|0] "" Vector__XXX
 SG_ EPBR_a243_thermistorTMin m243 : 24|1@1+ (1,0) [0|0] "" Vector__XXX
 SG_ EPBR_a246_nextState m246 : 24|5@1+ (1,0) [0|0] "" Vector__XXX
 SG_ EPBR_a247_esmStateRequest m247 : 24|5@1+ (1,0) [0|0] "" Vector__XXX
 SG_ EPBR_a248_esmStateRequest m248 : 24|5@1+ (1,0) [0|0] "" Vector__XXX
 SG_ EPBR_a249_nextState m249 : 24|5@1+ (1,0) [0|0] "" Vector__XXX
 SG_ EPBR_a250_esmOperationTrigger m250 : 24|6@1+ (1,0) [0|0] "" Vector__XXX
 SG_ EPBR_a253_esmStateRequest m253 : 24|5@1+ (1,0) [0|0] "" Vector__XXX
 SG_ EPBR_a256_esmStateRequest m256 : 24|5@1+ (1,0) [0|0] "" Vector__XXX
 SG_ EPBR_a262_showroomModeActive m262 : 24|1@1+ (1,0) [0|0] "" Vector__XXX
 SG_ EPBR_a263_esmStateRequest m263 : 24|5@1+ (1,0) [0|0] "" Vector__XXX
 SG_ EPBR_a264_chargeCableDefinitelyAttached m264 : 24|1@1+ (1,0) [0|0] "" Vector__XXX
 SG_ EPBR_a300_subUsageId m300 : 24|8@1+ (1,0) [0|0] "" Vector__XXX
 SG_ EPBR_a357_grade m357 : 24|7@1- (1,0) [0|0] "" Vector__XXX
 SG_ EPBR_a358_grade m358 : 24|7@1- (1,0) [0|0] "" Vector__XXX
 SG_ EPBR_a365_grade m365 : 24|7@1- (1,0) [0|0] "" Vector__XXX
 SG_ EPBR_a366_grade m366 : 24|7@1- (1,0) [0|0] "" Vector__XXX
 SG_ EPBR_a021_Task1000msLate m21 : 25|1@1+ (1,0) [0|0] "" Vector__XXX
 SG_ EPBR_a089_VEH_party3 m89 : 25|1@1+ (1,0) [0|0] "" Vector__XXX
 SG_ EPBR_a098_PARTY_torque m98 : 25|1@1+ (1,0) [0|0] "" Vector__XXX
 SG_ EPBR_a104_PARTY_control m104 : 25|1@1+ (1,0) [0|0] "" Vector__XXX
 SG_ EPBR_a107_PT_socStatus m107 : 25|1@1+ (1,0) [0|0] "" Vector__XXX
 SG_ EPBR_a108_PT_temperature m108 : 25|1@1+ (1,0) [0|0] "" Vector__XXX
 SG_ EPBR_a109_BDY_inertial2 m109 : 25|1@1+ (1,0) [0|0] "" Vector__XXX
 SG_ EPBR_a110_VEH_gearControl m110 : 25|1@1+ (1,0) [0|0] "" Vector__XXX
 SG_ EPBR_a111_VEH_seatStatus m111 : 25|1@1+ (1,0) [0|0] "" Vector__XXX
 SG_ EPBR_a112_PARTY_status m112 : 25|1@1+ (1,0) [0|0] "" Vector__XXX
 SG_ EPBR_a113_VEH_chassisControl m113 : 25|1@1+ (1,0) [0|0] "" Vector__XXX
 SG_ EPBR_a114_VEH_wheelRotation m114 : 25|1@1+ (1,0) [0|0] "" Vector__XXX
 SG_ EPBR_a116_VEH_seatStatus m116 : 25|1@1+ (1,0) [0|0] "" Vector__XXX
 SG_ EPBR_a117_VEH_restraintStatus m117 : 25|1@1+ (1,0) [0|0] "" Vector__XXX
 SG_ EPBR_a118_VEH_systemStatus m118 : 25|1@1+ (1,0) [0|0] "" Vector__XXX
 SG_ EPBR_a120_PARTY_status m120 : 25|1@1+ (1,0) [0|0] "" Vector__XXX
 SG_ EPBR_a181_trailerDetected m181 : 25|1@1+ (1,0) [0|0] "" Vector__XXX
 SG_ EPBR_a198_currentAvg m198 : 25|12@1+ (0.01,0) [0|0] "" Vector__XXX
 SG_ EPBR_a210_localDriverIsLeavingAnySpeed m210 : 25|1@1+ (1,0) [0|0] "" Vector__XXX
 SG_ EPBR_a243_wiperSpeed m243 : 25|1@1+ (1,0) [0|0] "" Vector__XXX
 SG_ EPBR_a262_lvBatteryBlocking m262 : 25|1@1+ (1,0) [0|0] "" Vector__XXX
 SG_ EPBR_a264_lvBatteryBlocking m264 : 25|1@1+ (1,0) [0|0] "" Vector__XXX
 SG_ EPBR_a021_Task1000msStarved m21 : 26|1@1+ (1,0) [0|0] "" Vector__XXX
 SG_ EPBR_a098_PT_thermalControl m98 : 26|1@1+ (1,0) [0|0] "" Vector__XXX
 SG_ EPBR_a104_PARTY_bodyControls m104 : 26|1@1+ (1,0) [0|0] "" Vector__XXX
 SG_ EPBR_a107_VEH_socStatus m107 : 26|1@1+ (1,0) [0|0] "" Vector__XXX
 SG_ EPBR_a108_PT_thermalControl m108 : 26|1@1+ (1,0) [0|0] "" Vector__XXX
 SG_ EPBR_a109_BDY_status m109 : 26|1@1+ (1,0) [0|0] "" Vector__XXX
 SG_ EPBR_a110_VEH_canLogAvailability m110 : 26|1@1+ (1,0) [0|0] "" Vector__XXX
 SG_ EPBR_a111_PARTY_status m111 : 26|1@1+ (1,0) [0|0] "" Vector__XXX
 SG_ EPBR_a112_CH_status m112 : 26|1@1+ (1,0) [0|0] "" Vector__XXX
 SG_ EPBR_a113_VEH_trackModeSettings m113 : 26|1@1+ (1,0) [0|0] "" Vector__XXX
 SG_ EPBR_a114_PARTY_brakeTorque m114 : 26|1@1+ (1,0) [0|0] "" Vector__XXX
 SG_ EPBR_a116_VEH_thsStatus m116 : 26|1@1+ (1,0) [0|0] "" Vector__XXX
 SG_ EPBR_a117_VEH_lightStatus m117 : 26|1@1+ (1,0) [0|0] "" Vector__XXX
 SG_ EPBR_a118_PARTY_LVPowerState m118 : 26|1@1+ (1,0) [0|0] "" Vector__XXX
 SG_ EPBR_a120_PT_speed m120 : 26|1@1+ (1,0) [0|0] "" Vector__XXX
 SG_ EPBR_a210_remoteDriverIsLeaving m210 : 26|1@1+ (1,0) [0|0] "" Vector__XXX
 SG_ EPBR_a241_highCurrent m241 : 26|1@1+ (1,0) [0|0] "" Vector__XXX
 SG_ EPBR_a242_highCurrent m242 : 26|1@1+ (1,0) [0|0] "" Vector__XXX
 SG_ EPBR_a243_vehiclePowerState m243 : 26|1@1+ (1,0) [0|0] "" Vector__XXX
 SG_ EPBR_a262_chargeCableStateUnknown m262 : 26|1@1+ (1,0) [0|0] "" Vector__XXX
 SG_ EPBR_a264_vehicleSpeedTooFast m264 : 26|1@1+ (1,0) [0|0] "" Vector__XXX
 SG_ EPBR_a352_maxCurrent m352 : 26|8@1+ (0.1,0) [0|0] "" Vector__XXX
 SG_ EPBR_a021_Task1000msMissed m21 : 27|1@1+ (1,0) [0|0] "" Vector__XXX
 SG_ EPBR_a098_PT_temperature m98 : 27|1@1+ (1,0) [0|0] "" Vector__XXX
 SG_ EPBR_a104_PARTY_gpsAccuracies m104 : 27|1@1+ (1,0) [0|0] "" Vector__XXX
 SG_ EPBR_a107_VEH_packConfig m107 : 27|1@1+ (1,0) [0|0] "" Vector__XXX
 SG_ EPBR_a108_PARTY_motorStatus m108 : 27|1@1+ (1,0) [0|0] "" Vector__XXX
 SG_ EPBR_a109_VEH_inertial1 m109 : 27|1@1+ (1,0) [0|0] "" Vector__XXX
 SG_ EPBR_a110_CH_airbagCutoffStatus m110 : 27|1@1+ (1,0) [0|0] "" Vector__XXX
 SG_ EPBR_a111_CH_status m111 : 27|1@1+ (1,0) [0|0] "" Vector__XXX
 SG_ EPBR_a113_VEH_powertrainControl m113 : 27|1@1+ (1,0) [0|0] "" Vector__XXX
 SG_ EPBR_a114_PARTY_offsets m114 : 27|1@1+ (1,0) [0|0] "" Vector__XXX
 SG_ EPBR_a116_VEH_doorStatus m116 : 27|1@1+ (1,0) [0|0] "" Vector__XXX
 SG_ EPBR_a117_VEH_seatStatus m117 : 27|1@1+ (1,0) [0|0] "" Vector__XXX
 SG_ EPBR_a118_PARTY_outputPowerStatus m118 : 27|1@1+ (1,0) [0|0] "" Vector__XXX
 SG_ EPBR_a120_PT_systemStatus m120 : 27|1@1+ (1,0) [0|0] "" Vector__XXX
 SG_ EPBR_a210_remoteDriverIsLeavingAnySpeed m210 : 27|1@1+ (1,0) [0|0] "" Vector__XXX
 SG_ EPBR_a241_monitorDataGood m241 : 27|1@1+ (1,0) [0|0] "" Vector__XXX
 SG_ EPBR_a242_monitorDataGood m242 : 27|1@1+ (1,0) [0|0] "" Vector__XXX
 SG_ EPBR_a243_brakeDiscWipingActive m243 : 27|1@1+ (1,0) [0|0] "" Vector__XXX
 SG_ EPBR_a262_lvBatteryCanSupportVehicle m262 : 27|1@1+ (1,0) [0|0] "" Vector__XXX
 SG_ EPBR_a264_vehicleSpeedUnknown m264 : 27|1@1+ (1,0) [0|0] "" Vector__XXX
 SG_ EPBR_a058_current m58 : 28|11@1+ (0.1,0) [0|0] "" Vector__XXX
 SG_ EPBR_a059_resistanceEstimate m59 : 28|12@1+ (0.00244,0) [0|0] "" Vector__XXX
 SG_ EPBR_a098_PARTY_motorStatus m98 : 28|1@1+ (1,0) [0|0] "" Vector__XXX
 SG_ EPBR_a104_CH_status m104 : 28|1@1+ (1,0) [0|0] "" Vector__XXX
 SG_ EPBR_a107_VEH_energyStatus m107 : 28|1@1+ (1,0) [0|0] "" Vector__XXX
 SG_ EPBR_a108_VEH_motorStatus m108 : 28|1@1+ (1,0) [0|0] "" Vector__XXX
 SG_ EPBR_a109_VEH_inertial2 m109 : 28|1@1+ (1,0) [0|0] "" Vector__XXX
 SG_ EPBR_a110_CH_carConfig m110 : 28|1@1+ (1,0) [0|0] "" Vector__XXX
 SG_ EPBR_a113_VEH_vehicleModes m113 : 28|1@1+ (1,0) [0|0] "" Vector__XXX
 SG_ EPBR_a114_BDY_offsets m114 : 28|1@1+ (1,0) [0|0] "" Vector__XXX
 SG_ EPBR_a116_VEH_seatHeatStatus m116 : 28|1@1+ (1,0) [0|0] "" Vector__XXX
 SG_ EPBR_a117_BDY_falconSwitchStatus m117 : 28|1@1+ (1,0) [0|0] "" Vector__XXX
 SG_ EPBR_a118_PARTY_vehicleTime m118 : 28|1@1+ (1,0) [0|0] "" Vector__XXX
 SG_ EPBR_a120_PARTY_vehicleEstimates m120 : 28|1@1+ (1,0) [0|0] "" Vector__XXX
 SG_ EPBR_a125_nvFilt m125 : 28|12@1+ (0.005443676098,0) [0|0] "" Vector__XXX
 SG_ EPBR_a126_nvFilt m126 : 28|12@1+ (0.005443676098,0) [0|0] "" Vector__XXX
 SG_ EPBR_a127_nvFilt m127 : 28|12@1+ (0.005443676098,0) [0|0] "" Vector__XXX
 SG_ EPBR_a128_nvFilt m128 : 28|12@1+ (0.005443676098,0) [0|0] "" Vector__XXX
 SG_ EPBR_a134_nvFilt m134 : 28|12@1+ (0.005443676098,0) [0|0] "" Vector__XXX
 SG_ EPBR_a135_nvFilt m135 : 28|12@1+ (0.005443676098,0) [0|0] "" Vector__XXX
 SG_ EPBR_a136_nvFilt m136 : 28|12@1+ (0.005443676098,0) [0|0] "" Vector__XXX
 SG_ EPBR_a137_nvFilt m137 : 28|12@1+ (0.005443676098,0) [0|0] "" Vector__XXX
 SG_ EPBR_a170_nvFilt m170 : 28|12@1+ (0.005443676098,0) [0|0] "" Vector__XXX
 SG_ EPBR_a171_nvFilt m171 : 28|12@1+ (0.005443676098,0) [0|0] "" Vector__XXX
 SG_ EPBR_a210_primaryDriverDoorClosed m210 : 28|2@1+ (1,0) [0|0] "" Vector__XXX
 SG_ EPBR_a241_hasLockoutRequest m241 : 28|1@1+ (1,0) [0|0] "" Vector__XXX
 SG_ EPBR_a242_hasLockoutRequest m242 : 28|1@1+ (1,0) [0|0] "" Vector__XXX
 SG_ EPBR_a262_ignoreLvBatteryCanSupportVehicle m262 : 28|1@1+ (1,0) [0|0] "" Vector__XXX
 SG_ EPBR_a264_jumpPostConfirmedTripped m264 : 28|1@1+ (1,0) [0|0] "" Vector__XXX
 SG_ EPBR_a362_outputRodDriver m362 : 28|10@1+ (0.1,-10) [0|0] "" Vector__XXX
 SG_ EPBR_a363_outputRodDriver m363 : 28|10@1+ (0.1,-10) [0|0] "" Vector__XXX
 SG_ EPBR_a098_VEH_motorStatus m98 : 29|1@1+ (1,0) [0|0] "" Vector__XXX
 SG_ EPBR_a104_PARTY_status m104 : 29|1@1+ (1,0) [0|0] "" Vector__XXX
 SG_ EPBR_a107_VEH_chargeInfo m107 : 29|1@1+ (1,0) [0|0] "" Vector__XXX
 SG_ EPBR_a108_CH_torque m108 : 29|1@1+ (1,0) [0|0] "" Vector__XXX
 SG_ EPBR_a109_CH_inertial1 m109 : 29|1@1+ (1,0) [0|0] "" Vector__XXX
 SG_ EPBR_a110_CH_carState m110 : 29|1@1+ (1,0) [0|0] "" Vector__XXX
 SG_ EPBR_a113_VEH_driverProfileRecall m113 : 29|1@1+ (1,0) [0|0] "" Vector__XXX
 SG_ EPBR_a114_BDY_party3 m114 : 29|1@1+ (1,0) [0|0] "" Vector__XXX
 SG_ EPBR_a116_VEH_restraintStatus m116 : 29|1@1+ (1,0) [0|0] "" Vector__XXX
 SG_ EPBR_a117_VEH_doorStatus m117 : 29|1@1+ (1,0) [0|0] "" Vector__XXX
 SG_ EPBR_a118_VEH_thermalCommand m118 : 29|1@1+ (1,0) [0|0] "" Vector__XXX
 SG_ EPBR_a120_VEH_aggregatedAxleSpeed m120 : 29|1@1+ (1,0) [0|0] "" Vector__XXX
 SG_ EPBR_a174_faultStatus m174 : 29|2@1+ (1,0) [0|0] "" Vector__XXX
 SG_ EPBR_a175_faultStatus m175 : 29|2@1+ (1,0) [0|0] "" Vector__XXX
 SG_ EPBR_a176_faultStatus m176 : 29|2@1+ (1,0) [0|0] "" Vector__XXX
 SG_ EPBR_a177_faultStatus m177 : 29|2@1+ (1,0) [0|0] "" Vector__XXX
 SG_ EPBR_a179_faultStatus m179 : 29|2@1+ (1,0) [0|0] "" Vector__XXX
 SG_ EPBR_a190_faultStatus m190 : 29|2@1+ (1,0) [0|0] "" Vector__XXX
 SG_ EPBR_a191_faultStatus m191 : 29|2@1+ (1,0) [0|0] "" Vector__XXX
 SG_ EPBR_a247_faultStatus m247 : 29|2@1+ (1,0) [0|0] "" Vector__XXX
 SG_ EPBR_a248_faultStatus m248 : 29|2@1+ (1,0) [0|0] "" Vector__XXX
 SG_ EPBR_a253_lvStatusReadyforDrive m253 : 29|2@1+ (1,0) [0|0] "" Vector__XXX
 SG_ EPBR_a256_lvStatusReadyforDrive m256 : 29|2@1+ (1,0) [0|0] "" Vector__XXX
 SG_ EPBR_a262_uiServiceMode m262 : 29|1@1+ (1,0) [0|0] "" Vector__XXX
 SG_ EPBR_a263_esmSpeedClass m263 : 29|3@1+ (1,0) [0|0] "" Vector__XXX
 SG_ EPBR_a264_vehiclePowerStateDrive m264 : 29|1@1+ (1,0) [0|0] "" Vector__XXX
 SG_ EPBR_a104_PARTY_steeringControl m104 : 30|1@1+ (1,0) [0|0] "" Vector__XXX
 SG_ EPBR_a109_CH_inertial2 m109 : 30|1@1+ (1,0) [0|0] "" Vector__XXX
 SG_ EPBR_a110_CH_vin m110 : 30|1@1+ (1,0) [0|0] "" Vector__XXX
 SG_ EPBR_a113_VEH_driverProfileRecall2 m113 : 30|1@1+ (1,0) [0|0] "" Vector__XXX
 SG_ EPBR_a114_BDY_status m114 : 30|1@1+ (1,0) [0|0] "" Vector__XXX
 SG_ EPBR_a116_VEH_switchStatus m116 : 30|1@1+ (1,0) [0|0] "" Vector__XXX
 SG_ EPBR_a117_VEH_doorStatus2 m117 : 30|1@1+ (1,0) [0|0] "" Vector__XXX
 SG_ EPBR_a118_CH_LVPowerState m118 : 30|1@1+ (1,0) [0|0] "" Vector__XXX
 SG_ EPBR_a120_PARTY_aggregatedAxleSpeed m120 : 30|1@1+ (1,0) [0|0] "" Vector__XXX
 SG_ EPBR_a210_secondaryDriverDoorClosed m210 : 30|2@1+ (1,0) [0|0] "" Vector__XXX
 SG_ EPBR_a250_isJumpPostTripped m250 : 30|1@1+ (1,0) [0|0] "" Vector__XXX
 SG_ EPBR_a262_uiServiceModePlus m262 : 30|1@1+ (1,0) [0|0] "" Vector__XXX
 SG_ EPBR_a264_diDriveMode m264 : 30|1@1+ (1,0) [0|0] "" Vector__XXX
 SG_ EPBR_a104_CH_steeringControl m104 : 31|1@1+ (1,0) [0|0] "" Vector__XXX
 SG_ EPBR_a109_CH_status m109 : 31|1@1+ (1,0) [0|0] "" Vector__XXX
 SG_ EPBR_a110_CH_chNm m110 : 31|1@1+ (1,0) [0|0] "" Vector__XXX
 SG_ EPBR_a113_VEH_ventCntlReg m113 : 31|1@1+ (1,0) [0|0] "" Vector__XXX
 SG_ EPBR_a114_BDY_wheelRotation m114 : 31|1@1+ (1,0) [0|0] "" Vector__XXX
 SG_ EPBR_a116_VEH_logging1Hz m116 : 31|1@1+ (1,0) [0|0] "" Vector__XXX
 SG_ EPBR_a117_VEH_windowStatus m117 : 31|1@1+ (1,0) [0|0] "" Vector__XXX
 SG_ EPBR_a118_PARTY_sensors m118 : 31|1@1+ (1,0) [0|0] "" Vector__XXX
 SG_ EPBR_a120_VEH_systemPower m120 : 31|1@1+ (1,0) [0|0] "" Vector__XXX
 SG_ EPBR_a253_passiveApplyRequested m253 : 31|1@1+ (1,0) [0|0] "" Vector__XXX
 SG_ EPBR_a256_vehiclePowerState m256 : 31|1@1+ (1,0) [0|0] "" Vector__XXX
 SG_ EPBR_a262_hvUp m262 : 31|1@1+ (1,0) [0|0] "" Vector__XXX
 SG_ EPBR_a264_chargeCableStateUnknown m264 : 31|1@1+ (1,0) [0|0] "" Vector__XXX
 SG_ EPBR_a000_alertDataW1 m0 : 32|16@1+ (1,0) [0|0] "" Vector__XXX
 SG_ EPBR_a003_LineNumber m3 : 32|16@1+ (1,0) [0|0] "" Vector__XXX
 SG_ EPBR_a005_busID1 m5 : 32|4@1+ (1,0) [0|0] "" Vector__XXX
 SG_ EPBR_a006_messageID m6 : 32|29@1+ (1,0) [0|0] "" Vector__XXX
 SG_ EPBR_a016_NVMMRecordNotFound m16 : 32|1@1+ (1,0) [0|0] "" Vector__XXX
 SG_ EPBR_a022_TaskInitError1 m22 : 32|8@1+ (1,0) [0|0] "" Vector__XXX
 SG_ EPBR_a031_uds_bytes_2 m31 : 32|8@1+ (1,0) [0|0] "" Vector__XXX
 SG_ EPBR_a041_CPULoad10msTask m41 : 32|8@1+ (1,0) [0|0] "" Vector__XXX
 SG_ EPBR_a042_Usage100msTask m42 : 32|8@1+ (1,0) [0|0] "" Vector__XXX
 SG_ EPBR_a063_ADCVoltage m63 : 32|8@1+ (0.025,0) [0|0] "" Vector__XXX
 SG_ EPBR_a104_VEH_steeringControl m104 : 32|1@1+ (1,0) [0|0] "" Vector__XXX
 SG_ EPBR_a110_CH_epochTimeGtw m110 : 32|1@1+ (1,0) [0|0] "" Vector__XXX
 SG_ EPBR_a113_VEH_debugECU m113 : 32|1@1+ (1,0) [0|0] "" Vector__XXX
 SG_ EPBR_a114_BDY_wheelSpeeds m114 : 32|1@1+ (1,0) [0|0] "" Vector__XXX
 SG_ EPBR_a116_VEH_seatStatus2 m116 : 32|1@1+ (1,0) [0|0] "" Vector__XXX
 SG_ EPBR_a117_VEH_switchStatus m117 : 32|1@1+ (1,0) [0|0] "" Vector__XXX
 SG_ EPBR_a118_CH_sensors m118 : 32|1@1+ (1,0) [0|0] "" Vector__XXX
 SG_ EPBR_a120_PARTY_autonomyHealth m120 : 32|1@1+ (1,0) [0|0] "" Vector__XXX
 SG_ EPBR_a173_csmState m173 : 32|4@1+ (1,0) [0|0] "" Vector__XXX
 SG_ EPBR_a174_monitorUnitStatus m174 : 32|5@1+ (1,0) [0|0] "" Vector__XXX
 SG_ EPBR_a175_monitorUnitStatus m175 : 32|5@1+ (1,0) [0|0] "" Vector__XXX
 SG_ EPBR_a176_monitorUnitStatus m176 : 32|5@1+ (1,0) [0|0] "" Vector__XXX
 SG_ EPBR_a177_monitorUnitStatus m177 : 32|5@1+ (1,0) [0|0] "" Vector__XXX
 SG_ EPBR_a179_monitorUnitStatus m179 : 32|5@1+ (1,0) [0|0] "" Vector__XXX
 SG_ EPBR_a180_nextState m180 : 32|5@1+ (1,0) [0|0] "" Vector__XXX
 SG_ EPBR_a182_temperature m182 : 32|8@1+ (0.5,-40) [0|0] "" Vector__XXX
 SG_ EPBR_a183_esmStateRequest m183 : 32|5@1+ (1,0) [0|0] "" Vector__XXX
 SG_ EPBR_a184_nextState m184 : 32|5@1+ (1,0) [0|0] "" Vector__XXX
 SG_ EPBR_a186_nextState m186 : 32|5@1+ (1,0) [0|0] "" Vector__XXX
 SG_ EPBR_a187_nextState m187 : 32|5@1+ (1,0) [0|0] "" Vector__XXX
 SG_ EPBR_a188_nextState m188 : 32|5@1+ (1,0) [0|0] "" Vector__XXX
 SG_ EPBR_a189_nextState m189 : 32|5@1+ (1,0) [0|0] "" Vector__XXX
 SG_ EPBR_a190_monitorUnitStatus m190 : 32|5@1+ (1,0) [0|0] "" Vector__XXX
 SG_ EPBR_a191_monitorUnitStatus m191 : 32|5@1+ (1,0) [0|0] "" Vector__XXX
 SG_ EPBR_a210_driverBuckled m210 : 32|2@1+ (1,0) [0|0] "" Vector__XXX
 SG_ EPBR_a216_byte1 m216 : 32|8@1+ (1,0) [0|0] "" Vector__XXX
 SG_ EPBR_a217_byte6 m217 : 32|8@1+ (1,0) [0|0] "" Vector__XXX
 SG_ EPBR_a225_nextState m225 : 32|5@1+ (1,0) [0|0] "" Vector__XXX
 SG_ EPBR_a246_esmStateRequest m246 : 32|5@1+ (1,0) [0|0] "" Vector__XXX
 SG_ EPBR_a247_monitorUnitStatus m247 : 32|5@1+ (1,0) [0|0] "" Vector__XXX
 SG_ EPBR_a248_monitorUnitStatus m248 : 32|5@1+ (1,0) [0|0] "" Vector__XXX
 SG_ EPBR_a249_esmStateRequest m249 : 32|5@1+ (1,0) [0|0] "" Vector__XXX
 SG_ EPBR_a251_pistonPosition m251 : 32|13@1- (9.768009768009769,0) [0|0] "" Vector__XXX
 SG_ EPBR_a253_diStandStillApply m253 : 32|1@1+ (1,0) [0|0] "" Vector__XXX
 SG_ EPBR_a256_passiveApplyRequested m256 : 32|1@1+ (1,0) [0|0] "" Vector__XXX
 SG_ EPBR_a262_wasHVUpSinceLastWake m262 : 32|1@1+ (1,0) [0|0] "" Vector__XXX
 SG_ EPBR_a263_isPowerStateParkRequested m263 : 32|1@1+ (1,0) [0|0] "" Vector__XXX
 SG_ EPBR_a264_lvBatteryCanSupportVehicle m264 : 32|1@1+ (1,0) [0|0] "" Vector__XXX
 SG_ EPBR_a301_oocConfidence m301 : 32|12@1+ (1,0) [0|0] "" Vector__XXX
 SG_ EPBR_a302_deltaCurrent m302 : 32|15@1+ (0.01,0) [0|0] "" Vector__XXX
 SG_ EPBR_a303_pistonPosition m303 : 32|13@1- (9.768009768009769,0) [0|0] "" Vector__XXX
 SG_ EPBR_a350_ensDuty m350 : 32|10@1+ (0.00098,0) [0|0] "" Vector__XXX
 SG_ EPBR_a357_ambientTemp m357 : 32|8@1+ (0.5,-40) [0|0] "" Vector__XXX
 SG_ EPBR_a358_ambientTemp m358 : 32|8@1+ (0.5,-40) [0|0] "" Vector__XXX
 SG_ EPBR_a365_ambientTemp m365 : 32|8@1+ (0.5,-40) [0|0] "" Vector__XXX
 SG_ EPBR_a366_ambientTemp m366 : 32|8@1+ (0.5,-40) [0|0] "" Vector__XXX
 SG_ EPBR_a370_count m370 : 32|16@1+ (1,0) [0|0] "" Vector__XXX
 SG_ EPBR_a016_NVMMCRCMismatch m16 : 33|1@1+ (1,0) [0|0] "" Vector__XXX
 SG_ EPBR_a104_PARTY_integratedSafetyFront m104 : 33|1@1+ (1,0) [0|0] "" Vector__XXX
 SG_ EPBR_a110_PARTY_carConfig m110 : 33|1@1+ (1,0) [0|0] "" Vector__XXX
 SG_ EPBR_a113_VEH_status m113 : 33|1@1+ (1,0) [0|0] "" Vector__XXX
 SG_ EPBR_a114_CH_party1 m114 : 33|1@1+ (1,0) [0|0] "" Vector__XXX
 SG_ EPBR_a116_VEH_status m116 : 33|1@1+ (1,0) [0|0] "" Vector__XXX
 SG_ EPBR_a117_VEH_intrusionSensorStatus m117 : 33|1@1+ (1,0) [0|0] "" Vector__XXX
 SG_ EPBR_a118_VEH_interNodeResistance m118 : 33|1@1+ (1,0) [0|0] "" Vector__XXX
 SG_ EPBR_a120_VEH_autonomyHealth m120 : 33|1@1+ (1,0) [0|0] "" Vector__XXX
 SG_ EPBR_a253_isDriverLeaving m253 : 33|1@1+ (1,0) [0|0] "" Vector__XXX
 SG_ EPBR_a256_diStandStillApply m256 : 33|1@1+ (1,0) [0|0] "" Vector__XXX
 SG_ EPBR_a262_hvDownForMoreThanTwoMinutes m262 : 33|1@1+ (1,0) [0|0] "" Vector__XXX
 SG_ EPBR_a263_isJumpPostTripped m263 : 33|1@1+ (1,0) [0|0] "" Vector__XXX
 SG_ EPBR_a264_ignoreLvBatteryCanSupportVehicle m264 : 33|1@1+ (1,0) [0|0] "" Vector__XXX
 SG_ EPBR_a016_NVMMVersionMismatch m16 : 34|1@1+ (1,0) [0|0] "" Vector__XXX
 SG_ EPBR_a104_PARTY_matrixBendAngleRequest m104 : 34|1@1+ (1,0) [0|0] "" Vector__XXX
 SG_ EPBR_a113_VEH_elevationStatus m113 : 34|1@1+ (1,0) [0|0] "" Vector__XXX
 SG_ EPBR_a114_CH_party3 m114 : 34|1@1+ (1,0) [0|0] "" Vector__XXX
 SG_ EPBR_a116_VEH_thermalCommand m116 : 34|1@1+ (1,0) [0|0] "" Vector__XXX
 SG_ EPBR_a117_VEH_liftgateStatus m117 : 34|1@1+ (1,0) [0|0] "" Vector__XXX
 SG_ EPBR_a118_CH_lighting m118 : 34|1@1+ (1,0) [0|0] "" Vector__XXX
 SG_ EPBR_a120_PT_systemPower m120 : 34|1@1+ (1,0) [0|0] "" Vector__XXX
 SG_ EPBR_a210_driverSeated m210 : 34|2@1+ (1,0) [0|0] "" Vector__XXX
 SG_ EPBR_a253_driverParkRequest m253 : 34|1@1+ (1,0) [0|0] "" Vector__XXX
 SG_ EPBR_a256_activeDecelRequest m256 : 34|1@1+ (1,0) [0|0] "" Vector__XXX
 SG_ EPBR_a262_dirLVOn m262 : 34|1@1+ (1,0) [0|0] "" Vector__XXX
 SG_ EPBR_a264_hvDownForMoreThanTwoMinutes m264 : 34|1@1+ (1,0) [0|0] "" Vector__XXX
 SG_ EPBR_a352_prevFilteredCurrent m352 : 34|8@1+ (0.1,0) [0|0] "" Vector__XXX
 SG_ EPBR_a016_NVMMRecordUpgraded m16 : 35|1@1+ (1,0) [0|0] "" Vector__XXX
 SG_ EPBR_a104_VEH_matrixHighBeamRequest m104 : 35|1@1+ (1,0) [0|0] "" Vector__XXX
 SG_ EPBR_a113_VEH_LVControl m113 : 35|1@1+ (1,0) [0|0] "" Vector__XXX
 SG_ EPBR_a114_CH_status m114 : 35|1@1+ (1,0) [0|0] "" Vector__XXX
 SG_ EPBR_a116_VEH_windowStatus m116 : 35|1@1+ (1,0) [0|0] "" Vector__XXX
 SG_ EPBR_a117_VEH_seatStatus2 m117 : 35|1@1+ (1,0) [0|0] "" Vector__XXX
 SG_ EPBR_a118_VEH_lightStatus m118 : 35|1@1+ (1,0) [0|0] "" Vector__XXX
 SG_ EPBR_a120_PARTY_stalklessInterfaces m120 : 35|1@1+ (1,0) [0|0] "" Vector__XXX
 SG_ EPBR_a253_driverDynamicRequest m253 : 35|1@1+ (1,0) [0|0] "" Vector__XXX
 SG_ EPBR_a256_lvDriveStatusBlock m256 : 35|1@1+ (1,0) [0|0] "" Vector__XXX
 SG_ EPBR_a264_uiServiceMode m264 : 35|1@1+ (1,0) [0|0] "" Vector__XXX
 SG_ EPBR_a005_faults1 m5 : 36|12@1+ (1,0) [0|0] "" Vector__XXX
 SG_ EPBR_a016_NVMMMemOverflow m16 : 36|1@1+ (1,0) [0|0] "" Vector__XXX
 SG_ EPBR_a104_VEH_summonCommand m104 : 36|1@1+ (1,0) [0|0] "" Vector__XXX
 SG_ EPBR_a113_CH_chassisControl m113 : 36|1@1+ (1,0) [0|0] "" Vector__XXX
 SG_ EPBR_a116_PARTY_restraintStatus m116 : 36|1@1+ (1,0) [0|0] "" Vector__XXX
 SG_ EPBR_a117_PARTY_restraintStatus m117 : 36|1@1+ (1,0) [0|0] "" Vector__XXX
 SG_ EPBR_a118_PARTY_vehNm m118 : 36|1@1+ (1,0) [0|0] "" Vector__XXX
 SG_ EPBR_a120_CH_speed m120 : 36|1@1+ (1,0) [0|0] "" Vector__XXX
 SG_ EPBR_a253_summonState m253 : 36|3@1+ (1,0) [0|0] "" Vector__XXX
 SG_ EPBR_a256_steeringDriveStatusBlock m256 : 36|1@1+ (1,0) [0|0] "" Vector__XXX
 SG_ EPBR_a264_uiServiceModePlus m264 : 36|1@1+ (1,0) [0|0] "" Vector__XXX
 SG_ EPBR_a016_NVMMWriteFailed m16 : 37|1@1+ (1,0) [0|0] "" Vector__XXX
 SG_ EPBR_a104_VEH_status m104 : 37|1@1+ (1,0) [0|0] "" Vector__XXX
 SG_ EPBR_a113_CH_powertrainControl m113 : 37|1@1+ (1,0) [0|0] "" Vector__XXX
 SG_ EPBR_a116_PARTY_doorStatus m116 : 37|1@1+ (1,0) [0|0] "" Vector__XXX
 SG_ EPBR_a117_VEH_thermalStatus m117 : 37|1@1+ (1,0) [0|0] "" Vector__XXX
 SG_ EPBR_a118_CH_12VBatteryStatus m118 : 37|1@1+ (1,0) [0|0] "" Vector__XXX
 SG_ EPBR_a120_VEH_estimatedBrakeTemp m120 : 37|1@1+ (1,0) [0|0] "" Vector__XXX
 SG_ EPBR_a174_monitorFaultStatus m174 : 37|2@1+ (1,0) [0|0] "" Vector__XXX
 SG_ EPBR_a175_monitorFaultStatus m175 : 37|2@1+ (1,0) [0|0] "" Vector__XXX
 SG_ EPBR_a176_monitorFaultStatus m176 : 37|2@1+ (1,0) [0|0] "" Vector__XXX
 SG_ EPBR_a177_monitorFaultStatus m177 : 37|2@1+ (1,0) [0|0] "" Vector__XXX
 SG_ EPBR_a179_monitorFaultStatus m179 : 37|2@1+ (1,0) [0|0] "" Vector__XXX
 SG_ EPBR_a180_panicModeLatched m180 : 37|1@1+ (1,0) [0|0] "" Vector__XXX
 SG_ EPBR_a184_panicModeLatched m184 : 37|1@1+ (1,0) [0|0] "" Vector__XXX
 SG_ EPBR_a186_panicModeLatched m186 : 37|1@1+ (1,0) [0|0] "" Vector__XXX
 SG_ EPBR_a187_panicModeLatched m187 : 37|1@1+ (1,0) [0|0] "" Vector__XXX
 SG_ EPBR_a188_panicModeLatched m188 : 37|1@1+ (1,0) [0|0] "" Vector__XXX
 SG_ EPBR_a189_panicModeLatched m189 : 37|1@1+ (1,0) [0|0] "" Vector__XXX
 SG_ EPBR_a190_monitorFaultStatus m190 : 37|2@1+ (1,0) [0|0] "" Vector__XXX
 SG_ EPBR_a191_monitorFaultStatus m191 : 37|2@1+ (1,0) [0|0] "" Vector__XXX
 SG_ EPBR_a198_resistanceCalc m198 : 37|12@1+ (0.005,0) [0|0] "" Vector__XXX
 SG_ EPBR_a225_panicModeLatched m225 : 37|1@1+ (1,0) [0|0] "" Vector__XXX
 SG_ EPBR_a246_faultStatus m246 : 37|2@1+ (1,0) [0|0] "" Vector__XXX
 SG_ EPBR_a247_monitorFaultStatus m247 : 37|2@1+ (1,0) [0|0] "" Vector__XXX
 SG_ EPBR_a248_monitorFaultStatus m248 : 37|2@1+ (1,0) [0|0] "" Vector__XXX
 SG_ EPBR_a249_faultStatus m249 : 37|2@1+ (1,0) [0|0] "" Vector__XXX
 SG_ EPBR_a264_frunkOpen m264 : 37|1@1+ (1,0) [0|0] "" Vector__XXX
 SG_ EPBR_a104_CH_pscControl m104 : 38|1@1+ (1,0) [0|0] "" Vector__XXX
 SG_ EPBR_a113_VEH_tripPlanning m113 : 38|1@1+ (1,0) [0|0] "" Vector__XXX
 SG_ EPBR_a116_BDY_epbmStatus m116 : 38|1@1+ (1,0) [0|0] "" Vector__XXX
 SG_ EPBR_a117_PARTY_doorStatus m117 : 38|1@1+ (1,0) [0|0] "" Vector__XXX
 SG_ EPBR_a118_CH_LVBMS_statusHigh m118 : 38|1@1+ (1,0) [0|0] "" Vector__XXX
 SG_ EPBR_a120_PARTY_prndControl m120 : 38|1@1+ (1,0) [0|0] "" Vector__XXX
 SG_ EPBR_a180_activeDecelRequest m180 : 38|1@1+ (1,0) [0|0] "" Vector__XXX
 SG_ EPBR_a184_activeDecelRequest m184 : 38|1@1+ (1,0) [0|0] "" Vector__XXX
 SG_ EPBR_a186_activeDecelRequest m186 : 38|1@1+ (1,0) [0|0] "" Vector__XXX
 SG_ EPBR_a187_activeDecelRequest m187 : 38|1@1+ (1,0) [0|0] "" Vector__XXX
 SG_ EPBR_a188_activeDecelRequest m188 : 38|1@1+ (1,0) [0|0] "" Vector__XXX
 SG_ EPBR_a189_activeDecelRequest m189 : 38|1@1+ (1,0) [0|0] "" Vector__XXX
 SG_ EPBR_a225_activeDecelRequest m225 : 38|1@1+ (1,0) [0|0] "" Vector__XXX
 SG_ EPBR_a362_inputRodDriver m362 : 38|10@1+ (0.1,-10) [0|0] "" Vector__XXX
 SG_ EPBR_a363_inputRodDriver m363 : 38|10@1+ (0.1,-10) [0|0] "" Vector__XXX
 SG_ EPBR_a058_prevREstimate m58 : 39|12@1+ (0.00061,0) [0|0] "" Vector__XXX
 SG_ EPBR_a104_BDY_gpsAccuracies m104 : 39|1@1+ (1,0) [0|0] "" Vector__XXX
 SG_ EPBR_a113_VEH_vehicleControl3 m113 : 39|1@1+ (1,0) [0|0] "" Vector__XXX
 SG_ EPBR_a116_BDY_restraintStatus m116 : 39|1@1+ (1,0) [0|0] "" Vector__XXX
 SG_ EPBR_a117_VEH_status m117 : 39|1@1+ (1,0) [0|0] "" Vector__XXX
 SG_ EPBR_a118_CH_alertMatrix m118 : 39|1@1+ (1,0) [0|0] "" Vector__XXX
 SG_ EPBR_a120_PARTY_locStatus2 m120 : 39|1@1+ (1,0) [0|0] "" Vector__XXX
 SG_ EPBR_a253_lvDriveStatusBlock m253 : 39|1@1+ (1,0) [0|0] "" Vector__XXX
 SG_ EPBR_a022_TaskInitError2 m22 : 40|8@1+ (1,0) [0|0] "" Vector__XXX
 SG_ EPBR_a031_uds_bytes_3 m31 : 40|8@1+ (1,0) [0|0] "" Vector__XXX
 SG_ EPBR_a041_CPULoad100msTask m41 : 40|8@1+ (1,0) [0|0] "" Vector__XXX
 SG_ EPBR_a042_Usage1000msTask m42 : 40|8@1+ (1,0) [0|0] "" Vector__XXX
 SG_ EPBR_a043_CallTrace1 m43 : 40|24@1+ (1,0) [0|0] "" Vector__XXX
 SG_ EPBR_a044_CallTrace1 m44 : 40|24@1+ (1,0) [0|0] "" Vector__XXX
 SG_ EPBR_a045_CallTrace1 m45 : 40|24@1+ (1,0) [0|0] "" Vector__XXX
 SG_ EPBR_a046_CallTrace1 m46 : 40|24@1+ (1,0) [0|0] "" Vector__XXX
 SG_ EPBR_a059_current m59 : 40|12@1+ (0.05,0) [0|0] "" Vector__XXX
 SG_ EPBR_a063_disconnected m63 : 40|1@1+ (1,0) [0|0] "" Vector__XXX
 SG_ EPBR_a104_BDY_control m104 : 40|1@1+ (1,0) [0|0] "" Vector__XXX
 SG_ EPBR_a113_VEH_vehicleControlThermal m113 : 40|1@1+ (1,0) [0|0] "" Vector__XXX
 SG_ EPBR_a116_BDY_switchStatus m116 : 40|1@1+ (1,0) [0|0] "" Vector__XXX
 SG_ EPBR_a117_PARTY_prndStatus m117 : 40|1@1+ (1,0) [0|0] "" Vector__XXX
 SG_ EPBR_a118_BDY_outputPowerStatus m118 : 40|1@1+ (1,0) [0|0] "" Vector__XXX
 SG_ EPBR_a120_VEH_chassisCntl m120 : 40|1@1+ (1,0) [0|0] "" Vector__XXX
 SG_ EPBR_a125_12vFilt m125 : 40|12@1+ (0.005443676098,0) [0|0] "" Vector__XXX
 SG_ EPBR_a126_12vFilt m126 : 40|12@1+ (0.005443676098,0) [0|0] "" Vector__XXX
 SG_ EPBR_a127_12vFilt m127 : 40|12@1+ (0.005443676098,0) [0|0] "" Vector__XXX
 SG_ EPBR_a128_12vFilt m128 : 40|12@1+ (0.005443676098,0) [0|0] "" Vector__XXX
 SG_ EPBR_a134_12vFilt m134 : 40|12@1+ (0.005443676098,0) [0|0] "" Vector__XXX
 SG_ EPBR_a135_12vFilt m135 : 40|12@1+ (0.005443676098,0) [0|0] "" Vector__XXX
 SG_ EPBR_a136_12vFilt m136 : 40|12@1+ (0.005443676098,0) [0|0] "" Vector__XXX
 SG_ EPBR_a137_12vFilt m137 : 40|12@1+ (0.005443676098,0) [0|0] "" Vector__XXX
 SG_ EPBR_a170_12vFilt m170 : 40|12@1+ (0.005443676098,0) [0|0] "" Vector__XXX
 SG_ EPBR_a171_12vFilt m171 : 40|12@1+ (0.005443676098,0) [0|0] "" Vector__XXX
 SG_ EPBR_a174_csmFaultReason m174 : 40|5@1+ (1,0) [0|0] "" Vector__XXX
 SG_ EPBR_a175_csmFaultReason m175 : 40|5@1+ (1,0) [0|0] "" Vector__XXX
 SG_ EPBR_a176_csmFaultReason m176 : 40|5@1+ (1,0) [0|0] "" Vector__XXX
 SG_ EPBR_a177_csmFaultReason m177 : 40|5@1+ (1,0) [0|0] "" Vector__XXX
 SG_ EPBR_a179_csmFaultReason m179 : 40|5@1+ (1,0) [0|0] "" Vector__XXX
 SG_ EPBR_a182_vcTrailerDetected m182 : 40|1@1+ (1,0) [0|0] "" Vector__XXX
 SG_ EPBR_a183_esmOperationTrigger m183 : 40|6@1+ (1,0) [0|0] "" Vector__XXX
 SG_ EPBR_a190_csmFaultReason m190 : 40|5@1+ (1,0) [0|0] "" Vector__XXX
 SG_ EPBR_a191_csmFaultReason m191 : 40|5@1+ (1,0) [0|0] "" Vector__XXX
 SG_ EPBR_a216_byte2 m216 : 40|8@1+ (1,0) [0|0] "" Vector__XXX
 SG_ EPBR_a217_byte7 m217 : 40|8@1+ (1,0) [0|0] "" Vector__XXX
 SG_ EPBR_a246_esmOpTrigger m246 : 40|6@1+ (1,0) [0|0] "" Vector__XXX
 SG_ EPBR_a247_csmFaultReason m247 : 40|5@1+ (1,0) [0|0] "" Vector__XXX
 SG_ EPBR_a248_csmFaultReason m248 : 40|5@1+ (1,0) [0|0] "" Vector__XXX
 SG_ EPBR_a249_esmOpTrigger m249 : 40|6@1+ (1,0) [0|0] "" Vector__XXX
 SG_ EPBR_a253_steeringDriveStatusBlock m253 : 40|1@1+ (1,0) [0|0] "" Vector__XXX
 SG_ EPBR_a357_brakeTemp m357 : 40|11@1+ (1,-40) [0|0] "" Vector__XXX
 SG_ EPBR_a358_brakeTemp m358 : 40|11@1+ (1,-40) [0|0] "" Vector__XXX
 SG_ EPBR_a365_vcTrailerDetected m365 : 40|1@1+ (1,0) [0|0] "" Vector__XXX
 SG_ EPBR_a366_vcTrailerDetected m366 : 40|1@1+ (1,0) [0|0] "" Vector__XXX
 SG_ EPBR_a063_indeterminate m63 : 41|1@1+ (1,0) [0|0] "" Vector__XXX
 SG_ EPBR_a104_BDY_status m104 : 41|1@1+ (1,0) [0|0] "" Vector__XXX
 SG_ EPBR_a113_CH_odo m113 : 41|1@1+ (1,0) [0|0] "" Vector__XXX
 SG_ EPBR_a117_PARTY_lightingSecondary m117 : 41|1@1+ (1,0) [0|0] "" Vector__XXX
 SG_ EPBR_a118_BDY_vehicleTime m118 : 41|1@1+ (1,0) [0|0] "" Vector__XXX
 SG_ EPBR_a120_CH_locStatus2 m120 : 41|1@1+ (1,0) [0|0] "" Vector__XXX
 SG_ EPBR_a182_uiTrailerDetected m182 : 41|1@1+ (1,0) [0|0] "" Vector__XXX
 SG_ EPBR_a365_uiTrailerDetected m365 : 41|1@1+ (1,0) [0|0] "" Vector__XXX
 SG_ EPBR_a366_uiTrailerDetected m366 : 41|1@1+ (1,0) [0|0] "" Vector__XXX
 SG_ EPBR_a063_stuckActive m63 : 42|1@1+ (1,0) [0|0] "" Vector__XXX
 SG_ EPBR_a104_PARTY_autonomyControl m104 : 42|1@1+ (1,0) [0|0] "" Vector__XXX
 SG_ EPBR_a113_VEH_locationStatus m113 : 42|1@1+ (1,0) [0|0] "" Vector__XXX
 SG_ EPBR_a118_PARTY_AP_vehicleState1HzMuxed m118 : 42|1@1+ (1,0) [0|0] "" Vector__XXX
 SG_ EPBR_a120_VEH_locStatus m120 : 42|1@1+ (1,0) [0|0] "" Vector__XXX
 SG_ EPBR_a182_trailerDetected m182 : 42|1@1+ (1,0) [0|0] "" Vector__XXX
 SG_ EPBR_a350_ensTimedOut m350 : 42|1@1+ (1,0) [0|0] "" Vector__XXX
 SG_ EPBR_a352_startTime m352 : 42|10@1+ (10,0) [0|0] "" Vector__XXX
 SG_ EPBR_a365_trailerDetected m365 : 42|1@1+ (1,0) [0|0] "" Vector__XXX
 SG_ EPBR_a366_trailerDetected m366 : 42|1@1+ (1,0) [0|0] "" Vector__XXX
 SG_ EPBR_a063_faulted m63 : 43|1@1+ (1,0) [0|0] "" Vector__XXX
 SG_ EPBR_a104_VEH_autonomyControl m104 : 43|1@1+ (1,0) [0|0] "" Vector__XXX
 SG_ EPBR_a113_VEH_gpsTime m113 : 43|1@1+ (1,0) [0|0] "" Vector__XXX
 SG_ EPBR_a118_BDY_AP_vehicleState1HzMuxed m118 : 43|1@1+ (1,0) [0|0] "" Vector__XXX
 SG_ EPBR_a120_VEH_locStatus2 m120 : 43|1@1+ (1,0) [0|0] "" Vector__XXX
 SG_ EPBR_a104_CH_autonomyControl m104 : 44|1@1+ (1,0) [0|0] "" Vector__XXX
 SG_ EPBR_a113_VEH_gpsVehicleSpeed m113 : 44|1@1+ (1,0) [0|0] "" Vector__XXX
 SG_ EPBR_a118_PARTY_VCFRONT_cameraCleaningStatus m118 : 44|1@1+ (1,0) [0|0] "" Vector__XXX
 SG_ EPBR_a120_VEH_prndControl m120 : 44|1@1+ (1,0) [0|0] "" Vector__XXX
 SG_ EPBR_a104_BDY_autonomyControl m104 : 45|1@1+ (1,0) [0|0] "" Vector__XXX
 SG_ EPBR_a113_VEH_status2 m113 : 45|1@1+ (1,0) [0|0] "" Vector__XXX
 SG_ EPBR_a120_VEH_vehicleEstimates m120 : 45|1@1+ (1,0) [0|0] "" Vector__XXX
 SG_ EPBR_a251_temperature m251 : 45|9@1- (0.5,-40) [0|0] "" Vector__XXX
 SG_ EPBR_a303_temperature m303 : 45|9@1- (0.5,-40) [0|0] "" Vector__XXX
 SG_ EPBR_a104_VEH_wirelessChargingStatus m104 : 46|1@1+ (1,0) [0|0] "" Vector__XXX
 SG_ EPBR_a113_VEH_autopilotControl m113 : 46|1@1+ (1,0) [0|0] "" Vector__XXX
 SG_ EPBR_a120_PARTY_motorStatus m120 : 46|1@1+ (1,0) [0|0] "" Vector__XXX
 SG_ EPBR_a183_cdpNotStopping m183 : 46|1@1+ (1,0) [0|0] "" Vector__XXX
 SG_ EPBR_a104_VEH_control m104 : 47|1@1+ (1,0) [0|0] "" Vector__XXX
 SG_ EPBR_a113_VEH_ambientLightingCtrls m113 : 47|1@1+ (1,0) [0|0] "" Vector__XXX
 SG_ EPBR_a120_VEH_motorStatus m120 : 47|1@1+ (1,0) [0|0] "" Vector__XXX
 SG_ EPBR_a183_cdpNotStarting m183 : 47|1@1+ (1,0) [0|0] "" Vector__XXX
 SG_ EPBR_a000_alertDataW2 m0 : 48|16@1+ (1,0) [0|0] "" Vector__XXX
 SG_ EPBR_a003_Data m3 : 48|16@1+ (1,0) [0|0] "" Vector__XXX
 SG_ EPBR_a022_TaskInitError3 m22 : 48|8@1+ (1,0) [0|0] "" Vector__XXX
 SG_ EPBR_a031_uds_bytes_4 m31 : 48|8@1+ (1,0) [0|0] "" Vector__XXX
 SG_ EPBR_a041_CPULoad1000msTask m41 : 48|8@1+ (1,0) [0|0] "" Vector__XXX
 SG_ EPBR_a042_UsageUDSTask m42 : 48|8@1+ (1,0) [0|0] "" Vector__XXX
 SG_ EPBR_a104_VEH_redundantBrakingControl m104 : 48|1@1+ (1,0) [0|0] "" Vector__XXX
 SG_ EPBR_a113_VEH_driverAssistMapData m113 : 48|1@1+ (1,0) [0|0] "" Vector__XXX
 SG_ EPBR_a120_BDY_speed m120 : 48|1@1+ (1,0) [0|0] "" Vector__XXX
 SG_ EPBR_a140_localState m140 : 48|3@1+ (1,0) [0|0] "" Vector__XXX
 SG_ EPBR_a174_esmOpTrigger m174 : 48|6@1+ (1,0) [0|0] "" Vector__XXX
 SG_ EPBR_a175_esmOpTrigger m175 : 48|6@1+ (1,0) [0|0] "" Vector__XXX
 SG_ EPBR_a176_esmOpTrigger m176 : 48|6@1+ (1,0) [0|0] "" Vector__XXX
 SG_ EPBR_a177_esmOpTrigger m177 : 48|6@1+ (1,0) [0|0] "" Vector__XXX
 SG_ EPBR_a179_esmOpTrigger m179 : 48|6@1+ (1,0) [0|0] "" Vector__XXX
 SG_ EPBR_a183_remoteEpbDynamic m183 : 48|1@1+ (1,0) [0|0] "" Vector__XXX
 SG_ EPBR_a190_esmOpTrigger m190 : 48|6@1+ (1,0) [0|0] "" Vector__XXX
 SG_ EPBR_a191_esmOpTrigger m191 : 48|6@1+ (1,0) [0|0] "" Vector__XXX
 SG_ EPBR_a216_byte3 m216 : 48|8@1+ (1,0) [0|0] "" Vector__XXX
 SG_ EPBR_a247_esmOpTrigger m247 : 48|6@1+ (1,0) [0|0] "" Vector__XXX
 SG_ EPBR_a248_esmOpTrigger m248 : 48|6@1+ (1,0) [0|0] "" Vector__XXX
 SG_ EPBR_a301_oocDistanceFiltered m301 : 48|16@1+ (0.01,0) [0|0] "" Vector__XXX
 SG_ EPBR_a363_outputRodAct m363 : 48|10@1+ (0.1,-10) [0|0] "" Vector__XXX
 SG_ EPBR_a370_messageBitmask m370 : 48|16@1+ (1,0) [0|0] "" Vector__XXX
 SG_ EPBR_a104_BDY_bodyControls m104 : 49|1@1+ (1,0) [0|0] "" Vector__XXX
 SG_ EPBR_a113_CH_vehicleControl2 m113 : 49|1@1+ (1,0) [0|0] "" Vector__XXX
 SG_ EPBR_a183_localEpbDynamic m183 : 49|1@1+ (1,0) [0|0] "" Vector__XXX
 SG_ EPBR_a198_learnedEpbConfig m198 : 49|4@1+ (1,0) [0|0] "" Vector__XXX
 SG_ EPBR_a113_VEH_odo m113 : 50|1@1+ (1,0) [0|0] "" Vector__XXX
 SG_ EPBR_a183_epbmInvalidated m183 : 50|1@1+ (1,0) [0|0] "" Vector__XXX
 SG_ EPBR_a058_newREstimate m58 : 51|12@1+ (0.00061,0) [0|0] "" Vector__XXX
 SG_ EPBR_a140_monitorState m140 : 51|3@1+ (1,0) [0|0] "" Vector__XXX
 SG_ EPBR_a183_espConfirmedInvalid m183 : 51|1@1+ (1,0) [0|0] "" Vector__XXX
 SG_ EPBR_a357_vcTrailerDetected m357 : 51|1@1+ (1,0) [0|0] "" Vector__XXX
 SG_ EPBR_a358_vcTrailerDetected m358 : 51|1@1+ (1,0) [0|0] "" Vector__XXX
 SG_ EPBR_a183_brakeFluidConfirmedLow m183 : 52|1@1+ (1,0) [0|0] "" Vector__XXX
 SG_ EPBR_a352_duration m352 : 52|10@1+ (1,0) [0|0] "" Vector__XXX
 SG_ EPBR_a357_uiTrailerDetected m357 : 52|1@1+ (1,0) [0|0] "" Vector__XXX
 SG_ EPBR_a358_uiTrailerDetected m358 : 52|1@1+ (1,0) [0|0] "" Vector__XXX
 SG_ EPBR_a183_lastRemoteEpbDynamic m183 : 53|1@1+ (1,0) [0|0] "" Vector__XXX
 SG_ EPBR_a198_ambientTemp m198 : 53|8@1+ (0.5,-40) [0|0] "" Vector__XXX
 SG_ EPBR_a357_trailerDetected m357 : 53|1@1+ (1,0) [0|0] "" Vector__XXX
 SG_ EPBR_a358_trailerDetected m358 : 53|1@1+ (1,0) [0|0] "" Vector__XXX
 SG_ EPBR_a183_lastLocalEpbDynamic m183 : 54|1@1+ (1,0) [0|0] "" Vector__XXX
 SG_ EPBR_a183_cdpCannotBeCommanded m183 : 55|1@1+ (1,0) [0|0] "" Vector__XXX
 SG_ EPBR_a022_TaskInitError4 m22 : 56|8@1+ (1,0) [0|0] "" Vector__XXX
 SG_ EPBR_a031_uds_bytes_5 m31 : 56|8@1+ (1,0) [0|0] "" Vector__XXX
 SG_ EPBR_a041_CPULoadNVMMTask m41 : 56|8@1+ (1,0) [0|0] "" Vector__XXX
 SG_ EPBR_a042_UsageNVMMTask m42 : 56|8@1+ (1,0) [0|0] "" Vector__XXX
 SG_ EPBR_a174_nonterminalReason m174 : 56|5@1+ (1,0) [0|0] "" Vector__XXX
 SG_ EPBR_a175_nonterminalReason m175 : 56|5@1+ (1,0) [0|0] "" Vector__XXX
 SG_ EPBR_a176_nonterminalReason m176 : 56|5@1+ (1,0) [0|0] "" Vector__XXX
 SG_ EPBR_a177_nonterminalReason m177 : 56|5@1+ (1,0) [0|0] "" Vector__XXX
 SG_ EPBR_a179_nonterminalReason m179 : 56|5@1+ (1,0) [0|0] "" Vector__XXX
 SG_ EPBR_a183_remoteEpbStatusUnsure m183 : 56|1@1+ (1,0) [0|0] "" Vector__XXX
 SG_ EPBR_a190_nonterminalReason m190 : 56|5@1+ (1,0) [0|0] "" Vector__XXX
 SG_ EPBR_a191_nonterminalReason m191 : 56|5@1+ (1,0) [0|0] "" Vector__XXX
 SG_ EPBR_a247_nonterminalReason m247 : 56|5@1+ (1,0) [0|0] "" Vector__XXX
 SG_ EPBR_a248_nonterminalReason m248 : 56|5@1+ (1,0) [0|0] "" Vector__XXX
 SG_ EPBR_a183_lastLowBrakeFluid m183 : 57|1@1+ (1,0) [0|0] "" Vector__XXX
 SG_ EPBR_a183_espInvalidOrUnsure m183 : 58|1@1+ (1,0) [0|0] "" Vector__XXX
 SG_ EPBR_a183_lastFactoryMode m183 : 59|1@1+ (1,0) [0|0] "" Vector__XXX
 SG_ EPBR_a183_redundantBrakingEnabled m183 : 60|1@1+ (1,0) [0|0] "" Vector__XXX
 SG_ EPBR_a198_version m198 : 61|3@1+ (1,0) [0|0] "" Vector__XXX
 SG_ EPBR_a086_VEH_LVHealth m86 : 62|1@1+ (1,0) [0|0] "" Vector__XXX
 SG_ EPBR_a058_faultReason m58 : 63|1@1+ (1,0) [0|0] "" Vector__XXX
 SG_ EPBR_a086_VEH_pcsInterface m86 : 63|1@1+ (1,0) [0|0] "" Vector__XXX

BO_ 1467 SDCR_alertMatrix: 8 Vector__XXX
 SG_ SDCR_matrixIndex M : 0|4@1+ (1,0) [0|0] "" Vector__XXX
 SG_ SDCR_a001_powerOnSelfTestFailed m0 : 4|1@1+ (1,0) [0|0] "" Vector__XXX
 SG_ SDCR_a002_diPstSkipped m0 : 5|1@1+ (1,0) [0|0] "" Vector__XXX
 SG_ SDCR_a003_diUartMIA m0 : 6|1@1+ (1,0) [0|0] "" Vector__XXX
 SG_ SDCR_a004_pmRunningFdbkIrrational m0 : 7|1@1+ (1,0) [0|0] "" Vector__XXX
 SG_ SDCR_a005_motorSpeedIrrational m0 : 8|1@1+ (1,0) [0|0] "" Vector__XXX
 SG_ SDCR_a006_pyroTriggered m0 : 9|1@1+ (1,0) [0|0] "" Vector__XXX
 SG_ SDCR_a007_faultCurrentsDetected m0 : 10|1@1+ (1,0) [0|0] "" Vector__XXX
 SG_ SDCR_a008_hvlinkMIA m0 : 11|1@1+ (1,0) [0|0] "" Vector__XXX
 SG_ SDCR_a009_uartVersionMismatch m0 : 12|1@1+ (1,0) [0|0] "" Vector__XXX
 SG_ SDCR_a010_vrefIrrational m0 : 13|1@1+ (1,0) [0|0] "" Vector__XXX
 SG_ SDCR_a011_phaseCurrentOffset m0 : 14|1@1+ (1,0) [0|0] "" Vector__XXX
 SG_ SDCR_a012_vBoostSecIrrational m0 : 15|1@1+ (1,0) [0|0] "" Vector__XXX
 SG_ SDCR_a013_vBkupIrrational m0 : 16|1@1+ (1,0) [0|0] "" Vector__XXX
 SG_ SDCR_a014_vBusIrrational m0 : 17|1@1+ (1,0) [0|0] "" Vector__XXX
 SG_ SDCR_a015_phaseVIrrational m0 : 18|1@1+ (1,0) [0|0] "" Vector__XXX
 SG_ SDCR_a016_systemReset m0 : 19|1@1+ (1,0) [0|0] "" Vector__XXX
 SG_ SDCR_a017_adcSPIError m0 : 20|1@1+ (1,0) [0|0] "" Vector__XXX
 SG_ SDCR_a018_historicalPyroTrigger m0 : 21|1@1+ (1,0) [0|0] "" Vector__XXX
 SG_ SDCR_a019_historicalFaultCurrents m0 : 22|1@1+ (1,0) [0|0] "" Vector__XXX
 SG_ SDCR_a020_eepromSPIError m0 : 23|1@1+ (1,0) [0|0] "" Vector__XXX
 SG_ SDCR_a021_busBarTempIrrational m0 : 24|1@1+ (1,0) [0|0] "" Vector__XXX
 SG_ SDCR_a022_TaskInitError m0 : 25|1@1+ (1,0) [0|0] "" Vector__XXX
 SG_ SDCR_a023_ecuLogAvailable m0 : 26|1@1+ (1,0) [0|0] "" Vector__XXX
 SG_ SDCR_a024_gtwMIA m0 : 27|1@1+ (1,0) [0|0] "" Vector__XXX
 SG_ SDCR_a025_diSwitchingFdbkIrrational m0 : 28|1@1+ (1,0) [0|0] "" Vector__XXX
 SG_ SDCR_a026_faultCurrentMonitoringDisabled m0 : 29|1@1+ (1,0) [0|0] "" Vector__XXX
 SG_ SDCR_a027_diCanMIA m0 : 30|1@1+ (1,0) [0|0] "" Vector__XXX
 SG_ SDCR_a028_vcLVStateMIA m0 : 31|1@1+ (1,0) [0|0] "" Vector__XXX
 SG_ SDCR_a029_diMIA m0 : 32|1@1+ (1,0) [0|0] "" Vector__XXX
 SG_ SDCR_a030_placeholder30 m0 : 33|1@1+ (1,0) [0|0] "" Vector__XXX
 SG_ SDCR_a031_placeholder31 m0 : 34|1@1+ (1,0) [0|0] "" Vector__XXX
 SG_ SDCR_a032_placeholder32 m0 : 35|1@1+ (1,0) [0|0] "" Vector__XXX
 SG_ SDCR_a033_placeholder33 m0 : 36|1@1+ (1,0) [0|0] "" Vector__XXX
 SG_ SDCR_a034_phaseCurrentIrrational m0 : 37|1@1+ (1,0) [0|0] "" Vector__XXX

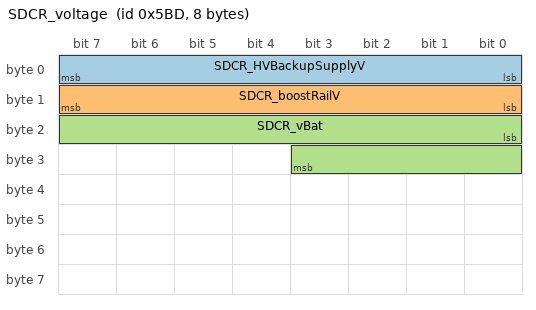
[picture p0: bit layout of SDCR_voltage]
BO_ 1469 SDCR_voltage: 8 Vector__XXX
 SG_ SDCR_HVBackupSupplyV : 0|8@1+ (0.15,0) [0|0] "" Vector__XXX
 SG_ SDCR_boostRailV : 8|8@1+ (0.15,0) [0|0] "" Vector__XXX
 SG_ SDCR_vBat : 16|12@1+ (0.4,0) [0|0] "" Vector__XXX

VAL_ 1445 DIR_alertID 0 "ALERT_DO_NOT_USE_ZERO" 1 "a001_DriverDoorOpen" 2 "a002_DoorOpen" 3 "a003_TrunkOpen" 4 "a004_FrunkOpen" 5 "a005_HeadlightsOnDoorOpen" 6 "a006_RemoteServiceAlert" 7 "a007_SoftPackConfigMismatch" 8 "a008_TouchScreenError" 9 "a009_SquashfsError" 10 "a010_MapsMissing" 11 "a011_IncorrectMap" 12 "a012_NotOnPrivateProperty" 13 "a013_TPMSHardWarning" 14 "a014_TPMSSoftWarning" 15 "a015_TPMSOverPressureWarning" 16 "a016_TPMSTemperatureWarning" 17 "a017_TPMSSystemFault" 18 "a018_SlipStartOn" 19 "a019_ParkBrakeFault" 20 "a020_SteeringReduced" 21 "a021_RearSeatbeltUnbuckled" 22 "a022_ApeFusesEtc" 23 "a023_CellInternetCheckFailed" 24 "a024_WifiInternetCheckFailed" 25 "a025_WifiOnlineCheckFailed" 26 "a026_ModemResetLoopDetected" 27 "a027_AutoSteerMIA" 28 "a028_FrontTrunkPopupClosed" 29 "a029_ModemMIA" 30 "a030_ModemVMCrash" 31 "a031_BrakeFluidLow" 32 "a032_CellModemRecoveryResets" 33 "a033_ApTrialExpired" 34 "a034_WakeupProblem" 35 "a035_AudioWatchdogKernelError" 36 "a036_AudioWatchdogHfpError" 37 "a037_AudioWatchdogXrunStormError" 38 "a038_AudioWatchdogA2bI2cLockupError" 39 "a039_AudioA2bNeedRediscovery" 40 "a040_HomelinkTransmit" 41 "a041_AudioDmesgXrun" 42 "a042_AudioDmesgRtThrottling" 43 "a043_InvalidMapDataOverride" 44 "a044_AudioDmesgDspException" 45 "a045_ECallNeedsService" 46 "a046_BackupCameraStreamError" 47 "a047_CellRoamingDisallowed" 48 "a048_AudioPremiumAmpCheckFailed" 49 "a049_BrakeShiftRequired" 50 "a050_BackupCameraIPUTimeout" 51 "a051_BackupCameraFrameTimeout" 52 "a052_KernelPanicReported" 53 "a053_QtCarExitError" 54 "a054_AudioBoostPowerBad" 55 "a055_ManualECallDisabled" 56 "a056_ManualECallButtonDisconnected" 57 "a057_CellAntennaDisconnected" 58 "a058_GPSAntennaDisconnected" 59 "a059_ECallSpeakerDisconnected" 60 "a060_ECallMicDisconnected" 61 "a061_SIMTestFailed" 62 "a062_ENSTestFailed" 63 "a063_CellularTestFailed" 64 "a064_ModemFirmwareTestFailed" 65 "a065_WiFiRecoveryReset" 66 "a066_GpuHangDetected" 67 "a067_WarnOnI915" 68 "a068_VideoUnexpectedExit" 69 "a069_VideoUDPTimeout" 70 "a070_VideoPipelineWarning" 71 "a071_VideoPipelineError" 72 "a072_ECallAnalogMicFailed" 73 "a073_ECallDigitalMicFailed" 74 "a074_EMMCHangDetected" 75 "a075_BackupCameraInitError" 76 "a076_NumFalseManualECalls" 77 "a077_AudioA2bMicChannelSwap" 78 "a078_DashcamUsbDriveUnmountable" 79 "a079_DashcamUsbDriveFull" 80 "a080_DashcamUsbDriveSlow" 81 "a081_CellModemSearchExpired" 82 "a082_NumModemRebootStuckInECall" 83 "a083_ECallProxyWatchdogTriggered" 84 "a084_SerializerError" 85 "a085_DeserializerError" 86 "a086_TouchEnumerationError" 87 "a087_BmpReset" 88 "a088_CellRemovableSimMissing" 89 "a089_RadioSoftResetError" 90 "a090_RadioPingFailError" 91 "a091_VehicleLinkStall" 92 "a092_updateStarted" 93 "a093_updateEnded" 94 "a094_ModemPowerOnFailure" 95 "a095_CidStorageRunningLow" 96 "a096_VideodPipelineIssueDetected" 97 "a097_AudiodRestarted" 98 "a098_DiskCheckFailure" 99 "a099_eMMCStatusError" 100 "a100_eMMCFTLError" 101 "a101_wifiStackProblem" 102 "a102_A2bDiscoveryFailed" 103 "a103_UsbHubNotEnumerating" 104 "a104_DashcamUsbDriveMissing" 105 "a105_firmwareReinstallRequested" 106 "a106_rebootBackstopTriggered" 107 "a107_DashcamUsbDriveTooBigForVfatFsck" 108 "a108_DashcamUsbDriveGettingFull" 109 "a109_DashcamUsbDriveTooSmall" 110 "a110_DashcamUsbDriveCorrupt" 111 "a111_DashcamUsbDriveWrongPort" 112 "a112_badUSBDevice" 113 "a113_DashcamHasOnboardSentryClips" ;
VAL_ 1445 DIR_alertState 0 "CLEARED" 1 "SET" ;
VAL_ 1445 DIR_a110_EPBL_status 0 "DISABLED" 1 "ENABLED" 2 "TEMPORARY_FAILURE" 3 "SNA" ;
VAL_ 1445 DIR_a144_autopilot 0 "NONE" 1 "HIGHWAY" 2 "ENHANCED" 3 "SELF_DRIVING" 4 "BASIC" ;
VAL_ 1445 DIR_a162_normalFetBurnIn 65535 "SNA" ;
VAL_ 1445 DIR_a110_EPBR_status 0 "DISABLED" 1 "ENABLED" 2 "TEMPORARY_FAILURE" 3 "SNA" ;
VAL_ 1445 DIR_a144_chassisType 2 "3_CHASSIS" 3 "Y_CHASSIS" ;
VAL_ 1445 DIR_a158_BUS1_IBST_status 0 "DISABLED" 1 "ENABLED" 2 "TEMPORARY_FAILURE" 3 "SNA" ;
VAL_ 1445 DIR_a090_state 0 "STANDBY" 1 "DRIVE" 2 "SUPPORT" 3 "CHARGE" 4 "FEIM" 5 "CLEAR_FAULT" 6 "FAULT" 7 "WELD" 8 "TEST" 9 "SNA" 10 "DIAG" ;
VAL_ 1445 DIR_a144_drivetrainType 0 "RWD" 1 "AWD" ;
VAL_ 1445 DIR_a158_BUS2_IBST_status 0 "DISABLED" 1 "ENABLED" 2 "TEMPORARY_FAILURE" 3 "SNA" ;
VAL_ 1445 DIR_a040_status 0 "DISABLED" 1 "ENABLED" 2 "TEMPORARY_FAILURE" 3 "SNA" ;
VAL_ 1445 DIR_a052_status 0 "DISABLED" 1 "ENABLED" 2 "TEMPORARY_FAILURE" 3 "SNA" ;
VAL_ 1445 DIR_a144_packEnergy 0 "50_KWH" 1 "74_KWH" 2 "62_KWH" ;
VAL_ 1445 DIR_a155_status 0 "DISABLED" 1 "ENABLED" 2 "TEMPORARY_FAILURE" 3 "SNA" ;
VAL_ 1445 DIR_a091_ESP_status 0 "DISABLED" 1 "ENABLED" 2 "TEMPORARY_FAILURE" 3 "SNA" ;
VAL_ 1445 DIR_a144_performancePackage 0 "BASE" 1 "PERFORMANCE" 3 "BASE_PLUS" 4 "SNA" ;
VAL_ 1445 DIR_a117_systemStatus 0 "UNKNOWN" 1 "RELEASED" 2 "PARKED" 3 "DYNAMIC" 4 "PARKING" 5 "RELEASING" 6 "FAULT" 7 "FAULT_SECURE" 8 "MISMATCH" ;
VAL_ 1445 DIR_a144_vdcType 0 "BOSCH_VDC" 1 "TESLA_VDC" ;
VAL_ 1445 DIR_a144_brakeHWType 0 "P42_MANDO_43MOC" 1 "LARGE_P42_BREMBO_44MOC" 2 "LARGE_P42_MANDO_43MOC" 3 "LARGE_P42_BREMBO_LARGE_44MOC" 6 "LARGE_P42_V2_BREMBO_44MOC" 7 "LARGE_P42_V2_BREMBO_LARGE_44MOC" ;
VAL_ 1445 DIR_a162_additionalFetBurnIn 65535 "SNA" ;
VAL_ 1445 DIR_a144_cabinPTCHeaterType 0 "BORGWARNER" 1 "NONE" ;
VAL_ 1445 DIR_a155_systemStatus 0 "UNKNOWN" 1 "RELEASED" 2 "PARKED" 3 "DYNAMIC" 4 "PARKING" 5 "RELEASING" 6 "FAULT" 7 "FAULT_SECURE" 8 "MISMATCH" ;
VAL_ 1445 DIR_a144_frunkLatchType 0 "UNKNOWN" 1 "DOUBLE_ACTUATOR" 2 "DOUBLE_PULL" ;
VAL_ 1445 DIR_a024_state 0 "STANDBY" 1 "DRIVE" 2 "SUPPORT" 3 "CHARGE" 4 "FEIM" 5 "CLEAR_FAULT" 6 "FAULT" 7 "WELD" 8 "TEST" 9 "SNA" 10 "DIAG" ;
VAL_ 1445 DIR_a014_adState 0 "STARTUP" 1 "NORMAL" 2 "BACKUP" 3 "FAULTED" ;
VAL_ 1445 DIR_a144_dasHw 3 "PARKER_PASCAL_2_5" 4 "TESLA_AP3" ;
VAL_ 1445 DIR_a144_powerLiftgateType 0 "NOT_INSTALLED" 1 "TESLA_REV1" ;
VAL_ 1445 DIR_a149_state 0 "STANDBY" 1 "DRIVE" 2 "SUPPORT" 3 "CHARGE" 4 "FEIM" 5 "CLEAR_FAULT" 6 "FAULT" 7 "WELD" 8 "TEST" 9 "SNA" 10 "DIAG" ;
VAL_ 1445 DIR_a014_brakeMasterCylPress 1023 "SNA" ;
VAL_ 1445 DIR_a103_ambientTemp 4294966273 "SNA" ;
VAL_ 1445 DIR_a153_state 0 "STANDBY" 1 "DRIVE" 2 "SUPPORT" 3 "CHARGE" 4 "FEIM" 5 "CLEAR_FAULT" 6 "FAULT" 7 "WELD" 8 "TEST" 9 "SNA" 10 "DIAG" ;
VAL_ 1446 PMR_alertID 0 "ALERT_DO_NOT_USE_ZERO" 1 "a001_DriverDoorOpen" 2 "a002_DoorOpen" 3 "a003_TrunkOpen" 4 "a004_FrunkOpen" 5 "a005_HeadlightsOnDoorOpen" 6 "a006_RemoteServiceAlert" 7 "a007_SoftPackConfigMismatch" 8 "a008_TouchScreenError" 9 "a009_SquashfsError" 10 "a010_MapsMissing" 11 "a011_IncorrectMap" 12 "a012_NotOnPrivateProperty" 13 "a013_TPMSHardWarning" 14 "a014_TPMSSoftWarning" 15 "a015_TPMSOverPressureWarning" 16 "a016_TPMSTemperatureWarning" 17 "a017_TPMSSystemFault" 18 "a018_SlipStartOn" 19 "a019_ParkBrakeFault" 20 "a020_SteeringReduced" 21 "a021_RearSeatbeltUnbuckled" 22 "a022_ApeFusesEtc" 23 "a023_CellInternetCheckFailed" 24 "a024_WifiInternetCheckFailed" 25 "a025_WifiOnlineCheckFailed" 26 "a026_ModemResetLoopDetected" 27 "a027_AutoSteerMIA" 28 "a028_FrontTrunkPopupClosed" 29 "a029_ModemMIA" 30 "a030_ModemVMCrash" 31 "a031_BrakeFluidLow" 32 "a032_CellModemRecoveryResets" 33 "a033_ApTrialExpired" 34 "a034_WakeupProblem" 35 "a035_AudioWatchdogKernelError" 36 "a036_AudioWatchdogHfpError" 37 "a037_AudioWatchdogXrunStormError" 38 "a038_AudioWatchdogA2bI2cLockupError" 39 "a039_AudioA2bNeedRediscovery" 40 "a040_HomelinkTransmit" 41 "a041_AudioDmesgXrun" 42 "a042_AudioDmesgRtThrottling" 43 "a043_InvalidMapDataOverride" 44 "a044_AudioDmesgDspException" 45 "a045_ECallNeedsService" 46 "a046_BackupCameraStreamError" 47 "a047_CellRoamingDisallowed" 48 "a048_AudioPremiumAmpCheckFailed" 49 "a049_BrakeShiftRequired" 50 "a050_BackupCameraIPUTimeout" 51 "a051_BackupCameraFrameTimeout" 52 "a052_KernelPanicReported" 53 "a053_QtCarExitError" 54 "a054_AudioBoostPowerBad" 55 "a055_ManualECallDisabled" 56 "a056_ManualECallButtonDisconnected" 57 "a057_CellAntennaDisconnected" 58 "a058_GPSAntennaDisconnected" 59 "a059_ECallSpeakerDisconnected" 60 "a060_ECallMicDisconnected" 61 "a061_SIMTestFailed" 62 "a062_ENSTestFailed" 63 "a063_CellularTestFailed" 64 "a064_ModemFirmwareTestFailed" 65 "a065_WiFiRecoveryReset" 66 "a066_GpuHangDetected" 67 "a067_WarnOnI915" 68 "a068_VideoUnexpectedExit" 69 "a069_VideoUDPTimeout" 70 "a070_VideoPipelineWarning" 71 "a071_VideoPipelineError" 72 "a072_ECallAnalogMicFailed" 73 "a073_ECallDigitalMicFailed" 74 "a074_EMMCHangDetected" 75 "a075_BackupCameraInitError" 76 "a076_NumFalseManualECalls" 77 "a077_AudioA2bMicChannelSwap" 78 "a078_DashcamUsbDriveUnmountable" 79 "a079_DashcamUsbDriveFull" 80 "a080_DashcamUsbDriveSlow" 81 "a081_CellModemSearchExpired" 82 "a082_NumModemRebootStuckInECall" 83 "a083_ECallProxyWatchdogTriggered" 84 "a084_SerializerError" 85 "a085_DeserializerError" 86 "a086_TouchEnumerationError" 87 "a087_BmpReset" 88 "a088_CellRemovableSimMissing" 89 "a089_RadioSoftResetError" 90 "a090_RadioPingFailError" 91 "a091_VehicleLinkStall" 92 "a092_updateStarted" 93 "a093_updateEnded" 94 "a094_ModemPowerOnFailure" 95 "a095_CidStorageRunningLow" 96 "a096_VideodPipelineIssueDetected" 97 "a097_AudiodRestarted" 98 "a098_DiskCheckFailure" 99 "a099_eMMCStatusError" 100 "a100_eMMCFTLError" 101 "a101_wifiStackProblem" 102 "a102_A2bDiscoveryFailed" 103 "a103_UsbHubNotEnumerating" 104 "a104_DashcamUsbDriveMissing" 105 "a105_firmwareReinstallRequested" 106 "a106_rebootBackstopTriggered" 107 "a107_DashcamUsbDriveTooBigForVfatFsck" 108 "a108_DashcamUsbDriveGettingFull" 109 "a109_DashcamUsbDriveTooSmall" 110 "a110_DashcamUsbDriveCorrupt" 111 "a111_DashcamUsbDriveWrongPort" 112 "a112_badUSBDevice" 113 "a113_DashcamHasOnboardSentryClips" ;
VAL_ 1446 PMR_alertState 0 "CLEARED" 1 "SET" ;
VAL_ 1446 PMR_a017_EPBL_status 0 "DISABLED" 1 "ENABLED" 2 "TEMPORARY_FAILURE" 3 "SNA" ;
VAL_ 1446 PMR_a033_state 0 "STANDBY" 1 "DRIVE" 2 "SUPPORT" 3 "CHARGE" 4 "FEIM" 5 "CLEAR_FAULT" 6 "FAULT" 7 "WELD" 8 "TEST" 9 "SNA" 10 "DIAG" ;
VAL_ 1446 PMR_a039_DIS_status 0 "DISABLED" 1 "ENABLED" 2 "TEMPORARY_FAILURE" 3 "SNA" ;
VAL_ 1446 PMR_a040_PM_state 0 "STANDBY" 1 "DRIVE" 2 "SUPPORT" 3 "CHARGE" 4 "FEIM" 5 "CLEAR_FAULT" 6 "FAULT" 7 "WELD" 8 "TEST" 9 "SNA" 10 "DIAG" ;
VAL_ 1446 PMR_a017_EPBR_status 0 "DISABLED" 1 "ENABLED" 2 "TEMPORARY_FAILURE" 3 "SNA" ;
VAL_ 1446 PMR_a042_GTW_drivetrainType 0 "RWD" 1 "AWD" ;
VAL_ 1446 PMR_a064_UI_stoppingMode 0 "STANDARD" 1 "CREEP" 2 "HOLD" ;
VAL_ 1446 PMR_a010_DI_status 0 "DISABLED" 1 "ENABLED" 2 "TEMPORARY_FAILURE" 3 "SNA" ;
VAL_ 1446 PMR_a010_DI_systemStatus 0 "UNKNOWN" 1 "RELEASED" 2 "PARKED" 3 "DYNAMIC" 4 "PARKING" 5 "RELEASING" 6 "FAULT" 7 "FAULT_SECURE" 8 "MISMATCH" ;
VAL_ 1448 EPBR_alertID 0 "ALERT_DO_NOT_USE_ZERO" 1 "a001_DriverDoorOpen" 2 "a002_DoorOpen" 3 "a003_TrunkOpen" 4 "a004_FrunkOpen" 5 "a005_HeadlightsOnDoorOpen" 6 "a006_RemoteServiceAlert" 7 "a007_SoftPackConfigMismatch" 8 "a008_TouchScreenError" 9 "a009_SquashfsError" 10 "a010_MapsMissing" 11 "a011_IncorrectMap" 12 "a012_NotOnPrivateProperty" 13 "a013_TPMSHardWarning" 14 "a014_TPMSSoftWarning" 15 "a015_TPMSOverPressureWarning" 16 "a016_TPMSTemperatureWarning" 17 "a017_TPMSSystemFault" 18 "a018_SlipStartOn" 19 "a019_ParkBrakeFault" 20 "a020_SteeringReduced" 21 "a021_RearSeatbeltUnbuckled" 22 "a022_ApeFusesEtc" 23 "a023_CellInternetCheckFailed" 24 "a024_WifiInternetCheckFailed" 25 "a025_WifiOnlineCheckFailed" 26 "a026_ModemResetLoopDetected" 27 "a027_AutoSteerMIA" 28 "a028_FrontTrunkPopupClosed" 29 "a029_ModemMIA" 30 "a030_ModemVMCrash" 31 "a031_BrakeFluidLow" 32 "a032_CellModemRecoveryResets" 33 "a033_ApTrialExpired" 34 "a034_WakeupProblem" 35 "a035_AudioWatchdogKernelError" 36 "a036_AudioWatchdogHfpError" 37 "a037_AudioWatchdogXrunStormError" 38 "a038_AudioWatchdogA2bI2cLockupError" 39 "a039_AudioA2bNeedRediscovery" 40 "a040_HomelinkTransmit" 41 "a041_AudioDmesgXrun" 42 "a042_AudioDmesgRtThrottling" 43 "a043_InvalidMapDataOverride" 44 "a044_AudioDmesgDspException" 45 "a045_ECallNeedsService" 46 "a046_BackupCameraStreamError" 47 "a047_CellRoamingDisallowed" 48 "a048_AudioPremiumAmpCheckFailed" 49 "a049_BrakeShiftRequired" 50 "a050_BackupCameraIPUTimeout" 51 "a051_BackupCameraFrameTimeout" 52 "a052_KernelPanicReported" 53 "a053_QtCarExitError" 54 "a054_AudioBoostPowerBad" 55 "a055_ManualECallDisabled" 56 "a056_ManualECallButtonDisconnected" 57 "a057_CellAntennaDisconnected" 58 "a058_GPSAntennaDisconnected" 59 "a059_ECallSpeakerDisconnected" 60 "a060_ECallMicDisconnected" 61 "a061_SIMTestFailed" 62 "a062_ENSTestFailed" 63 "a063_CellularTestFailed" 64 "a064_ModemFirmwareTestFailed" 65 "a065_WiFiRecoveryReset" 66 "a066_GpuHangDetected" 67 "a067_WarnOnI915" 68 "a068_VideoUnexpectedExit" 69 "a069_VideoUDPTimeout" 70 "a070_VideoPipelineWarning" 71 "a071_VideoPipelineError" 72 "a072_ECallAnalogMicFailed" 73 "a073_ECallDigitalMicFailed" 74 "a074_EMMCHangDetected" 75 "a075_BackupCameraInitError" 76 "a076_NumFalseManualECalls" 77 "a077_AudioA2bMicChannelSwap" 78 "a078_DashcamUsbDriveUnmountable" 79 "a079_DashcamUsbDriveFull" 80 "a080_DashcamUsbDriveSlow" 81 "a081_CellModemSearchExpired" 82 "a082_NumModemRebootStuckInECall" 83 "a083_ECallProxyWatchdogTriggered" 84 "a084_SerializerError" 85 "a085_DeserializerError" 86 "a086_TouchEnumerationError" 87 "a087_BmpReset" 88 "a088_CellRemovableSimMissing" 89 "a089_RadioSoftResetError" 90 "a090_RadioPingFailError" 91 "a091_VehicleLinkStall" 92 "a092_updateStarted" 93 "a093_updateEnded" 94 "a094_ModemPowerOnFailure" 95 "a095_CidStorageRunningLow" 96 "a096_VideodPipelineIssueDetected" 97 "a097_AudiodRestarted" 98 "a098_DiskCheckFailure" 99 "a099_eMMCStatusError" 100 "a100_eMMCFTLError" 101 "a101_wifiStackProblem" 102 "a102_A2bDiscoveryFailed" 103 "a103_UsbHubNotEnumerating" 104 "a104_DashcamUsbDriveMissing" 105 "a105_firmwareReinstallRequested" 106 "a106_rebootBackstopTriggered" 107 "a107_DashcamUsbDriveTooBigForVfatFsck" 108 "a108_DashcamUsbDriveGettingFull" 109 "a109_DashcamUsbDriveTooSmall" 110 "a110_DashcamUsbDriveCorrupt" 111 "a111_DashcamUsbDriveWrongPort" 112 "a112_badUSBDevice" 113 "a113_DashcamHasOnboardSentryClips" ;
VAL_ 1448 EPBR_alertState 0 "CLEARED" 1 "SET" ;
VAL_ 1448 EPBR_a031_uds_bytes_0 0 "0" 1 "1" 2 "2" 3 "3" 4 "4" 5 "5" 6 "6" 7 "7" 8 "8" 9 "9" 10 "10" 11 "11" 12 "12" 13 "13" 14 "14" 15 "15" 16 "16" 17 "17" 18 "18" 19 "19" 20 "20" 21 "21" 22 "22" 23 "23" 24 "24" 25 "25" 26 "26" 27 "27" 28 "28" 29 "29" 30 "30" 31 "31" ;
VAL_ 1448 EPBR_a096_VEH_status 0 "DISABLED" 1 "ENABLED" 2 "TEMPORARY_FAILURE" 3 "SNA" ;
VAL_ 1448 EPBR_a101_VEH_state 0 "STANDBY" 1 "DRIVE" 2 "SUPPORT" 3 "CHARGE" 4 "FEIM" 5 "CLEAR_FAULT" 6 "FAULT" 7 "WELD" 8 "TEST" 9 "SNA" 10 "DIAG" ;
VAL_ 1448 EPBR_a109_PARTY_status 0 "DISABLED" 1 "ENABLED" 2 "TEMPORARY_FAILURE" 3 "SNA" ;
VAL_ 1448 EPBR_a114_PARTY_status 0 "DISABLED" 1 "ENABLED" 2 "TEMPORARY_FAILURE" 3 "SNA" ;
VAL_ 1448 EPBR_a185_summonFaultReason 0 "NONE" 1 "DI_MIA" 2 "DAS_MIA" 3 "ESP_MIA" 4 "EPBM_MIA" 5 "DI_FAULT" 6 "DI_APC_FAULT" 7 "DAS_FAULT" 8 "ESP_FAULT" 9 "VEH_CAN_FAULT" 10 "EAC_NOT_ALLOWED" 11 "EPBM_REQUEST" 12 "SPEED" 13 "EXTERNAL" 14 "PARK_MIA" 15 "PM_MIA" 16 "PM_REQUEST" 17 "OOC" 18 "MISMATCH" 19 "EPB_FAULT" 20 "DI_STATE_INVALID" 21 "PASSIVE_REQUEST" 22 "EPBREMOTE_MIA" 23 "REMOTE_SUMMON_FAULTED" 24 "LOCAL_UNIT_FAULTED" 25 "REMOTE_UNIT_FAULTED" 26 "START_IN_UNAVAILABLE" 27 "INVALID_REMOTE_STATE" 28 "REMOTE_DID_NOT_START" ;
VAL_ 1448 EPBR_a243_brakeMasterCylPress 1023 "SNA" ;
VAL_ 1448 EPBR_a250_esmSpeedClass 0 "STOPPED" 1 "SYSTEM_APPLY_OK" 2 "USER_APPLY_OK" 3 "FAST" 4 "UNKNOWN" ;
VAL_ 1448 EPBR_a301_setSpeed 4095 "SNA" ;
VAL_ 1448 EPBR_a362_brakeMasterCylPress 1023 "SNA" ;
VAL_ 1448 EPBR_a363_brakeMasterCylPress 1023 "SNA" ;
VAL_ 1448 EPBR_a089_PARTY_status 0 "DISABLED" 1 "ENABLED" 2 "TEMPORARY_FAILURE" 3 "SNA" ;
VAL_ 1448 EPBR_a090_VEH_state 0 "STANDBY" 1 "DRIVE" 2 "SUPPORT" 3 "CHARGE" 4 "FEIM" 5 "CLEAR_FAULT" 6 "FAULT" 7 "WELD" 8 "TEST" 9 "SNA" 10 "DIAG" ;
VAL_ 1448 EPBR_a095_PT_status 0 "DISABLED" 1 "ENABLED" 2 "TEMPORARY_FAILURE" 3 "SNA" ;
VAL_ 1448 EPBR_a096_CH_status 0 "DISABLED" 1 "ENABLED" 2 "TEMPORARY_FAILURE" 3 "SNA" ;
VAL_ 1448 EPBR_a097_VEH_state 0 "STANDBY" 1 "DRIVE" 2 "SUPPORT" 3 "CHARGE" 4 "FEIM" 5 "CLEAR_FAULT" 6 "FAULT" 7 "WELD" 8 "TEST" 9 "SNA" 10 "DIAG" ;
VAL_ 1448 EPBR_a111_VEH_status 0 "DISABLED" 1 "ENABLED" 2 "TEMPORARY_FAILURE" 3 "SNA" ;
VAL_ 1448 EPBR_a112_VEH_status 0 "DISABLED" 1 "ENABLED" 2 "TEMPORARY_FAILURE" 3 "SNA" ;
VAL_ 1448 EPBR_a120_VEH_systemStatus 0 "UNKNOWN" 1 "RELEASED" 2 "PARKED" 3 "DYNAMIC" 4 "PARKING" 5 "RELEASING" 6 "FAULT" 7 "FAULT_SECURE" 8 "MISMATCH" ;
VAL_ 1448 EPBR_a243_brakeMasterCylPressQF 0 "NOT_INITIALIZED" 1 "NORMAL" 2 "FAULTED" 3 "FAULTED2" ;
VAL_ 1448 EPBR_a086_VEH_status 0 "DISABLED" 1 "ENABLED" 2 "TEMPORARY_FAILURE" 3 "SNA" ;
VAL_ 1448 EPBR_a089_VEH_status 0 "DISABLED" 1 "ENABLED" 2 "TEMPORARY_FAILURE" 3 "SNA" ;
VAL_ 1448 EPBR_a091_VEH_state 0 "STANDBY" 1 "DRIVE" 2 "SUPPORT" 3 "CHARGE" 4 "FEIM" 5 "CLEAR_FAULT" 6 "FAULT" 7 "WELD" 8 "TEST" 9 "SNA" 10 "DIAG" ;
VAL_ 1448 EPBR_a098_VEH_status 0 "DISABLED" 1 "ENABLED" 2 "TEMPORARY_FAILURE" 3 "SNA" ;
VAL_ 1448 EPBR_a103_VEH_status 0 "DISABLED" 1 "ENABLED" 2 "TEMPORARY_FAILURE" 3 "SNA" ;
VAL_ 1448 EPBR_a104_LIPC_status 0 "DISABLED" 1 "ENABLED" 2 "TEMPORARY_FAILURE" 3 "SNA" ;
VAL_ 1448 EPBR_a107_VEH_status 0 "DISABLED" 1 "ENABLED" 2 "TEMPORARY_FAILURE" 3 "SNA" ;
VAL_ 1448 EPBR_a243_drivetrainType 0 "RWD" 1 "AWD" ;
VAL_ 1448 EPBR_a087_VEH_status 0 "DISABLED" 1 "ENABLED" 2 "TEMPORARY_FAILURE" 3 "SNA" ;
VAL_ 1448 EPBR_a088_VEH_status 0 "DISABLED" 1 "ENABLED" 2 "TEMPORARY_FAILURE" 3 "SNA" ;
VAL_ 1448 EPBR_a118_VEH_status 0 "DISABLED" 1 "ENABLED" 2 "TEMPORARY_FAILURE" 3 "SNA" ;
VAL_ 1448 EPBR_a120_PARTY_systemStatus 0 "UNKNOWN" 1 "RELEASED" 2 "PARKED" 3 "DYNAMIC" 4 "PARKING" 5 "RELEASING" 6 "FAULT" 7 "FAULT_SECURE" 8 "MISMATCH" ;
VAL_ 1448 EPBR_a089_BDY_status 0 "DISABLED" 1 "ENABLED" 2 "TEMPORARY_FAILURE" 3 "SNA" ;
VAL_ 1448 EPBR_a103_PT_status 0 "DISABLED" 1 "ENABLED" 2 "TEMPORARY_FAILURE" 3 "SNA" ;
VAL_ 1448 EPBR_a108_VEH_status 0 "DISABLED" 1 "ENABLED" 2 "TEMPORARY_FAILURE" 3 "SNA" ;
VAL_ 1448 EPBR_a109_VEH_status 0 "DISABLED" 1 "ENABLED" 2 "TEMPORARY_FAILURE" 3 "SNA" ;
VAL_ 1448 EPBR_a242_hvState 0 "DOWN" 1 "COMING_UP" 2 "GOING_DOWN" 3 "UP_FOR_DRIVE" 4 "UP_FOR_CHARGE" 5 "UP_FOR_DC_CHARGE" 6 "UP" ;
VAL_ 1448 EPBR_a087_PARTY_status 0 "DISABLED" 1 "ENABLED" 2 "TEMPORARY_FAILURE" 3 "SNA" ;
VAL_ 1448 EPBR_a088_PARTY_status 0 "DISABLED" 1 "ENABLED" 2 "TEMPORARY_FAILURE" 3 "SNA" ;
VAL_ 1448 EPBR_a089_CH_status 0 "DISABLED" 1 "ENABLED" 2 "TEMPORARY_FAILURE" 3 "SNA" ;
VAL_ 1448 EPBR_a086_VEH_systemStatus 0 "UNKNOWN" 1 "RELEASED" 2 "PARKED" 3 "DYNAMIC" 4 "PARKING" 5 "RELEASING" 6 "FAULT" 7 "FAULT_SECURE" 8 "MISMATCH" ;
VAL_ 1448 EPBR_a098_PARTY_status 0 "DISABLED" 1 "ENABLED" 2 "TEMPORARY_FAILURE" 3 "SNA" ;
VAL_ 1448 EPBR_a108_PARTY_status 0 "DISABLED" 1 "ENABLED" 2 "TEMPORARY_FAILURE" 3 "SNA" ;
VAL_ 1448 EPBR_a114_VEH_status 0 "DISABLED" 1 "ENABLED" 2 "TEMPORARY_FAILURE" 3 "SNA" ;
VAL_ 1448 EPBR_a243_vehicleSpeed 8191 "SNA" ;
VAL_ 1448 EPBR_a107_PT_status 0 "DISABLED" 1 "ENABLED" 2 "TEMPORARY_FAILURE" 3 "SNA" ;
VAL_ 1448 EPBR_a243_tempAmbient 0 "SNA" ;
VAL_ 1448 EPBR_a241_vehiclePowerState 0 "OFF" 1 "CONDITIONING" 2 "ACCESSORY" 3 "DRIVE" ;
VAL_ 1448 EPBR_a242_vehiclePowerState 0 "OFF" 1 "CONDITIONING" 2 "ACCESSORY" 3 "DRIVE" ;
VAL_ 1448 EPBR_a250_esmOperationTrigger 0 "PBUTTON_PRESSED_STOPPED" 1 "PBUTTON_PRESSED_OKTOPARK" 2 "PBUTTON_PRESSED_FAST" 3 "PBUTTON_PRESSED_UNKNOWN" 4 "PBUTTON_RELEASED" 5 "ACTIVE_PARK_REQUEST" 6 "DI_UNPARK" 7 "TOUCHSCREEN" 8 "WINCHMODE_EXIT" 9 "WINCHMODE_ENTER" 10 "WINCHMODE_UNAVAILABLE" 11 "SERVICE" 12 "DIAG_CLOSE" 13 "DIAG_OPEN" 14 "DIAG_EXIT" 15 "USER_CONFIRMED" 16 "USER_CANCEL" 17 "SPEED_STOPPED" 18 "SPEED_OKAYTOPARK" 19 "SPEED_FAST" 20 "TIMEOUT" 21 "SAVESTATE_ON_BOOT" 22 "REAPPLY" 23 "SUMMON_COMPLETE" 24 "FAULT" 25 "SUMMON_FAULT" 26 "DISQUALIFIED" 27 "EPBM_DISQUALIFIED" 28 "ACCELERATION" 29 "SYSTEM_APPLY" 30 "DRIVER_IS_LEAVING" 31 "AUTOPARK_END" ;
VAL_ 1448 EPBR_a112_PARTY_status 0 "DISABLED" 1 "ENABLED" 2 "TEMPORARY_FAILURE" 3 "SNA" ;
VAL_ 1448 EPBR_a118_VEH_systemStatus 0 "UNKNOWN" 1 "RELEASED" 2 "PARKED" 3 "DYNAMIC" 4 "PARKING" 5 "RELEASING" 6 "FAULT" 7 "FAULT_SECURE" 8 "MISMATCH" ;
VAL_ 1448 EPBR_a120_PARTY_status 0 "DISABLED" 1 "ENABLED" 2 "TEMPORARY_FAILURE" 3 "SNA" ;
VAL_ 1448 EPBR_a181_trailerDetected 0 "NOT_DETECTED" 1 "DETECTED" ;
VAL_ 1448 EPBR_a243_wiperSpeed 0 "SNA" 1 "OFF" 2 "1" 3 "2" 4 "3" 5 "4" 6 "5" 7 "LOW" 8 "HIGH" ;
VAL_ 1448 EPBR_a109_BDY_status 0 "DISABLED" 1 "ENABLED" 2 "TEMPORARY_FAILURE" 3 "SNA" ;
VAL_ 1448 EPBR_a111_PARTY_status 0 "DISABLED" 1 "ENABLED" 2 "TEMPORARY_FAILURE" 3 "SNA" ;
VAL_ 1448 EPBR_a112_CH_status 0 "DISABLED" 1 "ENABLED" 2 "TEMPORARY_FAILURE" 3 "SNA" ;
VAL_ 1448 EPBR_a243_vehiclePowerState 0 "OFF" 1 "CONDITIONING" 2 "ACCESSORY" 3 "DRIVE" ;
VAL_ 1448 EPBR_a110_CH_airbagCutoffStatus 0 "RCM_PASSENGER_AIRBAG_ENABLED" 1 "RCM_PASSENGER_AIRBAG_DISABLED" 3 "SNA" ;
VAL_ 1448 EPBR_a111_CH_status 0 "DISABLED" 1 "ENABLED" 2 "TEMPORARY_FAILURE" 3 "SNA" ;
VAL_ 1448 EPBR_a120_PT_systemStatus 0 "UNKNOWN" 1 "RELEASED" 2 "PARKED" 3 "DYNAMIC" 4 "PARKING" 5 "RELEASING" 6 "FAULT" 7 "FAULT_SECURE" 8 "MISMATCH" ;
VAL_ 1448 EPBR_a243_brakeDiscWipingActive 0 "INACTIVE" 1 "ACTIVE" ;
VAL_ 1448 EPBR_a104_CH_status 0 "DISABLED" 1 "ENABLED" 2 "TEMPORARY_FAILURE" 3 "SNA" ;
VAL_ 1448 EPBR_a104_PARTY_status 0 "DISABLED" 1 "ENABLED" 2 "TEMPORARY_FAILURE" 3 "SNA" ;
VAL_ 1448 EPBR_a263_esmSpeedClass 0 "STOPPED" 1 "SYSTEM_APPLY_OK" 2 "USER_APPLY_OK" 3 "FAST" 4 "UNKNOWN" ;
VAL_ 1448 EPBR_a114_BDY_status 0 "DISABLED" 1 "ENABLED" 2 "TEMPORARY_FAILURE" 3 "SNA" ;
VAL_ 1448 EPBR_a109_CH_status 0 "DISABLED" 1 "ENABLED" 2 "TEMPORARY_FAILURE" 3 "SNA" ;
VAL_ 1448 EPBR_a256_vehiclePowerState 0 "OFF" 1 "CONDITIONING" 2 "ACCESSORY" 3 "DRIVE" ;
VAL_ 1448 EPBR_a357_ambientTemp 4294966273 "SNA" ;
VAL_ 1448 EPBR_a358_ambientTemp 4294966273 "SNA" ;
VAL_ 1448 EPBR_a365_ambientTemp 4294966273 "SNA" ;
VAL_ 1448 EPBR_a366_ambientTemp 4294966273 "SNA" ;
VAL_ 1448 EPBR_a113_VEH_status 0 "DISABLED" 1 "ENABLED" 2 "TEMPORARY_FAILURE" 3 "SNA" ;
VAL_ 1448 EPBR_a116_VEH_status 0 "DISABLED" 1 "ENABLED" 2 "TEMPORARY_FAILURE" 3 "SNA" ;
VAL_ 1448 EPBR_a114_CH_status 0 "DISABLED" 1 "ENABLED" 2 "TEMPORARY_FAILURE" 3 "SNA" ;
VAL_ 1448 EPBR_a253_summonState 0 "INIT" 1 "IDLE" 2 "ARMED" 3 "ACTIVE" 4 "COMPLETE" 5 "FAULT" 6 "UNAVAILABLE" ;
VAL_ 1448 EPBR_a104_VEH_status 0 "DISABLED" 1 "ENABLED" 2 "TEMPORARY_FAILURE" 3 "SNA" ;
VAL_ 1448 EPBR_a117_VEH_status 0 "DISABLED" 1 "ENABLED" 2 "TEMPORARY_FAILURE" 3 "SNA" ;
VAL_ 1448 EPBR_a174_csmFaultReason 0 "NONE" 1 "EPBM_DISABLED" 2 "EPBM_FAULTED" 3 "STATE_MISMATCH" 4 "TIMEOUT_CALIBRATE" 5 "APPLY_BLOCKED" 6 "RELEASE_BLOCKED" 7 "TIMEOUT_APPLY_COMPLETE" 8 "TIMEOUT_APPLY_INRUSH" 9 "TIMEOUT_WAIT_FOR_CLAMP" 10 "TIMEOUT_RELEASE_INRUSH" 11 "TIMEOUT_RELEASE_WAIT_FOR_ENDSTOP" 12 "TIMEOUT_RELEASE_COMPLETE" 13 "TIMEOUT_EPBM_CUTOFF" 14 "TIMEOUT_NO_RAMP" 15 "TIMEOUT_EPBM_START" 16 "MOTOR_IDLE_FAULT" 17 "MOTOR_ACTIVE_FAULT" 18 "MOTOR_NOT_READY" 19 "EPBM_MIA" 20 "NVM_MISMATCH" 21 "REMOTE_MIA" ;
VAL_ 1448 EPBR_a175_csmFaultReason 0 "NONE" 1 "EPBM_DISABLED" 2 "EPBM_FAULTED" 3 "STATE_MISMATCH" 4 "TIMEOUT_CALIBRATE" 5 "APPLY_BLOCKED" 6 "RELEASE_BLOCKED" 7 "TIMEOUT_APPLY_COMPLETE" 8 "TIMEOUT_APPLY_INRUSH" 9 "TIMEOUT_WAIT_FOR_CLAMP" 10 "TIMEOUT_RELEASE_INRUSH" 11 "TIMEOUT_RELEASE_WAIT_FOR_ENDSTOP" 12 "TIMEOUT_RELEASE_COMPLETE" 13 "TIMEOUT_EPBM_CUTOFF" 14 "TIMEOUT_NO_RAMP" 15 "TIMEOUT_EPBM_START" 16 "MOTOR_IDLE_FAULT" 17 "MOTOR_ACTIVE_FAULT" 18 "MOTOR_NOT_READY" 19 "EPBM_MIA" 20 "NVM_MISMATCH" 21 "REMOTE_MIA" ;
VAL_ 1448 EPBR_a176_csmFaultReason 0 "NONE" 1 "EPBM_DISABLED" 2 "EPBM_FAULTED" 3 "STATE_MISMATCH" 4 "TIMEOUT_CALIBRATE" 5 "APPLY_BLOCKED" 6 "RELEASE_BLOCKED" 7 "TIMEOUT_APPLY_COMPLETE" 8 "TIMEOUT_APPLY_INRUSH" 9 "TIMEOUT_WAIT_FOR_CLAMP" 10 "TIMEOUT_RELEASE_INRUSH" 11 "TIMEOUT_RELEASE_WAIT_FOR_ENDSTOP" 12 "TIMEOUT_RELEASE_COMPLETE" 13 "TIMEOUT_EPBM_CUTOFF" 14 "TIMEOUT_NO_RAMP" 15 "TIMEOUT_EPBM_START" 16 "MOTOR_IDLE_FAULT" 17 "MOTOR_ACTIVE_FAULT" 18 "MOTOR_NOT_READY" 19 "EPBM_MIA" 20 "NVM_MISMATCH" 21 "REMOTE_MIA" ;
VAL_ 1448 EPBR_a177_csmFaultReason 0 "NONE" 1 "EPBM_DISABLED" 2 "EPBM_FAULTED" 3 "STATE_MISMATCH" 4 "TIMEOUT_CALIBRATE" 5 "APPLY_BLOCKED" 6 "RELEASE_BLOCKED" 7 "TIMEOUT_APPLY_COMPLETE" 8 "TIMEOUT_APPLY_INRUSH" 9 "TIMEOUT_WAIT_FOR_CLAMP" 10 "TIMEOUT_RELEASE_INRUSH" 11 "TIMEOUT_RELEASE_WAIT_FOR_ENDSTOP" 12 "TIMEOUT_RELEASE_COMPLETE" 13 "TIMEOUT_EPBM_CUTOFF" 14 "TIMEOUT_NO_RAMP" 15 "TIMEOUT_EPBM_START" 16 "MOTOR_IDLE_FAULT" 17 "MOTOR_ACTIVE_FAULT" 18 "MOTOR_NOT_READY" 19 "EPBM_MIA" 20 "NVM_MISMATCH" 21 "REMOTE_MIA" ;
VAL_ 1448 EPBR_a179_csmFaultReason 0 "NONE" 1 "EPBM_DISABLED" 2 "EPBM_FAULTED" 3 "STATE_MISMATCH" 4 "TIMEOUT_CALIBRATE" 5 "APPLY_BLOCKED" 6 "RELEASE_BLOCKED" 7 "TIMEOUT_APPLY_COMPLETE" 8 "TIMEOUT_APPLY_INRUSH" 9 "TIMEOUT_WAIT_FOR_CLAMP" 10 "TIMEOUT_RELEASE_INRUSH" 11 "TIMEOUT_RELEASE_WAIT_FOR_ENDSTOP" 12 "TIMEOUT_RELEASE_COMPLETE" 13 "TIMEOUT_EPBM_CUTOFF" 14 "TIMEOUT_NO_RAMP" 15 "TIMEOUT_EPBM_START" 16 "MOTOR_IDLE_FAULT" 17 "MOTOR_ACTIVE_FAULT" 18 "MOTOR_NOT_READY" 19 "EPBM_MIA" 20 "NVM_MISMATCH" 21 "REMOTE_MIA" ;
VAL_ 1448 EPBR_a183_esmOperationTrigger 0 "PBUTTON_PRESSED_STOPPED" 1 "PBUTTON_PRESSED_OKTOPARK" 2 "PBUTTON_PRESSED_FAST" 3 "PBUTTON_PRESSED_UNKNOWN" 4 "PBUTTON_RELEASED" 5 "ACTIVE_PARK_REQUEST" 6 "DI_UNPARK" 7 "TOUCHSCREEN" 8 "WINCHMODE_EXIT" 9 "WINCHMODE_ENTER" 10 "WINCHMODE_UNAVAILABLE" 11 "SERVICE" 12 "DIAG_CLOSE" 13 "DIAG_OPEN" 14 "DIAG_EXIT" 15 "USER_CONFIRMED" 16 "USER_CANCEL" 17 "SPEED_STOPPED" 18 "SPEED_OKAYTOPARK" 19 "SPEED_FAST" 20 "TIMEOUT" 21 "SAVESTATE_ON_BOOT" 22 "REAPPLY" 23 "SUMMON_COMPLETE" 24 "FAULT" 25 "SUMMON_FAULT" 26 "DISQUALIFIED" 27 "EPBM_DISQUALIFIED" 28 "ACCELERATION" 29 "SYSTEM_APPLY" 30 "DRIVER_IS_LEAVING" 31 "AUTOPARK_END" ;
VAL_ 1448 EPBR_a190_csmFaultReason 0 "NONE" 1 "EPBM_DISABLED" 2 "EPBM_FAULTED" 3 "STATE_MISMATCH" 4 "TIMEOUT_CALIBRATE" 5 "APPLY_BLOCKED" 6 "RELEASE_BLOCKED" 7 "TIMEOUT_APPLY_COMPLETE" 8 "TIMEOUT_APPLY_INRUSH" 9 "TIMEOUT_WAIT_FOR_CLAMP" 10 "TIMEOUT_RELEASE_INRUSH" 11 "TIMEOUT_RELEASE_WAIT_FOR_ENDSTOP" 12 "TIMEOUT_RELEASE_COMPLETE" 13 "TIMEOUT_EPBM_CUTOFF" 14 "TIMEOUT_NO_RAMP" 15 "TIMEOUT_EPBM_START" 16 "MOTOR_IDLE_FAULT" 17 "MOTOR_ACTIVE_FAULT" 18 "MOTOR_NOT_READY" 19 "EPBM_MIA" 20 "NVM_MISMATCH" 21 "REMOTE_MIA" ;
VAL_ 1448 EPBR_a191_csmFaultReason 0 "NONE" 1 "EPBM_DISABLED" 2 "EPBM_FAULTED" 3 "STATE_MISMATCH" 4 "TIMEOUT_CALIBRATE" 5 "APPLY_BLOCKED" 6 "RELEASE_BLOCKED" 7 "TIMEOUT_APPLY_COMPLETE" 8 "TIMEOUT_APPLY_INRUSH" 9 "TIMEOUT_WAIT_FOR_CLAMP" 10 "TIMEOUT_RELEASE_INRUSH" 11 "TIMEOUT_RELEASE_WAIT_FOR_ENDSTOP" 12 "TIMEOUT_RELEASE_COMPLETE" 13 "TIMEOUT_EPBM_CUTOFF" 14 "TIMEOUT_NO_RAMP" 15 "TIMEOUT_EPBM_START" 16 "MOTOR_IDLE_FAULT" 17 "MOTOR_ACTIVE_FAULT" 18 "MOTOR_NOT_READY" 19 "EPBM_MIA" 20 "NVM_MISMATCH" 21 "REMOTE_MIA" ;
VAL_ 1448 EPBR_a247_csmFaultReason 0 "NONE" 1 "EPBM_DISABLED" 2 "EPBM_FAULTED" 3 "STATE_MISMATCH" 4 "TIMEOUT_CALIBRATE" 5 "APPLY_BLOCKED" 6 "RELEASE_BLOCKED" 7 "TIMEOUT_APPLY_COMPLETE" 8 "TIMEOUT_APPLY_INRUSH" 9 "TIMEOUT_WAIT_FOR_CLAMP" 10 "TIMEOUT_RELEASE_INRUSH" 11 "TIMEOUT_RELEASE_WAIT_FOR_ENDSTOP" 12 "TIMEOUT_RELEASE_COMPLETE" 13 "TIMEOUT_EPBM_CUTOFF" 14 "TIMEOUT_NO_RAMP" 15 "TIMEOUT_EPBM_START" 16 "MOTOR_IDLE_FAULT" 17 "MOTOR_ACTIVE_FAULT" 18 "MOTOR_NOT_READY" 19 "EPBM_MIA" 20 "NVM_MISMATCH" 21 "REMOTE_MIA" ;
VAL_ 1448 EPBR_a248_csmFaultReason 0 "NONE" 1 "EPBM_DISABLED" 2 "EPBM_FAULTED" 3 "STATE_MISMATCH" 4 "TIMEOUT_CALIBRATE" 5 "APPLY_BLOCKED" 6 "RELEASE_BLOCKED" 7 "TIMEOUT_APPLY_COMPLETE" 8 "TIMEOUT_APPLY_INRUSH" 9 "TIMEOUT_WAIT_FOR_CLAMP" 10 "TIMEOUT_RELEASE_INRUSH" 11 "TIMEOUT_RELEASE_WAIT_FOR_ENDSTOP" 12 "TIMEOUT_RELEASE_COMPLETE" 13 "TIMEOUT_EPBM_CUTOFF" 14 "TIMEOUT_NO_RAMP" 15 "TIMEOUT_EPBM_START" 16 "MOTOR_IDLE_FAULT" 17 "MOTOR_ACTIVE_FAULT" 18 "MOTOR_NOT_READY" 19 "EPBM_MIA" 20 "NVM_MISMATCH" 21 "REMOTE_MIA" ;
VAL_ 1448 EPBR_a104_BDY_status 0 "DISABLED" 1 "ENABLED" 2 "TEMPORARY_FAILURE" 3 "SNA" ;
VAL_ 1448 EPBR_a182_trailerDetected 0 "NOT_DETECTED" 1 "DETECTED" ;
VAL_ 1448 EPBR_a365_trailerDetected 0 "NOT_DETECTED" 1 "DETECTED" ;
VAL_ 1448 EPBR_a366_trailerDetected 0 "NOT_DETECTED" 1 "DETECTED" ;
VAL_ 1448 EPBR_a198_learnedEpbConfig 0 "UNKNOWN" 1 "MODEL3_BASE" 2 "MODEL3_PERFORMANCE" 3 "MODELS_BASE" 4 "MODELY_BASE" 5 "MODELY_PERFORMANCE" 6 "MODELX_BASE" 7 "MODEL3_PERFORMANCE_V2" 8 "MODELY_PERFORMANCE_V2" 9 "MODELS_CERAMIC" ;
VAL_ 1448 EPBR_a198_ambientTemp 4294966273 "SNA" ;
VAL_ 1448 EPBR_a357_trailerDetected 0 "NOT_DETECTED" 1 "DETECTED" ;
VAL_ 1448 EPBR_a358_trailerDetected 0 "NOT_DETECTED" 1 "DETECTED" ;
VAL_ 1448 EPBR_a198_version 254 "LOCAL_BUILD" 255 "SNA" ;
VAL_ 1467 SDCR_matrixIndex 0 "AlertMatrix0" 1 "AlertMatrix1" 2 "AlertMatrix2" ;
